VERSION "dbc-export 1 2026.26.6.5"

NS_ :

BS_:

BU_: DAS DI DIF DIR EPAS3P ESP IBST PM PMF PMR RCM VCBATT0 VCCC VCFRONT VCLEFT VCRIGHT

BO_ 914 EPAS3P_alertMatrix: 8 EPAS3P
 SG_ EPAS3P_matrixIndex M : 0|4@1+ (1,0) [0|15] "" Vector__XXX
 SG_ EPAS3P_a001_sent1Mia m0 : 4|1@1+ (1,0) [0|1] "" Vector__XXX
 SG_ EPAS3P_a002_sent1Error m0 : 5|1@1+ (1,0) [0|1] "" Vector__XXX
 SG_ EPAS3P_a003_trqSens1Supply m0 : 6|1@1+ (1,0) [0|1] "" Vector__XXX
 SG_ EPAS3P_a004_trqSens1Eeprom m0 : 7|1@1+ (1,0) [0|1] "" Vector__XXX
 SG_ EPAS3P_a005_sent2Mia m0 : 8|1@1+ (1,0) [0|1] "" Vector__XXX
 SG_ EPAS3P_a006_sent2Error m0 : 9|1@1+ (1,0) [0|1] "" Vector__XXX
 SG_ EPAS3P_a007_trqSens2Supply m0 : 10|1@1+ (1,0) [0|1] "" Vector__XXX
 SG_ EPAS3P_a008_trqSens2Eeprom m0 : 11|1@1+ (1,0) [0|1] "" Vector__XXX
 SG_ EPAS3P_a009_sentDiff m0 : 12|1@1+ (1,0) [0|1] "" Vector__XXX
 SG_ EPAS3P_a010_trqSensCalError m0 : 13|1@1+ (1,0) [0|1] "" Vector__XXX
 SG_ EPAS3P_a011_currentSensError m0 : 14|1@1+ (1,0) [0|1] "" Vector__XXX
 SG_ EPAS3P_a012_currentSensCalError m0 : 15|1@1+ (1,0) [0|1] "" Vector__XXX
 SG_ EPAS3P_a013_gateDriveError m0 : 16|1@1+ (1,0) [0|1] "" Vector__XXX
 SG_ EPAS3P_a014_gateDriveTxError m0 : 17|1@1+ (1,0) [0|1] "" Vector__XXX
 SG_ EPAS3P_a015_gateDriveEeprom m0 : 18|1@1+ (1,0) [0|1] "" Vector__XXX
 SG_ EPAS3P_a016_phaseUhighUv m0 : 19|1@1+ (1,0) [0|1] "" Vector__XXX
 SG_ EPAS3P_a017_phaseUlowUv m0 : 20|1@1+ (1,0) [0|1] "" Vector__XXX
 SG_ EPAS3P_a018_phaseVhighUv m0 : 21|1@1+ (1,0) [0|1] "" Vector__XXX
 SG_ EPAS3P_a019_phaseVlowUv m0 : 22|1@1+ (1,0) [0|1] "" Vector__XXX
 SG_ EPAS3P_a020_phaseWhighUv m0 : 23|1@1+ (1,0) [0|1] "" Vector__XXX
 SG_ EPAS3P_a021_phaseWlowUv m0 : 24|1@1+ (1,0) [0|1] "" Vector__XXX
 SG_ EPAS3P_a022_phaseUhighOv m0 : 25|1@1+ (1,0) [0|1] "" Vector__XXX
 SG_ EPAS3P_a023_phaseUlowOv m0 : 26|1@1+ (1,0) [0|1] "" Vector__XXX
 SG_ EPAS3P_a024_phaseVhighOv m0 : 27|1@1+ (1,0) [0|1] "" Vector__XXX
 SG_ EPAS3P_a025_phaseVlowOv m0 : 28|1@1+ (1,0) [0|1] "" Vector__XXX
 SG_ EPAS3P_a026_phaseWhighOv m0 : 29|1@1+ (1,0) [0|1] "" Vector__XXX
 SG_ EPAS3P_a027_phaseWlowOv m0 : 30|1@1+ (1,0) [0|1] "" Vector__XXX
 SG_ EPAS3P_a028_phaseUbootUv m0 : 31|1@1+ (1,0) [0|1] "" Vector__XXX
 SG_ EPAS3P_a029_phaseVbootUv m0 : 32|1@1+ (1,0) [0|1] "" Vector__XXX
 SG_ EPAS3P_a030_phaseWbootUv m0 : 33|1@1+ (1,0) [0|1] "" Vector__XXX
 SG_ EPAS3P_a031_abnormalShutdown m0 : 34|1@1+ (1,0) [0|1] "" Vector__XXX
 SG_ EPAS3P_a032_vRegOutputUv m0 : 35|1@1+ (1,0) [0|1] "" Vector__XXX
 SG_ EPAS3P_a033_vRegOutputOv m0 : 36|1@1+ (1,0) [0|1] "" Vector__XXX
 SG_ EPAS3P_a034_vRegError m0 : 37|1@1+ (1,0) [0|1] "" Vector__XXX
 SG_ EPAS3P_a035_vbbSupplyUv m0 : 38|1@1+ (1,0) [0|1] "" Vector__XXX
 SG_ EPAS3P_a036_vbbSupplyOv m0 : 39|1@1+ (1,0) [0|1] "" Vector__XXX
 SG_ EPAS3P_a037_motPos1ParityError m0 : 40|1@1+ (1,0) [0|1] "" Vector__XXX
 SG_ EPAS3P_a038_motPos1Uv m0 : 41|1@1+ (1,0) [0|1] "" Vector__XXX
 SG_ EPAS3P_a039_motPos1MagnetMia m0 : 42|1@1+ (1,0) [0|1] "" Vector__XXX
 SG_ EPAS3P_a040_motPos1LogicError m0 : 43|1@1+ (1,0) [0|1] "" Vector__XXX
 SG_ EPAS3P_a041_motPos1tempError m0 : 44|1@1+ (1,0) [0|1] "" Vector__XXX
 SG_ EPAS3P_a042_motPos2ParityError m0 : 45|1@1+ (1,0) [0|1] "" Vector__XXX
 SG_ EPAS3P_a043_motPos2Uv m0 : 46|1@1+ (1,0) [0|1] "" Vector__XXX
 SG_ EPAS3P_a044_motPos2MagnetMia m0 : 47|1@1+ (1,0) [0|1] "" Vector__XXX
 SG_ EPAS3P_a045_motPos2LogicError m0 : 48|1@1+ (1,0) [0|1] "" Vector__XXX
 SG_ EPAS3P_a046_motPos2tempError m0 : 49|1@1+ (1,0) [0|1] "" Vector__XXX
 SG_ EPAS3P_a047_motPosCorrError m0 : 50|1@1+ (1,0) [0|1] "" Vector__XXX
 SG_ EPAS3P_a048_motPosCalError m0 : 51|1@1+ (1,0) [0|1] "" Vector__XXX
 SG_ EPAS3P_a049_piCtrlError m0 : 52|1@1+ (1,0) [0|1] "" Vector__XXX
 SG_ EPAS3P_a050_mcuSmuError m0 : 53|1@1+ (1,0) [0|1] "" Vector__XXX
 SG_ EPAS3P_a051_mcuSupError m0 : 54|1@1+ (1,0) [0|1] "" Vector__XXX
 SG_ EPAS3P_a052_intWatchdogError m0 : 55|1@1+ (1,0) [0|1] "" Vector__XXX
 SG_ EPAS3P_a053_extWatchdogError m0 : 56|1@1+ (1,0) [0|1] "" Vector__XXX
 SG_ EPAS3P_a054_memoryProtectError m0 : 57|1@1+ (1,0) [0|1] "" Vector__XXX
 SG_ EPAS3P_a055_floatPointError m0 : 58|1@1+ (1,0) [0|1] "" Vector__XXX
 SG_ EPAS3P_a056_battUv m0 : 59|1@1+ (1,0) [0|1] "" Vector__XXX
 SG_ EPAS3P_a057_battUvReduced m0 : 60|1@1+ (1,0) [0|1] "" Vector__XXX
 SG_ EPAS3P_a058_battOv m0 : 61|1@1+ (1,0) [0|1] "" Vector__XXX
 SG_ EPAS3P_a059_battOvReduced m0 : 62|1@1+ (1,0) [0|1] "" Vector__XXX
 SG_ EPAS3P_a060_battBridgeDiff m0 : 63|1@1+ (1,0) [0|1] "" Vector__XXX
 SG_ EPAS3P_a061_bridgeUv m1 : 4|1@1+ (1,0) [0|1] "" Vector__XXX
 SG_ EPAS3P_a062_assistCorrError m1 : 5|1@1+ (1,0) [0|1] "" Vector__XXX
 SG_ EPAS3P_a063_dampCorrError m1 : 6|1@1+ (1,0) [0|1] "" Vector__XXX
 SG_ EPAS3P_a064_phaseCompCorrError m1 : 7|1@1+ (1,0) [0|1] "" Vector__XXX
 SG_ EPAS3P_a065_trqTarCorrError m1 : 8|1@1+ (1,0) [0|1] "" Vector__XXX
 SG_ EPAS3P_a066_returnCorrError m1 : 9|1@1+ (1,0) [0|1] "" Vector__XXX
 SG_ EPAS3P_a067_yawDampCorrError m1 : 10|1@1+ (1,0) [0|1] "" Vector__XXX
 SG_ EPAS3P_a068_hystCorrError m1 : 11|1@1+ (1,0) [0|1] "" Vector__XXX
 SG_ EPAS3P_a069_eacCorrError m1 : 12|1@1+ (1,0) [0|1] "" Vector__XXX
 SG_ EPAS3P_a070_hodCorrError m1 : 13|1@1+ (1,0) [0|1] "" Vector__XXX
 SG_ EPAS3P_a071_vehSpdCorrError m1 : 14|1@1+ (1,0) [0|1] "" Vector__XXX
 SG_ EPAS3P_a072_motFeedFwdError m1 : 15|1@1+ (1,0) [0|1] "" Vector__XXX
 SG_ EPAS3P_a073_motParEstError m1 : 16|1@1+ (1,0) [0|1] "" Vector__XXX
 SG_ EPAS3P_a074_overHeatProtect m1 : 17|1@1+ (1,0) [0|1] "" Vector__XXX
 SG_ EPAS3P_a075_fspPwrCut m1 : 18|1@1+ (1,0) [0|1] "" Vector__XXX
 SG_ EPAS3P_a076_tempSensOutofRange m1 : 19|1@1+ (1,0) [0|1] "" Vector__XXX
 SG_ EPAS3P_a077_highSideFetError m1 : 20|1@1+ (1,0) [0|1] "" Vector__XXX
 SG_ EPAS3P_a078_phaseDisconnectError m1 : 21|1@1+ (1,0) [0|1] "" Vector__XXX
 SG_ EPAS3P_a079_backupCurrentPlaus m1 : 22|1@1+ (1,0) [0|1] "" Vector__XXX
 SG_ EPAS3P_a080_ecuInitArbError m1 : 23|1@1+ (1,0) [0|1] "" Vector__XXX
 SG_ EPAS3P_a081_coggCompError m1 : 24|1@1+ (1,0) [0|1] "" Vector__XXX
 SG_ EPAS3P_a082_polarityCalError m1 : 25|1@1+ (1,0) [0|1] "" Vector__XXX
 SG_ EPAS3P_a083_crcMismatch m1 : 26|1@1+ (1,0) [0|1] "" Vector__XXX
 SG_ EPAS3P_a084_eacCancelled m1 : 27|1@1+ (1,0) [0|1] "" Vector__XXX
 SG_ EPAS3P_a085_canBusOff m1 : 28|1@1+ (1,0) [0|1] "" Vector__XXX
 SG_ EPAS3P_a086_dasMia m1 : 29|1@1+ (1,0) [0|1] "" Vector__XXX
 SG_ EPAS3P_a087_dasCntError m1 : 30|1@1+ (1,0) [0|1] "" Vector__XXX
 SG_ EPAS3P_a088_dasCsError m1 : 31|1@1+ (1,0) [0|1] "" Vector__XXX
 SG_ EPAS3P_a089_espWsMia m1 : 32|1@1+ (1,0) [0|1] "" Vector__XXX
 SG_ EPAS3P_a090_espWsCntError m1 : 33|1@1+ (1,0) [0|1] "" Vector__XXX
 SG_ EPAS3P_a091_espWsCsError m1 : 34|1@1+ (1,0) [0|1] "" Vector__XXX
 SG_ EPAS3P_a092_espWrMia m1 : 35|1@1+ (1,0) [0|1] "" Vector__XXX
 SG_ EPAS3P_a093_espWrCntError m1 : 36|1@1+ (1,0) [0|1] "" Vector__XXX
 SG_ EPAS3P_a094_espWrCsError m1 : 37|1@1+ (1,0) [0|1] "" Vector__XXX
 SG_ EPAS3P_a095_espWsStatus m1 : 38|1@1+ (1,0) [0|1] "" Vector__XXX
 SG_ EPAS3P_a096_rcmMia m1 : 39|1@1+ (1,0) [0|1] "" Vector__XXX
 SG_ EPAS3P_a097_rcmCntError m1 : 40|1@1+ (1,0) [0|1] "" Vector__XXX
 SG_ EPAS3P_a098_rcmCsError m1 : 41|1@1+ (1,0) [0|1] "" Vector__XXX
 SG_ EPAS3P_a099_yawRateStatus m1 : 42|1@1+ (1,0) [0|1] "" Vector__XXX
 SG_ EPAS3P_a100_diMia m1 : 43|1@1+ (1,0) [0|1] "" Vector__XXX
 SG_ EPAS3P_a101_diCntError m1 : 44|1@1+ (1,0) [0|1] "" Vector__XXX
 SG_ EPAS3P_a102_diCsError m1 : 45|1@1+ (1,0) [0|1] "" Vector__XXX
 SG_ EPAS3P_a103_vcFrontMia m1 : 46|1@1+ (1,0) [0|1] "" Vector__XXX
 SG_ EPAS3P_a104_vcFrontCntError m1 : 47|1@1+ (1,0) [0|1] "" Vector__XXX
 SG_ EPAS3P_a105_vcFrontCsError m1 : 48|1@1+ (1,0) [0|1] "" Vector__XXX
 SG_ EPAS3P_a106_vcFrontTempMia m1 : 49|1@1+ (1,0) [0|1] "" Vector__XXX
 SG_ EPAS3P_a107_uiTuneReqMia m1 : 50|1@1+ (1,0) [0|1] "" Vector__XXX
 SG_ EPAS3P_a108_uiTuneReqCntError m1 : 51|1@1+ (1,0) [0|1] "" Vector__XXX
 SG_ EPAS3P_a109_uiTuneReqCsError m1 : 52|1@1+ (1,0) [0|1] "" Vector__XXX
 SG_ EPAS3P_a110_sasMia m1 : 53|1@1+ (1,0) [0|1] "" Vector__XXX
 SG_ EPAS3P_a111_sasCntError m1 : 54|1@1+ (1,0) [0|1] "" Vector__XXX
 SG_ EPAS3P_a112_sasCsError m1 : 55|1@1+ (1,0) [0|1] "" Vector__XXX
 SG_ EPAS3P_a113_sasStatusError m1 : 56|1@1+ (1,0) [0|1] "" Vector__XXX
 SG_ EPAS3P_a114_gtwConfigMia m1 : 57|1@1+ (1,0) [0|1] "" Vector__XXX
 SG_ EPAS3P_a115_ecuStatMia m1 : 58|1@1+ (1,0) [0|1] "" Vector__XXX
 SG_ EPAS3P_a116_ecuStatCntError m1 : 59|1@1+ (1,0) [0|1] "" Vector__XXX
 SG_ EPAS3P_a117_ecuStatCrcError m1 : 60|1@1+ (1,0) [0|1] "" Vector__XXX
 SG_ EPAS3P_a118_privateBusOff m1 : 61|1@1+ (1,0) [0|1] "" Vector__XXX
 SG_ EPAS3P_a119_pvtEcuStatMia m1 : 62|1@1+ (1,0) [0|1] "" Vector__XXX
 SG_ EPAS3P_a120_pvtEcuStatCntError m1 : 63|1@1+ (1,0) [0|1] "" Vector__XXX
 SG_ EPAS3P_a121_pvtEcuStatCrcError m2 : 4|1@1+ (1,0) [0|1] "" Vector__XXX
 SG_ EPAS3P_a122_olpActive m2 : 5|1@1+ (1,0) [0|1] "" Vector__XXX
 SG_ EPAS3P_a123_combEcu2StatFail m2 : 6|1@1+ (1,0) [0|1] "" Vector__XXX
 SG_ EPAS3P_a124_tempSensStuckInRange m2 : 7|1@1+ (1,0) [0|1] "" Vector__XXX
 SG_ EPAS3P_a125_trqSensTrimOutRange m2 : 8|1@1+ (1,0) [0|1] "" Vector__XXX
 SG_ EPAS3P_a126_apsMia m2 : 9|1@1+ (1,0) [0|1] "" Vector__XXX
 SG_ EPAS3P_a127_apsCntError m2 : 10|1@1+ (1,0) [0|1] "" Vector__XXX
 SG_ EPAS3P_a128_apsCsError m2 : 11|1@1+ (1,0) [0|1] "" Vector__XXX
 SG_ EPAS3P_a129_combEcu1StatFail m2 : 12|1@1+ (1,0) [0|1] "" Vector__XXX
 SG_ EPAS3P_a130_sasOffsetNotCal m2 : 13|1@1+ (1,0) [0|1] "" Vector__XXX
 SG_ EPAS3P_a131_phaseFeedbackError m2 : 14|1@1+ (1,0) [0|1] "" Vector__XXX
 SG_ EPAS3P_a132_motFeedFwdCounter25 m2 : 15|1@1+ (1,0) [0|1] "" Vector__XXX
 SG_ EPAS3P_a133_motFeedFwdCounter50 m2 : 16|1@1+ (1,0) [0|1] "" Vector__XXX
 SG_ EPAS3P_a134_motFeedFwdCounter85 m2 : 17|1@1+ (1,0) [0|1] "" Vector__XXX
 SG_ EPAS3P_a135_piCtrlCounter25 m2 : 18|1@1+ (1,0) [0|1] "" Vector__XXX
 SG_ EPAS3P_a136_piCtrlCounter50 m2 : 19|1@1+ (1,0) [0|1] "" Vector__XXX
 SG_ EPAS3P_a137_piCtrlCounter85 m2 : 20|1@1+ (1,0) [0|1] "" Vector__XXX
 SG_ EPAS3P_a144_diSpdMia m2 : 21|1@1+ (1,0) [0|1] "" Vector__XXX
 SG_ EPAS3P_a145_diSpdCntError m2 : 22|1@1+ (1,0) [0|1] "" Vector__XXX
 SG_ EPAS3P_a146_diSpdCsError m2 : 23|1@1+ (1,0) [0|1] "" Vector__XXX
 SG_ EPAS3P_a147_backupVehSpeed m2 : 24|1@1+ (1,0) [0|1] "" Vector__XXX
 SG_ EPAS3P_a148_vMaxAssist m2 : 25|1@1+ (1,0) [0|1] "" Vector__XXX
 SG_ EPAS3P_a149_currentSensPathSwitc m2 : 26|1@1+ (1,0) [0|1] "" Vector__XXX
 SG_ EPAS3P_a150_currentSensOffsetDet m2 : 27|1@1+ (1,0) [0|1] "" Vector__XXX
 SG_ EPAS3P_a151_dcsCboot m2 : 28|1@1+ (1,0) [0|1] "" Vector__XXX
 SG_ EPAS3P_a152_dcsDiagReg m2 : 29|1@1+ (1,0) [0|1] "" Vector__XXX
 SG_ EPAS3P_a153_dcsInitOffset m2 : 30|1@1+ (1,0) [0|1] "" Vector__XXX
 SG_ EPAS3P_a154_assistTorqueDisabled m2 : 31|1@1+ (1,0) [0|1] "" Vector__XXX
 SG_ EPAS3P_a155_backupEacActive m2 : 32|1@1+ (1,0) [0|1] "" Vector__XXX
 SG_ EPAS3P_a156_angleSensorDivergenc m2 : 33|1@1+ (1,0) [0|1] "" Vector__XXX
 SG_ EPAS3P_a157_pmState2Mia m2 : 34|1@1+ (1,0) [0|1] "" Vector__XXX
 SG_ EPAS3P_a158_pmState2CntError m2 : 35|1@1+ (1,0) [0|1] "" Vector__XXX
 SG_ EPAS3P_a159_pmState2CsError m2 : 36|1@1+ (1,0) [0|1] "" Vector__XXX
 SG_ EPAS3P_a160_latentFaultTestResul m2 : 37|1@1+ (1,0) [0|1] "" Vector__XXX
 SG_ EPAS3P_a161_initTestPhaDisconnIn m2 : 38|1@1+ (1,0) [0|1] "" Vector__XXX
 SG_ EPAS3P_a162_initTestHSDFetInfo m2 : 39|1@1+ (1,0) [0|1] "" Vector__XXX
 SG_ EPAS3P_a163_initTestGateDrvrInfo m2 : 40|1@1+ (1,0) [0|1] "" Vector__XXX
 SG_ EPAS3P_a164_initTestDCSInfo m2 : 41|1@1+ (1,0) [0|1] "" Vector__XXX
 SG_ EPAS3P_a165_epbStatusMia m2 : 42|1@1+ (1,0) [0|1] "" Vector__XXX
 SG_ EPAS3P_a166_epbStatusCntError m2 : 43|1@1+ (1,0) [0|1] "" Vector__XXX
 SG_ EPAS3P_a167_epbStatusCsError m2 : 44|1@1+ (1,0) [0|1] "" Vector__XXX
 SG_ EPAS3P_a168_torsionBarTorqueQfDe m2 : 45|1@1+ (1,0) [0|1] "" Vector__XXX
 SG_ EPAS3P_a169_difMia m2 : 46|1@1+ (1,0) [0|1] "" Vector__XXX
 SG_ EPAS3P_a170_difCntError m2 : 47|1@1+ (1,0) [0|1] "" Vector__XXX
 SG_ EPAS3P_a171_difCsError m2 : 48|1@1+ (1,0) [0|1] "" Vector__XXX

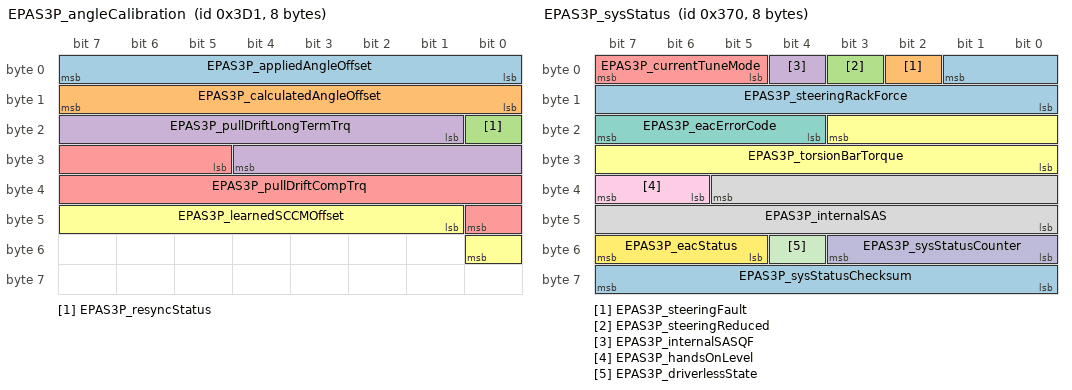
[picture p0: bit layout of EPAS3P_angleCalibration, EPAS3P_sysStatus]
BO_ 977 EPAS3P_angleCalibration: 8 EPAS3P
 SG_ EPAS3P_appliedAngleOffset : 0|8@1+ (0.1,-12.8) [-12.8|12.7] "deg" Vector__XXX
 SG_ EPAS3P_calculatedAngleOffset : 8|8@1+ (0.1,-12.8) [-12.8|12.7] "deg" Vector__XXX
 SG_ EPAS3P_resyncStatus : 16|1@1+ (1,0) [0|1] "" Vector__XXX
 SG_ EPAS3P_pullDriftLongTermTrq : 17|12@1+ (0.01,-10) [-10|10] "Nm" Vector__XXX
 SG_ EPAS3P_pullDriftCompTrq : 29|12@1+ (0.01,-10) [-10|10] "Nm" Vector__XXX
 SG_ EPAS3P_learnedSCCMOffset : 41|8@1+ (0.1,-12.8) [-12.8|12.7] "deg" Vector__XXX

BO_ 817 EPAS3P_info: 8 EPAS3P
 SG_ EPAS3P_infoIndex M : 0|8@1+ (1,0) [0|255] "" Vector__XXX
 SG_ EPAS3P_infoBuildType m10 : 8|8@1+ (1,0) [0|255] "" Vector__XXX
 SG_ EPAS3P_infoComponentID m10 : 48|16@1+ (1,0) [0|65535] "" Vector__XXX
 SG_ EPAS3P_infoPcbaID m11 : 16|8@1+ (1,0) [0|255] "" Vector__XXX
 SG_ EPAS3P_infoAssemblyID m11 : 24|8@1+ (1,0) [0|255] "" Vector__XXX
 SG_ EPAS3P_infoUsageID m11 : 32|16@1+ (1,0) [0|65535] "" Vector__XXX
 SG_ EPAS3P_infoApplicationCRC m13 : 32|32@1+ (1,0) [0|4294967295] "" Vector__XXX
 SG_ EPAS3P_infoBootUdsProtoVersion m20 : 8|8@1+ (1,0) [0|255] "" Vector__XXX
 SG_ EPAS3P_infoBootloaderCRC m20 : 32|32@1+ (1,0) [0|4294967295] "" Vector__XXX
 SG_ EPAS3P_infoSubcomponent2 m23 : 32|32@1+ (1,0) [0|4294967295] "" Vector__XXX

BO_ 880 EPAS3P_sysStatus: 8 EPAS3P
 SG_ EPAS3P_steeringRackForce : 1|10@0+ (50,-25575) [-25575|25525] "N" Vector__XXX
 SG_ EPAS3P_steeringFault : 2|1@1+ (1,0) [0|1] "" Vector__XXX
 SG_ EPAS3P_steeringReduced : 3|1@1+ (1,0) [0|1] "" Vector__XXX
 SG_ EPAS3P_internalSASQF : 4|1@1+ (1,0) [0|1] "" Vector__XXX
 SG_ EPAS3P_currentTuneMode : 5|3@1+ (1,0) [0|7] "" Vector__XXX
 SG_ EPAS3P_torsionBarTorque : 19|12@0+ (0.01,-20.5) [-20.5|20.44] "Nm" Vector__XXX
 SG_ EPAS3P_eacErrorCode : 20|4@1+ (1,0) [0|14] "" Vector__XXX
 SG_ EPAS3P_internalSAS : 37|14@0+ (0.1,-819.2) [-819.2|819] "deg" Vector__XXX
 SG_ EPAS3P_handsOnLevel : 38|2@1+ (1,0) [0|3] "" Vector__XXX
 SG_ EPAS3P_sysStatusCounter : 48|4@1+ (1,0) [0|15] "" Vector__XXX
 SG_ EPAS3P_driverlessState : 52|1@1+ (1,0) [0|1] "" Vector__XXX
 SG_ EPAS3P_eacStatus : 53|3@1+ (1,0) [0|7] "" Vector__XXX
 SG_ EPAS3P_sysStatusChecksum : 56|8@1+ (1,0) [0|255] "" Vector__XXX

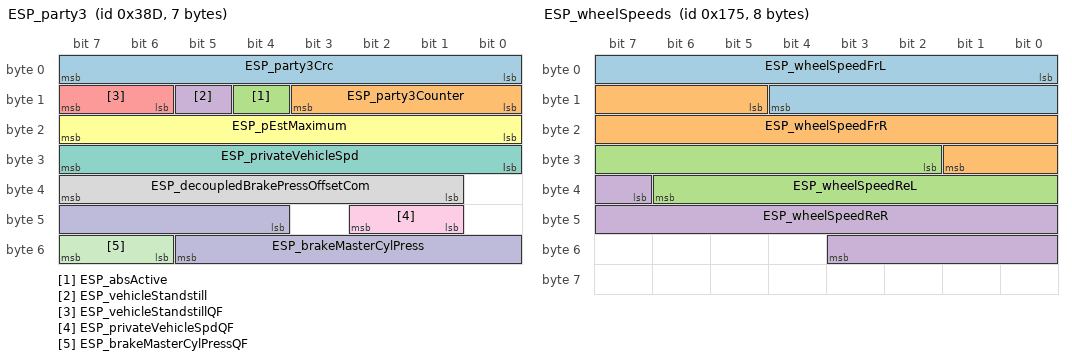
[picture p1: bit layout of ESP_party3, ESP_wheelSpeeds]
BO_ 909 ESP_party3: 7 ESP
 SG_ ESP_party3Crc : 0|8@1+ (1,0) [0|255] "" Vector__XXX
 SG_ ESP_party3Counter : 8|4@1+ (1,0) [0|15] "" Vector__XXX
 SG_ ESP_absActive : 12|1@1+ (1,0) [0|1] "" Vector__XXX
 SG_ ESP_vehicleStandstill : 13|1@1+ (1,0) [0|1] "" Vector__XXX
 SG_ ESP_vehicleStandstillQF : 14|2@1+ (1,0) [0|3] "" Vector__XXX
 SG_ ESP_pEstMaximum : 16|8@1+ (1,0) [0|255] "bar" Vector__XXX
 SG_ ESP_privateVehicleSpd : 24|8@1+ (0.4,0) [0|102] "m/s" Vector__XXX
 SG_ ESP_decoupledBrakePressOffsetCom : 33|7@1+ (0.25,-16) [-16|15.5] "bar" Vector__XXX
 SG_ ESP_privateVehicleSpdQF : 41|2@1+ (1,0) [0|3] "" Vector__XXX
 SG_ ESP_brakeMasterCylPress : 44|10@1+ (0.3,-30) [-30|276.6] "bar" Vector__XXX
 SG_ ESP_brakeMasterCylPressQF : 54|2@1+ (1,0) [0|3] "" Vector__XXX

BO_ 325 ESP_status: 8 ESP
 SG_ ESP_statusChecksum : 0|8@1+ (1,0) [0|255] "" Vector__XXX
 SG_ ESP_statusCounter : 8|4@1+ (1,0) [0|15] "" Vector__XXX
 SG_ ESP_espModeActive : 12|2@1+ (1,0) [0|3] "" Vector__XXX
 SG_ ESP_stabilityControlSts2 : 14|2@1+ (1,0) [0|3] "" Vector__XXX
 SG_ ESP_ebdFaultLamp : 16|1@1+ (1,0) [0|1] "" Vector__XXX
 SG_ ESP_absFaultLamp : 17|1@1+ (1,0) [0|1] "" Vector__XXX
 SG_ ESP_espFaultLamp : 18|1@1+ (1,0) [0|1] "" Vector__XXX
 SG_ ESP_hydraulicBoostEnabled : 19|1@1+ (1,0) [0|1] "" Vector__XXX
 SG_ ESP_espLampFlash : 20|1@1+ (1,0) [0|1] "" Vector__XXX
 SG_ ESP_brakeLamp : 21|1@1+ (1,0) [0|1] "" Vector__XXX
 SG_ ESP_absBrakeEvent2 : 22|2@1+ (1,0) [0|3] "" Vector__XXX
 SG_ ESP_longitudinalAccelQF : 24|1@1+ (1,0) [0|1] "" Vector__XXX
 SG_ ESP_lateralAccelQF : 25|1@1+ (1,0) [0|1] "" Vector__XXX
 SG_ ESP_yawRateQF : 26|1@1+ (1,0) [0|1] "" Vector__XXX
 SG_ ESP_steeringAngleQF : 27|1@1+ (1,0) [0|1] "" Vector__XXX
 SG_ ESP_brakeDiscWipingActive : 28|1@1+ (1,0) [0|1] "" Vector__XXX
 SG_ ESP_driverBrakeApply : 29|2@1+ (1,0) [0|2] "" Vector__XXX
 SG_ ESP_brakeApply : 31|1@1+ (1,0) [0|1] "" Vector__XXX
 SG_ ESP_aesPrimaryActuatorStatus : 32|2@1+ (1,0) [0|3] "" Vector__XXX
 SG_ ESP_cdpStatus : 34|2@1+ (1,0) [0|3] "" Vector__XXX
 SG_ ESP_ptcTargetState : 36|2@1+ (1,0) [0|2] "" Vector__XXX
 SG_ ESP_btcTargetState : 38|2@1+ (1,0) [0|2] "" Vector__XXX
 SG_ ESP_decoupledBrakePressEst : 40|8@1+ (1,-30) [-30|224] "bar" Vector__XXX
 SG_ ESP_ebrStandstillSkid : 48|1@1+ (1,0) [0|1] "" Vector__XXX
 SG_ ESP_ebrStatus : 49|2@1+ (1,0) [0|3] "" Vector__XXX
 SG_ ESP_brakeTorqueTarget : 51|13@1+ (3,0) [0|24573] "Nm" Vector__XXX

BO_ 373 ESP_wheelSpeeds: 8 ESP
 SG_ ESP_wheelSpeedFrL : 0|13@1+ (0.042,0) [0|343.98] "km/h" Vector__XXX
 SG_ ESP_wheelSpeedFrR : 13|13@1+ (0.042,0) [0|343.98] "km/h" Vector__XXX
 SG_ ESP_wheelSpeedReL : 26|13@1+ (0.042,0) [0|343.98] "km/h" Vector__XXX
 SG_ ESP_wheelSpeedReR : 39|13@1+ (0.042,0) [0|343.98] "km/h" Vector__XXX

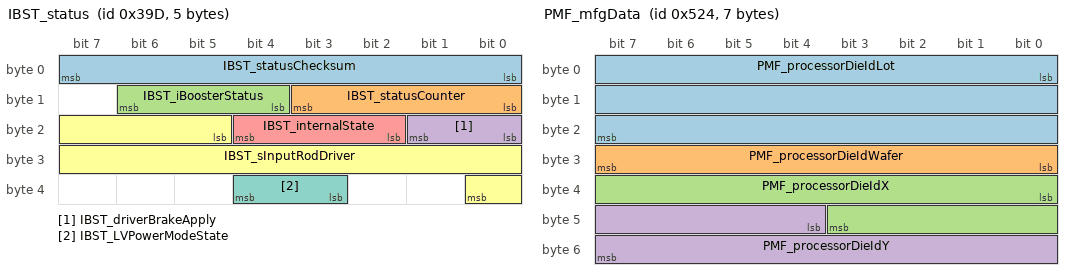
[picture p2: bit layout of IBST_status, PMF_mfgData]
BO_ 925 IBST_status: 5 IBST
 SG_ IBST_statusChecksum : 0|8@1+ (1,0) [0|255] "" Vector__XXX
 SG_ IBST_statusCounter : 8|4@1+ (1,0) [0|15] "" Vector__XXX
 SG_ IBST_iBoosterStatus : 12|3@1+ (1,0) [0|7] "" Vector__XXX
 SG_ IBST_driverBrakeApply : 16|2@1+ (1,0) [0|3] "" Vector__XXX
 SG_ IBST_internalState : 18|3@1+ (1,0) [0|7] "" Vector__XXX
 SG_ IBST_sInputRodDriver : 21|12@1+ (0.015625,-5) [-5|47] "mm" Vector__XXX
 SG_ IBST_LVPowerModeState : 35|2@1+ (1,0) [0|3] "" Vector__XXX

BO_ 1316 PMF_mfgData: 7 PMF
 SG_ PMF_processorDieIdLot : 0|24@1+ (1,0) [0|16777215] "" Vector__XXX
 SG_ PMF_processorDieIdWafer : 24|8@1+ (1,0) [0|255] "" Vector__XXX
 SG_ PMF_processorDieIdX : 32|12@1+ (1,0) [0|4095] "" Vector__XXX
 SG_ PMF_processorDieIdY : 44|12@1+ (1,0) [0|4095] "" Vector__XXX

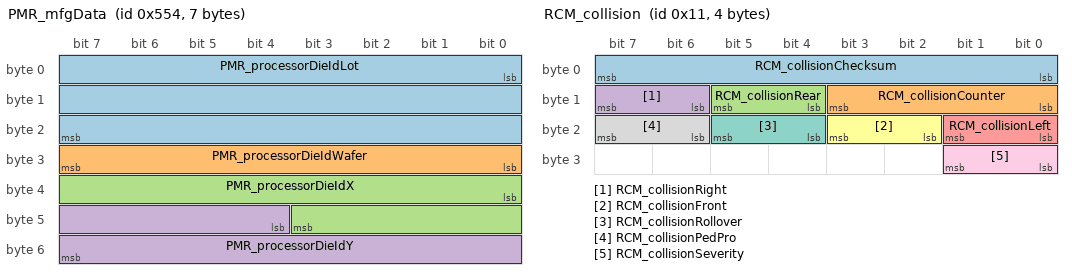
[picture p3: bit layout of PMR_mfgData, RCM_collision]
BO_ 1364 PMR_mfgData: 7 PMR
 SG_ PMR_processorDieIdLot : 0|24@1+ (1,0) [0|16777215] "" Vector__XXX
 SG_ PMR_processorDieIdWafer : 24|8@1+ (1,0) [0|255] "" Vector__XXX
 SG_ PMR_processorDieIdX : 32|12@1+ (1,0) [0|4095] "" Vector__XXX
 SG_ PMR_processorDieIdY : 44|12@1+ (1,0) [0|4095] "" Vector__XXX

BO_ 1973 PM_itpmsDisplay: 3 PM
 SG_ PM_itpmsDisplaySelector M : 0|2@1+ (1,0) [0|3] "" Vector__XXX
 SG_ PM_indirectTPMSTellTale m0 : 2|2@1+ (1,0) [0|3] "" Vector__XXX
 SG_ PM_indirectTPMSDisplayState m0 : 4|2@1+ (1,0) [0|3] "" Vector__XXX
 SG_ PM_indirectTPMSDisplayProgress m0 : 8|5@1+ (0.05,0) [0|1] "-" Vector__XXX
 SG_ PM_indirectTPMSDisplayWarningInd m0 : 13|2@1+ (1,0) [0|3] "" Vector__XXX
 SG_ PM_indirectTPMSDisplayWarni_0001 m0 : 16|2@1+ (1,0) [0|3] "" Vector__XXX
 SG_ PM_indirectTPMSDisplayWarni_0002 m0 : 18|2@1+ (1,0) [0|3] "" Vector__XXX
 SG_ PM_indirectTPMSDisplayWarni_0003 m0 : 20|2@1+ (1,0) [0|3] "" Vector__XXX
 SG_ PM_indirectTPMSRecommendedColdPr m1 : 8|8@1+ (0.025,0) [0|6.35] "bar" Vector__XXX
 SG_ PM_indirectTPMSRecommendedC_0001 m1 : 16|8@1+ (0.025,0) [0|6.35] "bar" Vector__XXX
 SG_ PM_fusedPressureEstimateFrL m2 : 2|9@1+ (0.008,0) [0|4] "bar" Vector__XXX
 SG_ PM_fusedPressureEstimateFrR m2 : 11|9@1+ (0.008,0) [0|4] "bar" Vector__XXX
 SG_ PM_fusedPressureEstimateReL m3 : 2|9@1+ (0.008,0) [0|4] "bar" Vector__XXX
 SG_ PM_fusedPressureEstimateReR m3 : 11|9@1+ (0.008,0) [0|4] "bar" Vector__XXX

BO_ 2038 PM_vdcDebug: 8 PM
 SG_ PM_vdcDebugSelector M : 0|6@1+ (1,0) [0|63] "" Vector__XXX
 SG_ PM_VDCA_TCSlipTargetMod_RA_Fwd m5 : 8|6@1- (0.1,0) [-3|3] "m/s" Vector__XXX
 SG_ PM_VDCA_TCSlipTargetMod_RA_Rwd m5 : 16|6@1- (0.1,0) [-3|3] "m/s" Vector__XXX
 SG_ PM_VSE_forceY_RA m5 : 22|9@1- (40,240) [-10000|10440] "N" Vector__XXX
 SG_ PM_VDCT_observerSlipAngle_RA m5 : 31|9@1- (0.005,0.03) [-1.25|1.305] "rad" Vector__XXX
 SG_ PM_VSE_muVehicleFxLow m5 : 40|5@1+ (0.05,0) [0|1.55] "mu" Vector__XXX
 SG_ PM_VE_fxmFres m13 : 8|8@1- (200,0) [-20000|20000] "N" Vector__XXX
 SG_ PM_VE_fxAccelMass m13 : 16|8@1- (0.16,0) [-20|20] "m/s^2" Vector__XXX
 SG_ PM_VE_vxDotGrade m13 : 24|8@1- (0.1,0.8) [-12|13.5] "m/s^2" Vector__XXX
 SG_ PM_VE_betaEst m13 : 32|8@1- (0.01,0) [-1|1] "rad" Vector__XXX
 SG_ PM_VSE_muVehicleFxHigh m13 : 40|5@1+ (0.05,0) [0|1.55] "mu" Vector__XXX
 SG_ PM_VSE_muVehicleDecLeakRate m29 : 6|5@1+ (0.05,0) [0|1.55] "mu" Vector__XXX
 SG_ PM_VSE_muVehicleLearnDown m29 : 11|5@1+ (0.05,0) [0|1.55] "mu" Vector__XXX
 SG_ PM_VSE_muVehicleDecFilter m29 : 16|5@1+ (0.05,0) [0|1.55] "mu" Vector__XXX
 SG_ PM_VSE_muVehicleLatDecLeakRate m29 : 21|5@1+ (0.05,0) [0|1.55] "mu" Vector__XXX
 SG_ PM_VSE_splitMuProbability m29 : 26|5@1+ (0.05,0) [0|1.55] "probability" Vector__XXX
 SG_ PM_VSE_splitMuTotalMz m29 : 31|9@1- (60,360) [-15000|15660] "Nm" Vector__XXX
 SG_ PM_VSE_attitudeBankAngle m29 : 40|9@1- (0.005,0.03) [-1.25|1.305] "rad" Vector__XXX
 SG_ PM_VSE_attitudeDBetaInControl m29 : 49|8@1- (0.01,0.03) [-1.25|1.3] "rad" Vector__XXX
 SG_ PM_VSE_roadWheelAngleAverage m29 : 57|7@1- (0.015,0.255) [-0.7|1.2] "rad" Vector__XXX

BO_ 17 RCM_collision: 4 RCM
 SG_ RCM_collisionChecksum : 0|8@1+ (1,0) [0|255] "" Vector__XXX
 SG_ RCM_collisionCounter : 8|4@1+ (1,0) [0|15] "" Vector__XXX
 SG_ RCM_collisionRear : 12|2@1+ (1,0) [0|2] "" Vector__XXX
 SG_ RCM_collisionRight : 14|2@1+ (1,0) [0|2] "" Vector__XXX
 SG_ RCM_collisionLeft : 16|2@1+ (1,0) [0|2] "" Vector__XXX
 SG_ RCM_collisionFront : 18|2@1+ (1,0) [0|2] "" Vector__XXX
 SG_ RCM_collisionRollover : 20|2@1+ (1,0) [0|2] "" Vector__XXX
 SG_ RCM_collisionPedPro : 22|2@1+ (1,0) [0|2] "" Vector__XXX
 SG_ RCM_collisionSeverity : 24|2@1+ (1,0) [0|3] "" Vector__XXX

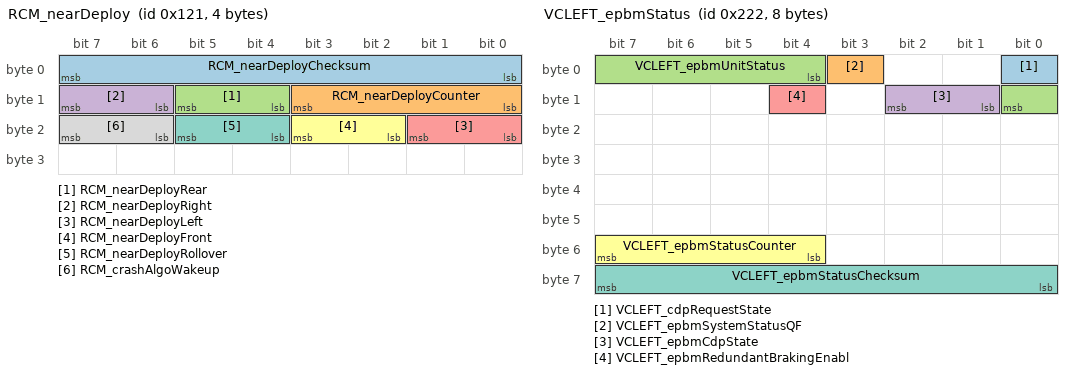
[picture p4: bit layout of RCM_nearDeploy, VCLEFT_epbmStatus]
BO_ 289 RCM_nearDeploy: 4 RCM
 SG_ RCM_nearDeployChecksum : 0|8@1+ (1,0) [0|255] "" Vector__XXX
 SG_ RCM_nearDeployCounter : 8|4@1+ (1,0) [0|15] "" Vector__XXX
 SG_ RCM_nearDeployRear : 12|2@1+ (1,0) [0|2] "" Vector__XXX
 SG_ RCM_nearDeployRight : 14|2@1+ (1,0) [0|2] "" Vector__XXX
 SG_ RCM_nearDeployLeft : 16|2@1+ (1,0) [0|2] "" Vector__XXX
 SG_ RCM_nearDeployFront : 18|2@1+ (1,0) [0|2] "" Vector__XXX
 SG_ RCM_nearDeployRollover : 20|2@1+ (1,0) [0|2] "" Vector__XXX
 SG_ RCM_crashAlgoWakeup : 22|2@1+ (1,0) [0|2] "" Vector__XXX

BO_ 1618 VCBATT0_info: 8 VCBATT0
 SG_ VCBATT0_infoIndex M : 0|8@1+ (1,0) [0|255] "" Vector__XXX
 SG_ VCBATT0_infoBuildType m10 : 8|3@1+ (1,0) [0|7] "" Vector__XXX
 SG_ VCBATT0_infoBuildConfigId m10 : 16|16@1+ (1,0) [0|65535] "" Vector__XXX
 SG_ VCBATT0_infoHardwareId m10 : 32|16@1+ (1,0) [0|65535] "" Vector__XXX
 SG_ VCBATT0_infoComponentId m10 : 48|16@1+ (1,0) [0|65535] "" Vector__XXX
 SG_ VCBATT0_infoPcbaId m11 : 8|8@1+ (1,0) [0|255] "" Vector__XXX
 SG_ VCBATT0_infoAssemblyId m11 : 16|8@1+ (1,0) [0|254] "" Vector__XXX
 SG_ VCBATT0_infoUsageId m11 : 24|16@1+ (1,0) [0|65535] "" Vector__XXX
 SG_ VCBATT0_infoSubUsageId m11 : 40|16@1+ (1,0) [0|65535] "" Vector__XXX
 SG_ VCBATT0_infoAppCrc m13 : 8|32@1+ (1,0) [0|4294967295] "" Vector__XXX
 SG_ VCBATT0_infoAppGitHash m17 : 8|56@1+ (1,0) [0|7.20575940379e+16] "" Vector__XXX
 SG_ VCBATT0_infoBootGitHash m18 : 8|56@1+ (1,0) [0|7.20575940379e+16] "" Vector__XXX
 SG_ VCBATT0_infoBootUdsProtoVersion m20 : 8|16@1+ (1,0) [0|65535] "" Vector__XXX
 SG_ VCBATT0_infoBootCrc m20 : 24|32@1+ (1,0) [0|4294967295] "" Vector__XXX

BO_ 1994 VCCC_info: 8 VCCC
 SG_ VCCC_infoIndex M : 0|8@1+ (1,0) [0|255] "" Vector__XXX
 SG_ VCCC_infoBuildType m10 : 8|8@1+ (1,0) [0|255] "" Vector__XXX
 SG_ VCCC_infoBuildConfigId m10 : 16|16@1+ (1,0) [0|65535] "" Vector__XXX
 SG_ VCCC_infoHardwareId m10 : 32|16@1+ (1,0) [0|65535] "" Vector__XXX
 SG_ VCCC_infoComponentId m10 : 48|16@1+ (1,0) [0|65535] "" Vector__XXX
 SG_ VCCC_infoPcbaId m11 : 8|8@1+ (1,0) [0|255] "" Vector__XXX
 SG_ VCCC_infoAssemblyId m11 : 16|8@1+ (1,0) [0|254] "" Vector__XXX
 SG_ VCCC_infoUsageId m11 : 24|16@1+ (1,0) [0|65535] "" Vector__XXX
 SG_ VCCC_infoSubUsageId m11 : 40|16@1+ (1,0) [0|65535] "" Vector__XXX
 SG_ VCCC_infoAppCrc m13 : 8|32@1+ (1,0) [0|4294967295] "" Vector__XXX
 SG_ VCCC_infoAppGitHash m17 : 8|56@1+ (1,0) [0|7.20575940379e+16] "" Vector__XXX
 SG_ VCCC_infoBootGitHash m18 : 8|56@1+ (1,0) [0|7.20575940379e+16] "" Vector__XXX
 SG_ VCCC_infoBootUdsProtoVersion m20 : 8|8@1+ (1,0) [0|255] "" Vector__XXX
 SG_ VCCC_infoBootCrc m20 : 24|32@1+ (1,0) [0|4294967295] "" Vector__XXX

BO_ 260 VCFRONT_partyDebug: 7 VCFRONT
 SG_ VCFRONT_vcleftHighPower : 0|1@1+ (1,0) [0|1] "" Vector__XXX
 SG_ VCFRONT_vcrightHighPower : 1|1@1+ (1,0) [0|1] "" Vector__XXX
 SG_ VCFRONT_uiHighPower : 2|1@1+ (1,0) [0|1] "" Vector__XXX
 SG_ VCFRONT_5VAStable : 3|1@1+ (1,0) [0|1] "" Vector__XXX
 SG_ VCFRONT_5VBStable : 4|1@1+ (1,0) [0|1] "" Vector__XXX
 SG_ VCFRONT_12VAStable : 5|1@1+ (1,0) [0|1] "" Vector__XXX
 SG_ VCFRONT_12VBStable : 6|1@1+ (1,0) [0|1] "" Vector__XXX
 SG_ VCFRONT_railA : 7|1@1+ (1,0) [0|1] "" Vector__XXX
 SG_ VCFRONT_railB : 8|1@1+ (1,0) [0|1] "" Vector__XXX
 SG_ VCFRONT_chargePumpStable : 9|1@1+ (1,0) [0|1] "" Vector__XXX
 SG_ VCFRONT_vehicleSM : 10|5@1+ (1,0) [0|31] "" Vector__XXX
 SG_ VCFRONT_revBattFault : 15|1@1+ (1,0) [0|1] "" Vector__XXX
 SG_ VCFRONT_battSM : 16|4@1+ (1,0) [0|15] "" Vector__XXX
 SG_ VCFRONT_U13Init : 20|1@1+ (1,0) [0|1] "" Vector__XXX
 SG_ VCFRONT_U16Init : 21|1@1+ (1,0) [0|1] "" Vector__XXX
 SG_ VCFRONT_anyVehLoadShedActiveDBG : 22|1@1+ (1,0) [0|1] "" Vector__XXX
 SG_ VCFRONT_battVoltage : 24|12@1+ (0.005443676,0) [0|22.29185322] "V" Vector__XXX
 SG_ VCFRONT_battCurrent : 40|16@1- (0.005,0) [-163.84|163.835] "A" Vector__XXX

BO_ 258 VCLEFT_doorStatus: 8 VCLEFT
 SG_ VCLEFT_doorClosureStatusFront : 0|4@1+ (1,0) [1|15] "" Vector__XXX
 SG_ VCLEFT_doorClosureStatusRear : 4|4@1+ (1,0) [1|15] "" Vector__XXX
 SG_ VCLEFT_frontLatchSwitch : 8|1@1+ (1,0) [0|1] "" Vector__XXX
 SG_ VCLEFT_rearLatchSwitch : 9|1@1+ (1,0) [0|1] "" Vector__XXX
 SG_ VCLEFT_frontHandlePulled : 10|1@1+ (1,0) [0|1] "" Vector__XXX
 SG_ VCLEFT_rearHandlePulled : 11|1@1+ (1,0) [0|1] "" Vector__XXX
 SG_ VCLEFT_frontRelActuatorSwitch : 12|1@1+ (1,0) [0|1] "" Vector__XXX
 SG_ VCLEFT_rearRelActuatorSwitch : 13|1@1+ (1,0) [0|1] "" Vector__XXX
 SG_ VCLEFT_frontLatchStatus : 14|4@1+ (1,0) [1|15] "" Vector__XXX
 SG_ VCLEFT_rearLatchStatus : 18|4@1+ (1,0) [1|15] "" Vector__XXX
 SG_ VCLEFT_lastDoorReqSourceFront : 22|3@1+ (1,0) [0|7] "" Vector__XXX
 SG_ VCLEFT_lastDoorReqSourceRear : 25|3@1+ (1,0) [0|7] "" Vector__XXX
 SG_ VCLEFT_frontIntSwitchFaulted : 28|1@1+ (1,0) [0|1] "" Vector__XXX
 SG_ VCLEFT_rearIntSwitchFaulted : 29|1@1+ (1,0) [0|1] "" Vector__XXX
 SG_ VCLEFT_frontIntSwitchPressed : 31|1@1+ (1,0) [0|1] "" Vector__XXX
 SG_ VCLEFT_rearIntSwitchPressed : 32|1@1+ (1,0) [0|1] "" Vector__XXX
 SG_ VCLEFT_mirrorTiltXPosition : 33|8@1+ (0.02,0) [0|5] "V" Vector__XXX
 SG_ VCLEFT_mirrorTiltYPosition : 41|8@1+ (0.02,0) [0|5] "V" Vector__XXX
 SG_ VCLEFT_mirrorState : 49|3@1+ (1,0) [0|7] "" Vector__XXX
 SG_ VCLEFT_mirrorFoldState : 52|3@1+ (1,0) [0|7] "" Vector__XXX
 SG_ VCLEFT_mirrorRecallState : 55|3@1+ (1,0) [0|7] "" Vector__XXX
 SG_ VCLEFT_mirrorHeatState : 58|3@1+ (1,0) [1|7] "" Vector__XXX
 SG_ VCLEFT_rearHandlePulledPersist : 61|1@1+ (1,0) [0|1] "" Vector__XXX
 SG_ VCLEFT_frontHandlePulledPersist : 62|1@1+ (1,0) [0|1] "" Vector__XXX
 SG_ VCLEFT_mirrorDipped : 63|1@1+ (1,0) [0|1] "" Vector__XXX

BO_ 546 VCLEFT_epbmStatus: 8 VCLEFT
 SG_ VCLEFT_cdpRequestState : 0|1@1+ (1,0) [0|1] "" Vector__XXX
 SG_ VCLEFT_epbmSystemStatusQF : 3|1@1+ (1,0) [0|1] "" Vector__XXX
 SG_ VCLEFT_epbmUnitStatus : 4|5@1+ (1,0) [0|31] "" Vector__XXX
 SG_ VCLEFT_epbmCdpState : 9|2@1+ (1,0) [0|3] "" Vector__XXX
 SG_ VCLEFT_epbmRedundantBrakingEnabl : 12|1@1+ (1,0) [0|1] "" Vector__XXX
 SG_ VCLEFT_epbmStatusCounter : 52|4@1+ (1,0) [0|15] "" Vector__XXX
 SG_ VCLEFT_epbmStatusChecksum : 56|8@1+ (1,0) [0|255] "" Vector__XXX

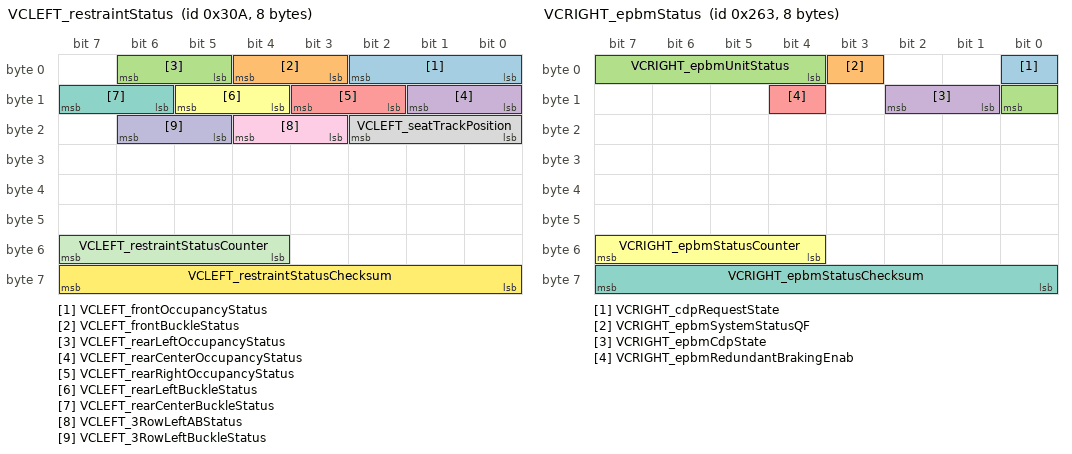
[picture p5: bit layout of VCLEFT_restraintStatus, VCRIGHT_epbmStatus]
BO_ 778 VCLEFT_restraintStatus: 8 VCLEFT
 SG_ VCLEFT_frontOccupancyStatus : 0|3@1+ (1,0) [0|6] "" Vector__XXX
 SG_ VCLEFT_frontBuckleStatus : 3|2@1+ (1,0) [0|3] "" Vector__XXX
 SG_ VCLEFT_rearLeftOccupancyStatus : 5|2@1+ (1,0) [0|3] "" Vector__XXX
 SG_ VCLEFT_rearCenterOccupancyStatus : 8|2@1+ (1,0) [0|3] "" Vector__XXX
 SG_ VCLEFT_rearRightOccupancyStatus : 10|2@1+ (1,0) [0|3] "" Vector__XXX
 SG_ VCLEFT_rearLeftBuckleStatus : 12|2@1+ (1,0) [0|3] "" Vector__XXX
 SG_ VCLEFT_rearCenterBuckleStatus : 14|2@1+ (1,0) [0|3] "" Vector__XXX
 SG_ VCLEFT_seatTrackPosition : 16|3@1+ (1,0) [0|6] "" Vector__XXX
 SG_ VCLEFT_3RowLeftABStatus : 19|2@1+ (1,0) [0|3] "" Vector__XXX
 SG_ VCLEFT_3RowLeftBuckleStatus : 21|2@1+ (1,0) [0|3] "" Vector__XXX
 SG_ VCLEFT_restraintStatusCounter : 52|4@1+ (1,0) [0|15] "" Vector__XXX
 SG_ VCLEFT_restraintStatusChecksum : 56|8@1+ (1,0) [0|255] "" Vector__XXX

BO_ 1124 VCRIGHT_AP_hvacState1Hz: 8 VCRIGHT
 SG_ VCRIGHT_AP_hvacState1HzIndex M : 0|1@1+ (1,0) [0|1] "" Vector__XXX
 SG_ VCRIGHT_AP_tempCameraModele_0001 m0 : 2|8@1+ (0.5,-40) [-40|85] "degC" Vector__XXX
 SG_ VCRIGHT_AP_tempCameraModeledWind m0 : 10|8@1+ (0.5,-40) [-40|85] "degC" Vector__XXX
 SG_ VCRIGHT_AP_cameraModeledWin_0001 m0 : 18|7@1+ (1,0) [0|100] "%" Vector__XXX
 SG_ VCRIGHT_AP_cameraModeledWindshie m0 : 25|7@1+ (1,0) [0|100] "%" Vector__XXX
 SG_ VCRIGHT_AP_maxAchievableASideTem m0 : 32|7@1+ (1,-20) [-20|70] "degC" Vector__XXX
 SG_ VCRIGHT_AP_cameraModeledPocketWa m0 : 42|10@1+ (0.04,0) [0|40] "g/kg" Vector__XXX
 SG_ VCRIGHT_AP_humidityModelInitStat m0 : 52|5@1+ (1,0) [0|31] "" Vector__XXX
 SG_ VCRIGHT_AP_humidityModelStatus m0 : 57|5@1+ (1,0) [0|31] "" Vector__XXX

BO_ 259 VCRIGHT_doorStatus: 8 VCRIGHT
 SG_ VCRIGHT_doorClosureStatusFront : 0|4@1+ (1,0) [1|15] "" Vector__XXX
 SG_ VCRIGHT_doorClosureStatusRear : 4|4@1+ (1,0) [1|15] "" Vector__XXX
 SG_ VCRIGHT_frontLatchSwitch : 8|1@1+ (1,0) [0|1] "" Vector__XXX
 SG_ VCRIGHT_rearLatchSwitch : 9|1@1+ (1,0) [0|1] "" Vector__XXX
 SG_ VCRIGHT_frontHandlePulled : 10|1@1+ (1,0) [0|1] "" Vector__XXX
 SG_ VCRIGHT_rearHandlePulled : 11|1@1+ (1,0) [0|1] "" Vector__XXX
 SG_ VCRIGHT_frontRelActuatorSwitch : 12|1@1+ (1,0) [0|1] "" Vector__XXX
 SG_ VCRIGHT_rearRelActuatorSwitch : 13|1@1+ (1,0) [0|1] "" Vector__XXX
 SG_ VCRIGHT_frontLatchStatus : 14|4@1+ (1,0) [1|15] "" Vector__XXX
 SG_ VCRIGHT_rearLatchStatus : 18|4@1+ (1,0) [1|15] "" Vector__XXX
 SG_ VCRIGHT_lastDoorReqSourceFront : 22|3@1+ (1,0) [0|7] "" Vector__XXX
 SG_ VCRIGHT_lastDoorReqSourceRear : 25|3@1+ (1,0) [0|7] "" Vector__XXX
 SG_ VCRIGHT_frontIntSwitchFaulted : 28|1@1+ (1,0) [0|1] "" Vector__XXX
 SG_ VCRIGHT_rearIntSwitchFaulted : 29|1@1+ (1,0) [0|1] "" Vector__XXX
 SG_ VCRIGHT_frontHandlePulledPersist : 30|1@1+ (1,0) [0|1] "" Vector__XXX
 SG_ VCRIGHT_frontIntSwitchPressed : 31|1@1+ (1,0) [0|1] "" Vector__XXX
 SG_ VCRIGHT_rearIntSwitchPressed : 32|1@1+ (1,0) [0|1] "" Vector__XXX
 SG_ VCRIGHT_mirrorTiltXPosition : 33|8@1+ (0.02,0) [0|5] "V" Vector__XXX
 SG_ VCRIGHT_mirrorTiltYPosition : 41|8@1+ (0.02,0) [0|5] "V" Vector__XXX
 SG_ VCRIGHT_mirrorState : 49|3@1+ (1,0) [0|7] "" Vector__XXX
 SG_ VCRIGHT_mirrorFoldState : 52|3@1+ (1,0) [0|7] "" Vector__XXX
 SG_ VCRIGHT_mirrorDipped : 55|1@1+ (1,0) [0|1] "" Vector__XXX
 SG_ VCRIGHT_trunkLatchStatus : 56|4@1+ (1,0) [1|15] "" Vector__XXX
 SG_ VCRIGHT_mirrorRecallState : 60|3@1+ (1,0) [0|7] "" Vector__XXX
 SG_ VCRIGHT_rearHandlePulledPersist : 63|1@1+ (1,0) [0|1] "" Vector__XXX

BO_ 611 VCRIGHT_epbmStatus: 8 VCRIGHT
 SG_ VCRIGHT_cdpRequestState : 0|1@1+ (1,0) [0|1] "" Vector__XXX
 SG_ VCRIGHT_epbmSystemStatusQF : 3|1@1+ (1,0) [0|1] "" Vector__XXX
 SG_ VCRIGHT_epbmUnitStatus : 4|5@1+ (1,0) [0|31] "" Vector__XXX
 SG_ VCRIGHT_epbmCdpState : 9|2@1+ (1,0) [0|3] "" Vector__XXX
 SG_ VCRIGHT_epbmRedundantBrakingEnab : 12|1@1+ (1,0) [0|1] "" Vector__XXX
 SG_ VCRIGHT_epbmStatusCounter : 52|4@1+ (1,0) [0|15] "" Vector__XXX
 SG_ VCRIGHT_epbmStatusChecksum : 56|8@1+ (1,0) [0|255] "" Vector__XXX

BO_ 794 VCRIGHT_restraintStatus: 8 VCRIGHT
 SG_ VCRIGHT_frontOccupancyStatus : 0|3@1+ (1,0) [0|6] "" Vector__XXX
 SG_ VCRIGHT_frontBuckleStatus : 3|2@1+ (1,0) [0|3] "" Vector__XXX
 SG_ VCRIGHT_rearCenterBuckleStatus : 5|2@1+ (1,0) [0|3] "" Vector__XXX
 SG_ VCRIGHT_rearRightBuckleStatus : 8|2@1+ (1,0) [0|3] "" Vector__XXX
 SG_ VCRIGHT_rearRightOccupancyStatus : 10|2@1+ (1,0) [0|3] "" Vector__XXX
 SG_ VCRIGHT_3RowLeftBuckleStatus : 12|2@1+ (1,0) [0|3] "" Vector__XXX
 SG_ VCRIGHT_3RowRightBuckleStatus : 14|2@1+ (1,0) [0|3] "" Vector__XXX
 SG_ VCRIGHT_3RowLeftOccupancyStatus : 16|2@1+ (1,0) [0|3] "" Vector__XXX
 SG_ VCRIGHT_3RowRightOccupancyStatus : 18|2@1+ (1,0) [0|3] "" Vector__XXX
 SG_ VCRIGHT_seatTrackPosition : 20|3@1+ (1,0) [0|6] "" Vector__XXX
 SG_ VCRIGHT_occupantClassification : 23|3@1+ (1,0) [0|6] "" Vector__XXX
 SG_ VCRIGHT_occupantClassificationQF : 26|1@1+ (1,0) [0|1] "" Vector__XXX
 SG_ VCRIGHT_classificationEnabled : 27|1@1+ (1,0) [0|1] "" Vector__XXX
 SG_ VCRIGHT_classificationEnabledQF : 28|1@1+ (1,0) [0|1] "" Vector__XXX
 SG_ VCRIGHT_3RowRightABStatus : 30|2@1+ (1,0) [0|3] "" Vector__XXX
 SG_ VCRIGHT_restraintStatusCounter : 52|4@1+ (1,0) [0|15] "" Vector__XXX
 SG_ VCRIGHT_restraintStatusChecksum : 56|8@1+ (1,0) [0|255] "" Vector__XXX

BO_TX_BU_ 914 : EPAS3P;
BO_TX_BU_ 977 : EPAS3P;
BO_TX_BU_ 817 : EPAS3P;
BO_TX_BU_ 880 : EPAS3P;
BO_TX_BU_ 909 : ESP;
BO_TX_BU_ 325 : ESP;
BO_TX_BU_ 373 : ESP;
BO_TX_BU_ 925 : IBST;
BO_TX_BU_ 1316 : PMF;
BO_TX_BU_ 1364 : PMR;
BO_TX_BU_ 1973 : PM;
BO_TX_BU_ 2038 : PM;
BO_TX_BU_ 17 : RCM;
BO_TX_BU_ 289 : RCM;
BO_TX_BU_ 1618 : VCBATT0;
BO_TX_BU_ 1994 : VCCC;
BO_TX_BU_ 260 : VCFRONT;
BO_TX_BU_ 258 : VCLEFT;
BO_TX_BU_ 546 : VCLEFT;
BO_TX_BU_ 778 : VCLEFT;
BO_TX_BU_ 1124 : VCRIGHT;
BO_TX_BU_ 259 : VCRIGHT;
BO_TX_BU_ 611 : VCRIGHT;
BO_TX_BU_ 794 : VCRIGHT;
CM_ BO_ 914 "Electric power steering (primary) message: alert matrix; frame length from the layout, not yet observed on a vehicle bus";
CM_ SG_ 914 EPAS3P_matrixIndex "Electric power steering (primary): matrix index";
CM_ SG_ 914 EPAS3P_a001_sent1Mia "Electric power steering (primary): a001 sent1 mia";
CM_ SG_ 914 EPAS3P_a002_sent1Error "Electric power steering (primary): a002 sent1 error";
CM_ SG_ 914 EPAS3P_a003_trqSens1Supply "Electric power steering (primary): a003 trq sens1 supply";
CM_ SG_ 914 EPAS3P_a004_trqSens1Eeprom "Electric power steering (primary): a004 trq sens1 eeprom";
CM_ SG_ 914 EPAS3P_a005_sent2Mia "Electric power steering (primary): a005 sent2 mia";
CM_ SG_ 914 EPAS3P_a006_sent2Error "Electric power steering (primary): a006 sent2 error";
CM_ SG_ 914 EPAS3P_a007_trqSens2Supply "Electric power steering (primary): a007 trq sens2 supply";
CM_ SG_ 914 EPAS3P_a008_trqSens2Eeprom "Electric power steering (primary): a008 trq sens2 eeprom";
CM_ SG_ 914 EPAS3P_a009_sentDiff "Electric power steering (primary): a009 sent diff";
CM_ SG_ 914 EPAS3P_a010_trqSensCalError "Electric power steering (primary): a010 trq sens cal error";
CM_ SG_ 914 EPAS3P_a011_currentSensError "Electric power steering (primary): a011 current sens error";
CM_ SG_ 914 EPAS3P_a012_currentSensCalError "Electric power steering (primary): a012 current sens cal error";
CM_ SG_ 914 EPAS3P_a013_gateDriveError "Electric power steering (primary): a013 gate drive error";
CM_ SG_ 914 EPAS3P_a014_gateDriveTxError "Electric power steering (primary): a014 gate drive tx error";
CM_ SG_ 914 EPAS3P_a015_gateDriveEeprom "Electric power steering (primary): a015 gate drive eeprom";
CM_ SG_ 914 EPAS3P_a016_phaseUhighUv "Electric power steering (primary): a016 phase uhigh uv";
CM_ SG_ 914 EPAS3P_a017_phaseUlowUv "Electric power steering (primary): a017 phase ulow uv";
CM_ SG_ 914 EPAS3P_a018_phaseVhighUv "Electric power steering (primary): a018 phase vhigh uv";
CM_ SG_ 914 EPAS3P_a019_phaseVlowUv "Electric power steering (primary): a019 phase vlow uv";
CM_ SG_ 914 EPAS3P_a020_phaseWhighUv "Electric power steering (primary): a020 phase whigh uv";
CM_ SG_ 914 EPAS3P_a021_phaseWlowUv "Electric power steering (primary): a021 phase wlow uv";
CM_ SG_ 914 EPAS3P_a022_phaseUhighOv "Electric power steering (primary): a022 phase uhigh ov";
CM_ SG_ 914 EPAS3P_a023_phaseUlowOv "Electric power steering (primary): a023 phase ulow ov";
CM_ SG_ 914 EPAS3P_a024_phaseVhighOv "Electric power steering (primary): a024 phase vhigh ov";
CM_ SG_ 914 EPAS3P_a025_phaseVlowOv "Electric power steering (primary): a025 phase vlow ov";
CM_ SG_ 914 EPAS3P_a026_phaseWhighOv "Electric power steering (primary): a026 phase whigh ov";
CM_ SG_ 914 EPAS3P_a027_phaseWlowOv "Electric power steering (primary): a027 phase wlow ov";
CM_ SG_ 914 EPAS3P_a028_phaseUbootUv "Electric power steering (primary): a028 phase uboot uv";
CM_ SG_ 914 EPAS3P_a029_phaseVbootUv "Electric power steering (primary): a029 phase vboot uv";
CM_ SG_ 914 EPAS3P_a030_phaseWbootUv "Electric power steering (primary): a030 phase wboot uv";
CM_ SG_ 914 EPAS3P_a031_abnormalShutdown "Electric power steering (primary): a031 abnormal shutdown";
CM_ SG_ 914 EPAS3P_a032_vRegOutputUv "Electric power steering (primary): a032 v reg output uv";
CM_ SG_ 914 EPAS3P_a033_vRegOutputOv "Electric power steering (primary): a033 v reg output ov";
CM_ SG_ 914 EPAS3P_a034_vRegError "Electric power steering (primary): a034 v reg error";
CM_ SG_ 914 EPAS3P_a035_vbbSupplyUv "Electric power steering (primary): a035 vbb supply uv";
CM_ SG_ 914 EPAS3P_a036_vbbSupplyOv "Electric power steering (primary): a036 vbb supply ov";
CM_ SG_ 914 EPAS3P_a037_motPos1ParityError "Electric power steering (primary): a037 mot pos1 parity error";
CM_ SG_ 914 EPAS3P_a038_motPos1Uv "Electric power steering (primary): a038 mot pos1 uv";
CM_ SG_ 914 EPAS3P_a039_motPos1MagnetMia "Electric power steering (primary): a039 mot pos1 magnet mia";
CM_ SG_ 914 EPAS3P_a040_motPos1LogicError "Electric power steering (primary): a040 mot pos1 logic error";
CM_ SG_ 914 EPAS3P_a041_motPos1tempError "Electric power steering (primary): a041 mot pos1temp error";
CM_ SG_ 914 EPAS3P_a042_motPos2ParityError "Electric power steering (primary): a042 mot pos2 parity error";
CM_ SG_ 914 EPAS3P_a043_motPos2Uv "Electric power steering (primary): a043 mot pos2 uv";
CM_ SG_ 914 EPAS3P_a044_motPos2MagnetMia "Electric power steering (primary): a044 mot pos2 magnet mia";
CM_ SG_ 914 EPAS3P_a045_motPos2LogicError "Electric power steering (primary): a045 mot pos2 logic error";
CM_ SG_ 914 EPAS3P_a046_motPos2tempError "Electric power steering (primary): a046 mot pos2temp error";
CM_ SG_ 914 EPAS3P_a047_motPosCorrError "Electric power steering (primary): a047 mot pos corr error";
CM_ SG_ 914 EPAS3P_a048_motPosCalError "Electric power steering (primary): a048 mot pos cal error";
CM_ SG_ 914 EPAS3P_a049_piCtrlError "Electric power steering (primary): a049 pi ctrl error";
CM_ SG_ 914 EPAS3P_a050_mcuSmuError "Electric power steering (primary): a050 mcu smu error";
CM_ SG_ 914 EPAS3P_a051_mcuSupError "Electric power steering (primary): a051 mcu sup error";
CM_ SG_ 914 EPAS3P_a052_intWatchdogError "Electric power steering (primary): a052 int watchdog error";
CM_ SG_ 914 EPAS3P_a053_extWatchdogError "Electric power steering (primary): a053 ext watchdog error";
CM_ SG_ 914 EPAS3P_a054_memoryProtectError "Electric power steering (primary): a054 memory protect error";
CM_ SG_ 914 EPAS3P_a055_floatPointError "Electric power steering (primary): a055 float point error";
CM_ SG_ 914 EPAS3P_a056_battUv "Electric power steering (primary): a056 batt uv";
CM_ SG_ 914 EPAS3P_a057_battUvReduced "Electric power steering (primary): a057 batt uv reduced";
CM_ SG_ 914 EPAS3P_a058_battOv "Electric power steering (primary): a058 batt ov";
CM_ SG_ 914 EPAS3P_a059_battOvReduced "Electric power steering (primary): a059 batt ov reduced";
CM_ SG_ 914 EPAS3P_a060_battBridgeDiff "Electric power steering (primary): a060 batt bridge diff";
CM_ SG_ 914 EPAS3P_a061_bridgeUv "Electric power steering (primary): a061 bridge uv";
CM_ SG_ 914 EPAS3P_a062_assistCorrError "Electric power steering (primary): a062 assist corr error";
CM_ SG_ 914 EPAS3P_a063_dampCorrError "Electric power steering (primary): a063 damp corr error";
CM_ SG_ 914 EPAS3P_a064_phaseCompCorrError "Electric power steering (primary): a064 phase comp corr error";
CM_ SG_ 914 EPAS3P_a065_trqTarCorrError "Electric power steering (primary): a065 trq tar corr error";
CM_ SG_ 914 EPAS3P_a066_returnCorrError "Electric power steering (primary): a066 return corr error";
CM_ SG_ 914 EPAS3P_a067_yawDampCorrError "Electric power steering (primary): a067 yaw damp corr error";
CM_ SG_ 914 EPAS3P_a068_hystCorrError "Electric power steering (primary): a068 hyst corr error";
CM_ SG_ 914 EPAS3P_a069_eacCorrError "Electric power steering (primary): a069 eac corr error";
CM_ SG_ 914 EPAS3P_a070_hodCorrError "Electric power steering (primary): a070 hod corr error";
CM_ SG_ 914 EPAS3P_a071_vehSpdCorrError "Electric power steering (primary): a071 veh spd corr error";
CM_ SG_ 914 EPAS3P_a072_motFeedFwdError "Electric power steering (primary): a072 mot feed fwd error";
CM_ SG_ 914 EPAS3P_a073_motParEstError "Electric power steering (primary): a073 mot par est error";
CM_ SG_ 914 EPAS3P_a074_overHeatProtect "Electric power steering (primary): a074 over heat protect";
CM_ SG_ 914 EPAS3P_a075_fspPwrCut "Electric power steering (primary): a075 fsp pwr cut";
CM_ SG_ 914 EPAS3P_a076_tempSensOutofRange "Electric power steering (primary): a076 temp sens outof range";
CM_ SG_ 914 EPAS3P_a077_highSideFetError "Electric power steering (primary): a077 high side fet error";
CM_ SG_ 914 EPAS3P_a078_phaseDisconnectError "Electric power steering (primary): a078 phase disconnect error";
CM_ SG_ 914 EPAS3P_a079_backupCurrentPlaus "Electric power steering (primary): a079 backup current plaus";
CM_ SG_ 914 EPAS3P_a080_ecuInitArbError "Electric power steering (primary): a080 ecu init arb error";
CM_ SG_ 914 EPAS3P_a081_coggCompError "Electric power steering (primary): a081 cogg comp error";
CM_ SG_ 914 EPAS3P_a082_polarityCalError "Electric power steering (primary): a082 polarity cal error";
CM_ SG_ 914 EPAS3P_a083_crcMismatch "Electric power steering (primary): a083 crc mismatch";
CM_ SG_ 914 EPAS3P_a084_eacCancelled "Electric power steering (primary): a084 eac cancelled";
CM_ SG_ 914 EPAS3P_a085_canBusOff "Electric power steering (primary): a085 can bus off";
CM_ SG_ 914 EPAS3P_a086_dasMia "Electric power steering (primary): a086 das mia";
CM_ SG_ 914 EPAS3P_a087_dasCntError "Electric power steering (primary): a087 das cnt error";
CM_ SG_ 914 EPAS3P_a088_dasCsError "Electric power steering (primary): a088 das cs error";
CM_ SG_ 914 EPAS3P_a089_espWsMia "Electric power steering (primary): a089 esp ws mia";
CM_ SG_ 914 EPAS3P_a090_espWsCntError "Electric power steering (primary): a090 esp ws cnt error";
CM_ SG_ 914 EPAS3P_a091_espWsCsError "Electric power steering (primary): a091 esp ws cs error";
CM_ SG_ 914 EPAS3P_a092_espWrMia "Electric power steering (primary): a092 esp wr mia";
CM_ SG_ 914 EPAS3P_a093_espWrCntError "Electric power steering (primary): a093 esp wr cnt error";
CM_ SG_ 914 EPAS3P_a094_espWrCsError "Electric power steering (primary): a094 esp wr cs error";
CM_ SG_ 914 EPAS3P_a095_espWsStatus "Electric power steering (primary): a095 esp ws status";
CM_ SG_ 914 EPAS3P_a096_rcmMia "Electric power steering (primary): a096 rcm mia";
CM_ SG_ 914 EPAS3P_a097_rcmCntError "Electric power steering (primary): a097 rcm cnt error";
CM_ SG_ 914 EPAS3P_a098_rcmCsError "Electric power steering (primary): a098 rcm cs error";
CM_ SG_ 914 EPAS3P_a099_yawRateStatus "Electric power steering (primary): a099 yaw rate status";
CM_ SG_ 914 EPAS3P_a100_diMia "Electric power steering (primary): a100 di mia";
CM_ SG_ 914 EPAS3P_a101_diCntError "Electric power steering (primary): a101 di cnt error";
CM_ SG_ 914 EPAS3P_a102_diCsError "Electric power steering (primary): a102 di cs error";
CM_ SG_ 914 EPAS3P_a103_vcFrontMia "Electric power steering (primary): a103 vc front mia";
CM_ SG_ 914 EPAS3P_a104_vcFrontCntError "Electric power steering (primary): a104 vc front cnt error";
CM_ SG_ 914 EPAS3P_a105_vcFrontCsError "Electric power steering (primary): a105 vc front cs error";
CM_ SG_ 914 EPAS3P_a106_vcFrontTempMia "Electric power steering (primary): a106 vc front temp mia";
CM_ SG_ 914 EPAS3P_a107_uiTuneReqMia "Electric power steering (primary): a107 ui tune req mia";
CM_ SG_ 914 EPAS3P_a108_uiTuneReqCntError "Electric power steering (primary): a108 ui tune req cnt error";
CM_ SG_ 914 EPAS3P_a109_uiTuneReqCsError "Electric power steering (primary): a109 ui tune req cs error";
CM_ SG_ 914 EPAS3P_a110_sasMia "Electric power steering (primary): a110 sas mia";
CM_ SG_ 914 EPAS3P_a111_sasCntError "Electric power steering (primary): a111 sas cnt error";
CM_ SG_ 914 EPAS3P_a112_sasCsError "Electric power steering (primary): a112 sas cs error";
CM_ SG_ 914 EPAS3P_a113_sasStatusError "Electric power steering (primary): a113 sas status error";
CM_ SG_ 914 EPAS3P_a114_gtwConfigMia "Electric power steering (primary): a114 gtw config mia";
CM_ SG_ 914 EPAS3P_a115_ecuStatMia "Electric power steering (primary): a115 ecu stat mia";
CM_ SG_ 914 EPAS3P_a116_ecuStatCntError "Electric power steering (primary): a116 ecu stat cnt error";
CM_ SG_ 914 EPAS3P_a117_ecuStatCrcError "Electric power steering (primary): a117 ecu stat crc error";
CM_ SG_ 914 EPAS3P_a118_privateBusOff "Electric power steering (primary): a118 private bus off";
CM_ SG_ 914 EPAS3P_a119_pvtEcuStatMia "Electric power steering (primary): a119 pvt ecu stat mia";
CM_ SG_ 914 EPAS3P_a120_pvtEcuStatCntError "Electric power steering (primary): a120 pvt ecu stat cnt error";
CM_ SG_ 914 EPAS3P_a121_pvtEcuStatCrcError "Electric power steering (primary): a121 pvt ecu stat crc error";
CM_ SG_ 914 EPAS3P_a122_olpActive "Electric power steering (primary): a122 olp active";
CM_ SG_ 914 EPAS3P_a123_combEcu2StatFail "Electric power steering (primary): a123 comb ecu2 stat fail";
CM_ SG_ 914 EPAS3P_a124_tempSensStuckInRange "Electric power steering (primary): a124 temp sens stuck in range";
CM_ SG_ 914 EPAS3P_a125_trqSensTrimOutRange "Electric power steering (primary): a125 trq sens trim out range";
CM_ SG_ 914 EPAS3P_a126_apsMia "Electric power steering (primary): a126 aps mia";
CM_ SG_ 914 EPAS3P_a127_apsCntError "Electric power steering (primary): a127 aps cnt error";
CM_ SG_ 914 EPAS3P_a128_apsCsError "Electric power steering (primary): a128 aps cs error";
CM_ SG_ 914 EPAS3P_a129_combEcu1StatFail "Electric power steering (primary): a129 comb ecu1 stat fail";
CM_ SG_ 914 EPAS3P_a130_sasOffsetNotCal "Electric power steering (primary): a130 sas offset not cal";
CM_ SG_ 914 EPAS3P_a131_phaseFeedbackError "Electric power steering (primary): a131 phase feedback error";
CM_ SG_ 914 EPAS3P_a132_motFeedFwdCounter25 "Electric power steering (primary): a132 mot feed fwd counter25";
CM_ SG_ 914 EPAS3P_a133_motFeedFwdCounter50 "Electric power steering (primary): a133 mot feed fwd counter50";
CM_ SG_ 914 EPAS3P_a134_motFeedFwdCounter85 "Electric power steering (primary): a134 mot feed fwd counter85";
CM_ SG_ 914 EPAS3P_a135_piCtrlCounter25 "Electric power steering (primary): a135 pi ctrl counter25";
CM_ SG_ 914 EPAS3P_a136_piCtrlCounter50 "Electric power steering (primary): a136 pi ctrl counter50";
CM_ SG_ 914 EPAS3P_a137_piCtrlCounter85 "Electric power steering (primary): a137 pi ctrl counter85";
CM_ SG_ 914 EPAS3P_a144_diSpdMia "Electric power steering (primary): a144 di spd mia";
CM_ SG_ 914 EPAS3P_a145_diSpdCntError "Electric power steering (primary): a145 di spd cnt error";
CM_ SG_ 914 EPAS3P_a146_diSpdCsError "Electric power steering (primary): a146 di spd cs error";
CM_ SG_ 914 EPAS3P_a147_backupVehSpeed "Electric power steering (primary): a147 backup veh speed";
CM_ SG_ 914 EPAS3P_a148_vMaxAssist "Electric power steering (primary): a148 v max assist";
CM_ SG_ 914 EPAS3P_a149_currentSensPathSwitc "Electric power steering (primary): a149 current sens path switch";
CM_ SG_ 914 EPAS3P_a150_currentSensOffsetDet "Electric power steering (primary): a150 current sens offset detect";
CM_ SG_ 914 EPAS3P_a151_dcsCboot "Electric power steering (primary): a151 dcs cboot";
CM_ SG_ 914 EPAS3P_a152_dcsDiagReg "Electric power steering (primary): a152 dcs diag reg";
CM_ SG_ 914 EPAS3P_a153_dcsInitOffset "Electric power steering (primary): a153 dcs init offset";
CM_ SG_ 914 EPAS3P_a154_assistTorqueDisabled "Electric power steering (primary): a154 assist torque disabled";
CM_ SG_ 914 EPAS3P_a155_backupEacActive "Electric power steering (primary): a155 backup eac active";
CM_ SG_ 914 EPAS3P_a156_angleSensorDivergenc "Electric power steering (primary): a156 angle sensor divergence";
CM_ SG_ 914 EPAS3P_a157_pmState2Mia "Electric power steering (primary): a157 pm state2 mia";
CM_ SG_ 914 EPAS3P_a158_pmState2CntError "Electric power steering (primary): a158 pm state2 cnt error";
CM_ SG_ 914 EPAS3P_a159_pmState2CsError "Electric power steering (primary): a159 pm state2 cs error";
CM_ SG_ 914 EPAS3P_a160_latentFaultTestResul "Electric power steering (primary): a160 latent fault test result";
CM_ SG_ 914 EPAS3P_a161_initTestPhaDisconnIn "Electric power steering (primary): a161 init test pha disconn info";
CM_ SG_ 914 EPAS3P_a162_initTestHSDFetInfo "Electric power steering (primary): a162 init test HSD fet info";
CM_ SG_ 914 EPAS3P_a163_initTestGateDrvrInfo "Electric power steering (primary): a163 init test gate drvr info";
CM_ SG_ 914 EPAS3P_a164_initTestDCSInfo "Electric power steering (primary): a164 init test DCS info";
CM_ SG_ 914 EPAS3P_a165_epbStatusMia "Electric power steering (primary): a165 epb status mia";
CM_ SG_ 914 EPAS3P_a166_epbStatusCntError "Electric power steering (primary): a166 epb status cnt error";
CM_ SG_ 914 EPAS3P_a167_epbStatusCsError "Electric power steering (primary): a167 epb status cs error";
CM_ SG_ 914 EPAS3P_a168_torsionBarTorqueQfDe "Electric power steering (primary): a168 torsion bar torque qf degraded";
CM_ SG_ 914 EPAS3P_a169_difMia "Electric power steering (primary): a169 dif mia";
CM_ SG_ 914 EPAS3P_a170_difCntError "Electric power steering (primary): a170 dif cnt error";
CM_ SG_ 914 EPAS3P_a171_difCsError "Electric power steering (primary): a171 dif cs error";
CM_ BO_ 977 "Electric power steering (primary) message: angle calibration; frame length from the layout, not yet observed on a vehicle bus";
CM_ SG_ 977 EPAS3P_appliedAngleOffset "This represents the angle delta between the absolute steering angle reference and what EPAS estimates to be straight ahead. The steering angle offset can change up to 5deg at the beginning of each drive cycle.";
CM_ SG_ 977 EPAS3P_calculatedAngleOffset "Reports the calculated steering angle offset learned between the Steering Column Control Module (SCCM) and the Electronic Power Assist Steering (EPAS) steering angle.";
CM_ SG_ 977 EPAS3P_resyncStatus "Electric power steering (primary): resync status";
CM_ SG_ 977 EPAS3P_pullDriftLongTermTrq "The learned, long term pull drift or road crown compensation torque that the rack is applying to the steering wheel.";
CM_ SG_ 977 EPAS3P_pullDriftCompTrq "The current pull drift or road crown compensation torque that the rack is applying to the steering wheel.";
CM_ SG_ 977 EPAS3P_learnedSCCMOffset "Electric power steering (primary): learned SCCM offset";
CM_ BO_ 817 "Electric power steering (primary) message: info; frame length from the layout, not yet observed on a vehicle bus";
CM_ SG_ 817 EPAS3P_infoIndex "Electric power steering (primary): info index";
CM_ SG_ 817 EPAS3P_infoBuildType "Electric power steering (primary): info build type";
CM_ SG_ 817 EPAS3P_infoComponentID "Electric power steering (primary): info component ID";
CM_ SG_ 817 EPAS3P_infoPcbaID "Electric power steering (primary): info pcba ID";
CM_ SG_ 817 EPAS3P_infoAssemblyID "Electric power steering (primary): info assembly ID";
CM_ SG_ 817 EPAS3P_infoUsageID "Electric power steering (primary): info usage ID";
CM_ SG_ 817 EPAS3P_infoApplicationCRC "Electric power steering (primary): info application CRC";
CM_ SG_ 817 EPAS3P_infoBootUdsProtoVersion "Electric power steering (primary): info boot uds proto version";
CM_ SG_ 817 EPAS3P_infoBootloaderCRC "Electric power steering (primary): info bootloader CRC";
CM_ SG_ 817 EPAS3P_infoSubcomponent2 "Electric power steering (primary): info subcomponent2";
CM_ BO_ 880 "Electric power steering (primary) message: sys status; frame length from the layout, not yet observed on a vehicle bus";
CM_ SG_ 880 EPAS3P_steeringRackForce "The real time, estimated force applied by the steering rack to the tie rods; raw 1023 = signal not available (SNA)";
CM_ SG_ 880 EPAS3P_steeringFault "Electric power steering (primary): steering fault";
CM_ SG_ 880 EPAS3P_steeringReduced "Electric power steering (primary): steering reduced";
CM_ SG_ 880 EPAS3P_internalSASQF "This signal identifies the validity of the EPAS3P_internalSAS signal.";
CM_ SG_ 880 EPAS3P_currentTuneMode "Electric power steering (primary): current tune mode";
CM_ SG_ 880 EPAS3P_torsionBarTorque "The measurement of the steering wheel torque input. If the value is positive the steering wheel torque is applied in the clockwise direction; raw 4095 = signal not available (SNA)";
CM_ SG_ 880 EPAS3P_eacErrorCode "Electric power steering (primary): eac error code; raw 15 = signal not available (SNA)";
CM_ SG_ 880 EPAS3P_internalSAS "The measurement of the steering wheel angle that is calculated by electronic power steering assist steering. Clockwise positive.";
CM_ SG_ 880 EPAS3P_handsOnLevel "Electric power steering (primary): hands on level";
CM_ SG_ 880 EPAS3P_sysStatusCounter "Electric power steering (primary): sys status counter";
CM_ SG_ 880 EPAS3P_driverlessState "Electric power steering (primary): driverless state";
CM_ SG_ 880 EPAS3P_eacStatus "Electric power steering (primary): eac status";
CM_ SG_ 880 EPAS3P_sysStatusChecksum "Electric power steering (primary): sys status checksum";
CM_ BO_ 909 "Electronic stability control message: party3; frame length from the layout, not yet observed on a vehicle bus";
CM_ SG_ 909 ESP_party3Crc "Electronic stability control: party3 crc";
CM_ SG_ 909 ESP_party3Counter "Electronic stability control: party3 counter";
CM_ SG_ 909 ESP_absActive "Electronic stability control: abs active";
CM_ SG_ 909 ESP_vehicleStandstill "Indicates that the vehicle is completely stationary.";
CM_ SG_ 909 ESP_vehicleStandstillQF "Qualifier of ESP_vehicleStandstill.";
CM_ SG_ 909 ESP_pEstMaximum "Maximum of estimated wheel braking pressure.";
CM_ SG_ 909 ESP_privateVehicleSpd "Vehicle speed as calculated by the ESP from the wheel speed sensors.";
CM_ SG_ 909 ESP_decoupledBrakePressOffsetCom "Master cylinder pressure sensor offset; raw 127 = signal not available (SNA)";
CM_ SG_ 909 ESP_privateVehicleSpdQF "ESP private vehicle speed qualifier";
CM_ SG_ 909 ESP_brakeMasterCylPress "Master cylinder pressure measured in the ESP; raw 1023 = signal not available (SNA)";
CM_ SG_ 909 ESP_brakeMasterCylPressQF "Reports the brake master cylinder pressure signal (ESP_brakeMasterCylPress) qualification status.";
CM_ BO_ 325 "Electronic stability control message: status; frame length from the layout, not yet observed on a vehicle bus";
CM_ SG_ 325 ESP_statusChecksum "Electronic stability control: status checksum";
CM_ SG_ 325 ESP_statusCounter "Electronic stability control: status counter";
CM_ SG_ 325 ESP_espModeActive "Electronic stability control: esp mode active";
CM_ SG_ 325 ESP_stabilityControlSts2 "Electronic stability control: stability control sts2";
CM_ SG_ 325 ESP_ebdFaultLamp "Electronic stability control: ebd fault lamp";
CM_ SG_ 325 ESP_absFaultLamp "ESP request to display ABS Fault Lamp.";
CM_ SG_ 325 ESP_espFaultLamp "ESP request to display ESP Fault lamp in instrument cluster.";
CM_ SG_ 325 ESP_hydraulicBoostEnabled "Electronic stability control: hydraulic boost enabled";
CM_ SG_ 325 ESP_espLampFlash "Electronic stability control: esp lamp flash";
CM_ SG_ 325 ESP_brakeLamp "Electronic stability control: brake lamp";
CM_ SG_ 325 ESP_absBrakeEvent2 "Indicates if ABS is active and on which axle.";
CM_ SG_ 325 ESP_longitudinalAccelQF "Longitudinal accel sensor quialifier from ESP";
CM_ SG_ 325 ESP_lateralAccelQF "Lateral accel sensor quialifier from ESP";
CM_ SG_ 325 ESP_yawRateQF "Electronic stability control: yaw rate QF";
CM_ SG_ 325 ESP_steeringAngleQF "Electronic stability control: steering angle QF";
CM_ SG_ 325 ESP_brakeDiscWipingActive "Indicates when brake disc wiping is active.";
CM_ SG_ 325 ESP_driverBrakeApply "Indicates when the driver applies the brake pedal; raw 3 = signal not available (SNA)";
CM_ SG_ 325 ESP_brakeApply "Electronic stability control: brake apply";
CM_ SG_ 325 ESP_aesPrimaryActuatorStatus "Electronic stability control: aes primary actuator status";
CM_ SG_ 325 ESP_cdpStatus "Indicates the state of the ESP to perform pressure builds through ESP for dynamic apply";
CM_ SG_ 325 ESP_ptcTargetState "Electronic stability control: ptc target state; raw 3 = signal not available (SNA)";
CM_ SG_ 325 ESP_btcTargetState "Electronic stability control: btc target state; raw 3 = signal not available (SNA)";
CM_ SG_ 325 ESP_decoupledBrakePressEst "Reports the master cylinder pressure estimated by the Electronic Stability Program (ESP) which includes four wheel ESP active pressure builds; raw 255 = signal not available (SNA)";
CM_ SG_ 325 ESP_ebrStandstillSkid "Electronic stability control: ebr standstill skid";
CM_ SG_ 325 ESP_ebrStatus "Electronic stability control: ebr status";
CM_ SG_ 325 ESP_brakeTorqueTarget "Electronic stability control: brake torque target";
CM_ BO_ 373 "Electronic stability control message: wheel speeds; frame length from the layout, not yet observed on a vehicle bus";
CM_ SG_ 373 ESP_wheelSpeedFrL "Electronic stability control: wheel speed fr l";
CM_ SG_ 373 ESP_wheelSpeedFrR "Electronic stability control: wheel speed fr r";
CM_ SG_ 373 ESP_wheelSpeedReL "Electronic stability control: wheel speed re l";
CM_ SG_ 373 ESP_wheelSpeedReR "Electronic stability control: wheel speed re r";
CM_ BO_ 925 "Electric brake booster message: status; frame length from the layout, not yet observed on a vehicle bus";
CM_ SG_ 925 IBST_statusChecksum "Electric brake booster: status checksum";
CM_ SG_ 925 IBST_statusCounter "Electric brake booster: status counter";
CM_ SG_ 925 IBST_iBoosterStatus "Indication of iBooster functional state";
CM_ SG_ 925 IBST_driverBrakeApply "Indicates when the driver applies the brake pedal.";
CM_ SG_ 925 IBST_internalState "Indication of iBooster internal state";
CM_ SG_ 925 IBST_sInputRodDriver "IBST estimated input rod stroke";
CM_ SG_ 925 IBST_LVPowerModeState "Electric brake booster: LV power mode state";
CM_ BO_ 1316 "PMF ECU message: mfg data; frame length from the layout, not yet observed on a vehicle bus";
CM_ SG_ 1316 PMF_processorDieIdLot "PMF ECU: processor die id lot";
CM_ SG_ 1316 PMF_processorDieIdWafer "PMF ECU: processor die id wafer";
CM_ SG_ 1316 PMF_processorDieIdX "PMF ECU: processor die id x";
CM_ SG_ 1316 PMF_processorDieIdY "PMF ECU: processor die id y";
CM_ BO_ 1364 "PMR ECU message: mfg data; frame length from the layout, not yet observed on a vehicle bus";
CM_ SG_ 1364 PMR_processorDieIdLot "PMR ECU: processor die id lot";
CM_ SG_ 1364 PMR_processorDieIdWafer "PMR ECU: processor die id wafer";
CM_ SG_ 1364 PMR_processorDieIdX "PMR ECU: processor die id x";
CM_ SG_ 1364 PMR_processorDieIdY "PMR ECU: processor die id y";
CM_ BO_ 1973 "PM ECU message: itpms display; frame length from the layout, not yet observed on a vehicle bus";
CM_ SG_ 1973 PM_itpmsDisplaySelector "PM ECU: itpms display selector";
CM_ SG_ 1973 PM_indirectTPMSTellTale "Indirect TPMS UI telltale status to indicate system availability";
CM_ SG_ 1973 PM_indirectTPMSDisplayState "Indirect TPMS UI calibration state";
CM_ SG_ 1973 PM_indirectTPMSDisplayProgress "PM ECU: indirect TPMS display progress";
CM_ SG_ 1973 PM_indirectTPMSDisplayWarningInd "Pressure loss warning indicator per wheel determined by indirect TPMS";
CM_ SG_ 1973 PM_indirectTPMSDisplayWarni_0001 "Pressure loss warning indicator per wheel determined by indirect TPMS";
CM_ SG_ 1973 PM_indirectTPMSDisplayWarni_0002 "Pressure loss warning indicator per wheel determined by indirect TPMS";
CM_ SG_ 1973 PM_indirectTPMSDisplayWarni_0003 "Pressure loss warning indicator per wheel determined by indirect TPMS";
CM_ SG_ 1973 PM_indirectTPMSRecommendedColdPr "Reports the recommended cold pressure for the front or rear tires as provided by the Indirect Tire Pressure Monitoring System (ITPMS); raw 255 = signal not available (SNA)";
CM_ SG_ 1973 PM_indirectTPMSRecommendedC_0001 "Reports the recommended cold pressure for the front or rear tires as provided by the Indirect Tire Pressure Monitoring System (ITPMS); raw 255 = signal not available (SNA)";
CM_ SG_ 1973 PM_fusedPressureEstimateFrL "Reports the estimated tire pressure at each wheel based on Indirect Tire Pressure Monitoring System (ITPMS) relative wheel speed and Global Navigation Satellite System (GNSS) absolute radius data.";
CM_ SG_ 1973 PM_fusedPressureEstimateFrR "Reports the estimated tire pressure at each wheel based on Indirect Tire Pressure Monitoring System (ITPMS) relative wheel speed and Global Navigation Satellite System (GNSS) absolute radius data.";
CM_ SG_ 1973 PM_fusedPressureEstimateReL "Reports the estimated tire pressure at each wheel based on Indirect Tire Pressure Monitoring System (ITPMS) relative wheel speed and Global Navigation Satellite System (GNSS) absolute radius data.";
CM_ SG_ 1973 PM_fusedPressureEstimateReR "Reports the estimated tire pressure at each wheel based on Indirect Tire Pressure Monitoring System (ITPMS) relative wheel speed and Global Navigation Satellite System (GNSS) absolute radius data.";
CM_ BO_ 2038 "PM ECU message: vdc debug; frame length from the layout, not yet observed on a vehicle bus";
CM_ SG_ 2038 PM_vdcDebugSelector "PM ECU: vdc debug selector";
CM_ SG_ 2038 PM_VDCA_TCSlipTargetMod_RA_Fwd "PM ECU: VDCA TC slip target mod RA fwd";
CM_ SG_ 2038 PM_VDCA_TCSlipTargetMod_RA_Rwd "PM ECU: VDCA TC slip target mod RA rwd";
CM_ SG_ 2038 PM_VSE_forceY_RA "PM ECU: VSE force y RA";
CM_ SG_ 2038 PM_VDCT_observerSlipAngle_RA "PM ECU: VDCT observer slip angle RA";
CM_ SG_ 2038 PM_VSE_muVehicleFxLow "PM ECU: VSE mu vehicle fx low";
CM_ SG_ 2038 PM_VE_fxmFres "PM ECU: VE fxm fres";
CM_ SG_ 2038 PM_VE_fxAccelMass "PM ECU: VE fx accel mass";
CM_ SG_ 2038 PM_VE_vxDotGrade "PM ECU: VE vx dot grade";
CM_ SG_ 2038 PM_VE_betaEst "PM ECU: VE beta est";
CM_ SG_ 2038 PM_VSE_muVehicleFxHigh "PM ECU: VSE mu vehicle fx high";
CM_ SG_ 2038 PM_VSE_muVehicleDecLeakRate "PM ECU: VSE mu vehicle dec leak rate";
CM_ SG_ 2038 PM_VSE_muVehicleLearnDown "PM ECU: VSE mu vehicle learn down";
CM_ SG_ 2038 PM_VSE_muVehicleDecFilter "PM ECU: VSE mu vehicle dec filter";
CM_ SG_ 2038 PM_VSE_muVehicleLatDecLeakRate "PM ECU: VSE mu vehicle lat dec leak rate";
CM_ SG_ 2038 PM_VSE_splitMuProbability "PM ECU: VSE split mu probability";
CM_ SG_ 2038 PM_VSE_splitMuTotalMz "PM ECU: VSE split mu total mz";
CM_ SG_ 2038 PM_VSE_attitudeBankAngle "PM ECU: VSE attitude bank angle";
CM_ SG_ 2038 PM_VSE_attitudeDBetaInControl "PM ECU: VSE attitude d beta in control";
CM_ SG_ 2038 PM_VSE_roadWheelAngleAverage "PM ECU: VSE road wheel angle average";
CM_ BO_ 17 "Restraint control module message: collision; frame length from the layout, not yet observed on a vehicle bus";
CM_ SG_ 17 RCM_collisionChecksum "Restraint control module: collision checksum";
CM_ SG_ 17 RCM_collisionCounter "Restraint control module: collision counter";
CM_ SG_ 17 RCM_collisionRear "Indicates that a rear collision occurred; raw 3 = signal not available (SNA)";
CM_ SG_ 17 RCM_collisionRight "Indicates that a right side collision occurred; raw 3 = signal not available (SNA)";
CM_ SG_ 17 RCM_collisionLeft "Indicates that a left side collision occurred; raw 3 = signal not available (SNA)";
CM_ SG_ 17 RCM_collisionFront "Indicates that a frontal collision occurred; raw 3 = signal not available (SNA)";
CM_ SG_ 17 RCM_collisionRollover "Indicates that a rollover has occurred; raw 3 = signal not available (SNA)";
CM_ SG_ 17 RCM_collisionPedPro "Indicates that a pedestrian impact has occurred; raw 3 = signal not available (SNA)";
CM_ SG_ 17 RCM_collisionSeverity "Collision severity";
CM_ BO_ 289 "Restraint control module message: near deploy; frame length from the layout, not yet observed on a vehicle bus";
CM_ SG_ 289 RCM_nearDeployChecksum "Restraint control module: near deploy checksum";
CM_ SG_ 289 RCM_nearDeployCounter "Restraint control module: near deploy counter";
CM_ SG_ 289 RCM_nearDeployRear "Indicates that a rear near deploy event has occurred. No airbags have been deployed; raw 3 = signal not available (SNA)";
CM_ SG_ 289 RCM_nearDeployRight "Indicates that a right side near deploy event has occurred. No airbags have been deployed; raw 3 = signal not available (SNA)";
CM_ SG_ 289 RCM_nearDeployLeft "Indicates that a left side near deploy event has occurred. No airbags have been deployed; raw 3 = signal not available (SNA)";
CM_ SG_ 289 RCM_nearDeployFront "Indicates that a frontal near deploy event has occurred. No airbags have been deployed; raw 3 = signal not available (SNA)";
CM_ SG_ 289 RCM_nearDeployRollover "Indicates that a roll over near deploy event has occurred. No airbags have been deployed; raw 3 = signal not available (SNA)";
CM_ SG_ 289 RCM_crashAlgoWakeup "Crash Algorithm Wakeup status; raw 3 = signal not available (SNA)";
CM_ BO_ 1618 "VCBATT0 ECU message: info; frame length from the layout, not yet observed on a vehicle bus";
CM_ SG_ 1618 VCBATT0_infoIndex "VCBATT0 ECU: info index";
CM_ SG_ 1618 VCBATT0_infoBuildType "VCBATT0 ECU: info build type";
CM_ SG_ 1618 VCBATT0_infoBuildConfigId "VCBATT0 ECU: info build config id";
CM_ SG_ 1618 VCBATT0_infoHardwareId "VCBATT0 ECU: info hardware id";
CM_ SG_ 1618 VCBATT0_infoComponentId "VCBATT0 ECU: info component id";
CM_ SG_ 1618 VCBATT0_infoPcbaId "VCBATT0 ECU: info pcba id";
CM_ SG_ 1618 VCBATT0_infoAssemblyId "VCBATT0 ECU: info assembly id; raw 255 = signal not available (SNA)";
CM_ SG_ 1618 VCBATT0_infoUsageId "VCBATT0 ECU: info usage id";
CM_ SG_ 1618 VCBATT0_infoSubUsageId "VCBATT0 ECU: info sub usage id";
CM_ SG_ 1618 VCBATT0_infoAppCrc "VCBATT0 ECU: info app crc";
CM_ SG_ 1618 VCBATT0_infoAppGitHash "VCBATT0 ECU: info app git hash";
CM_ SG_ 1618 VCBATT0_infoBootGitHash "VCBATT0 ECU: info boot git hash";
CM_ SG_ 1618 VCBATT0_infoBootUdsProtoVersion "VCBATT0 ECU: info boot uds proto version";
CM_ SG_ 1618 VCBATT0_infoBootCrc "VCBATT0 ECU: info boot crc";
CM_ BO_ 1994 "VCCC ECU message: info; frame length from the layout, not yet observed on a vehicle bus";
CM_ SG_ 1994 VCCC_infoIndex "VCCC ECU: info index";
CM_ SG_ 1994 VCCC_infoBuildType "VCCC ECU: info build type";
CM_ SG_ 1994 VCCC_infoBuildConfigId "VCCC ECU: info build config id";
CM_ SG_ 1994 VCCC_infoHardwareId "VCCC ECU: info hardware id";
CM_ SG_ 1994 VCCC_infoComponentId "VCCC ECU: info component id";
CM_ SG_ 1994 VCCC_infoPcbaId "VCCC ECU: info pcba id";
CM_ SG_ 1994 VCCC_infoAssemblyId "VCCC ECU: info assembly id; raw 255 = signal not available (SNA)";
CM_ SG_ 1994 VCCC_infoUsageId "VCCC ECU: info usage id";
CM_ SG_ 1994 VCCC_infoSubUsageId "VCCC ECU: info sub usage id";
CM_ SG_ 1994 VCCC_infoAppCrc "VCCC ECU: info app crc";
CM_ SG_ 1994 VCCC_infoAppGitHash "VCCC ECU: info app git hash";
CM_ SG_ 1994 VCCC_infoBootGitHash "VCCC ECU: info boot git hash";
CM_ SG_ 1994 VCCC_infoBootUdsProtoVersion "VCCC ECU: info boot uds proto version";
CM_ SG_ 1994 VCCC_infoBootCrc "VCCC ECU: info boot crc";
CM_ BO_ 260 "Front body controller message: party debug; frame length from the layout, not yet observed on a vehicle bus";
CM_ SG_ 260 VCFRONT_vcleftHighPower "Front body controller: vcleft high power";
CM_ SG_ 260 VCFRONT_vcrightHighPower "Front body controller: vcright high power";
CM_ SG_ 260 VCFRONT_uiHighPower "Front body controller: ui high power";
CM_ SG_ 260 VCFRONT_5VAStable "Front body controller: 5 VA stable";
CM_ SG_ 260 VCFRONT_5VBStable "Front body controller: 5 VB stable";
CM_ SG_ 260 VCFRONT_12VAStable "Front body controller: 12 VA stable";
CM_ SG_ 260 VCFRONT_12VBStable "Front body controller: 12 VB stable";
CM_ SG_ 260 VCFRONT_railA "Front body controller: rail a";
CM_ SG_ 260 VCFRONT_railB "Front body controller: rail b";
CM_ SG_ 260 VCFRONT_chargePumpStable "Front body controller: charge pump stable";
CM_ SG_ 260 VCFRONT_vehicleSM "Vehicle state machine state; raw 18 = signal not available (SNA)";
CM_ SG_ 260 VCFRONT_revBattFault "Front body controller: rev batt fault";
CM_ SG_ 260 VCFRONT_battSM "Front body controller: batt SM";
CM_ SG_ 260 VCFRONT_U13Init "Front body controller: U13 init";
CM_ SG_ 260 VCFRONT_U16Init "Front body controller: U16 init";
CM_ SG_ 260 VCFRONT_anyVehLoadShedActiveDBG "Front body controller: any veh load shed active DBG";
CM_ SG_ 260 VCFRONT_battVoltage "Front body controller: batt voltage";
CM_ SG_ 260 VCFRONT_battCurrent "Front body controller: batt current";
CM_ BO_ 258 "Left body controller message: door status; frame length from the layout, not yet observed on a vehicle bus";
CM_ SG_ 258 VCLEFT_doorClosureStatusFront "Status of the door from a closures perspective; raw 0 = signal not available (SNA)";
CM_ SG_ 258 VCLEFT_doorClosureStatusRear "Status of the door from a closures perspective; raw 0 = signal not available (SNA)";
CM_ SG_ 258 VCLEFT_frontLatchSwitch "State of front left door latch switch representing door open/closed. 0 is open and 1 is closed";
CM_ SG_ 258 VCLEFT_rearLatchSwitch "State of rear left door latch switch representing door open/closed. 0 is open and 1 is closed";
CM_ SG_ 258 VCLEFT_frontHandlePulled "Left body controller: front handle pulled";
CM_ SG_ 258 VCLEFT_rearHandlePulled "Left body controller: rear handle pulled";
CM_ SG_ 258 VCLEFT_frontRelActuatorSwitch "State of front left door latch switch representing latch arm/unarmed. Disarms while door handle is pulled.";
CM_ SG_ 258 VCLEFT_rearRelActuatorSwitch "State of rear left door latch switch representing latch arm/unarmed. Disarms while door handle is pulled";
CM_ SG_ 258 VCLEFT_frontLatchStatus "Status of left front door latch; raw 0 = signal not available (SNA)";
CM_ SG_ 258 VCLEFT_rearLatchStatus "Status of rear left door latch; raw 0 = signal not available (SNA)";
CM_ SG_ 258 VCLEFT_lastDoorReqSourceFront "last source of front door open request";
CM_ SG_ 258 VCLEFT_lastDoorReqSourceRear "last source of rear door open request";
CM_ SG_ 258 VCLEFT_frontIntSwitchFaulted "Indicates if the front door interior button is faulted";
CM_ SG_ 258 VCLEFT_rearIntSwitchFaulted "Indicates if the rear door interior button is faulted";
CM_ SG_ 258 VCLEFT_frontIntSwitchPressed "Left body controller: front int switch pressed";
CM_ SG_ 258 VCLEFT_rearIntSwitchPressed "Left body controller: rear int switch pressed";
CM_ SG_ 258 VCLEFT_mirrorTiltXPosition "Value representing left side view mirror tilt horizontal position";
CM_ SG_ 258 VCLEFT_mirrorTiltYPosition "Value representing left side view mirror tilt vertical position";
CM_ SG_ 258 VCLEFT_mirrorState "State of the left side view mirror.";
CM_ SG_ 258 VCLEFT_mirrorFoldState "Fold state for the left side view mirror";
CM_ SG_ 258 VCLEFT_mirrorRecallState "State of Mirror Recall.";
CM_ SG_ 258 VCLEFT_mirrorHeatState "Left body controller: mirror heat state; raw 0 = signal not available (SNA)";
CM_ SG_ 258 VCLEFT_rearHandlePulledPersist "Left body controller: rear handle pulled persist";
CM_ SG_ 258 VCLEFT_frontHandlePulledPersist "Left body controller: front handle pulled persist";
CM_ SG_ 258 VCLEFT_mirrorDipped "Reports if the side view mirrors in are in the dipped position.";
CM_ BO_ 546 "Left body controller message: epbm status; frame length from the layout, not yet observed on a vehicle bus";
CM_ SG_ 546 VCLEFT_cdpRequestState "If the Electronic Parking Brake makes a Controlled Deceleration for Parking Brake request, when cdpOkayToRequest is EPB_CDP_REQUEST_INVALID, cdpRequestState shall transition to EPB_CDP_REQUEST_INVALID, untill the Electronic Parking Brake Monitor enters unitStatus PARKED. Stability Control listens to this signal to qualify Controlled Deceleration for Parking Brake requests from the Electronic Parking Brake.";
CM_ SG_ 546 VCLEFT_epbmSystemStatusQF "Left body controller: epbm system status QF";
CM_ SG_ 546 VCLEFT_epbmUnitStatus "Electronic Parking Brake Monitors state.";
CM_ SG_ 546 VCLEFT_epbmCdpState "Left body controller: epbm cdp state";
CM_ SG_ 546 VCLEFT_epbmRedundantBrakingEnabl "Left body controller: epbm redundant braking enabled";
CM_ SG_ 546 VCLEFT_epbmStatusCounter "Left body controller: epbm status counter";
CM_ SG_ 546 VCLEFT_epbmStatusChecksum "Left body controller: epbm status checksum";
CM_ BO_ 778 "Left body controller message: restraint status; frame length from the layout, not yet observed on a vehicle bus";
CM_ SG_ 778 VCLEFT_frontOccupancyStatus "Left body controller: front occupancy status; raw 7 = signal not available (SNA)";
CM_ SG_ 778 VCLEFT_frontBuckleStatus "Status of front left seatbelt buckle";
CM_ SG_ 778 VCLEFT_rearLeftOccupancyStatus "Status of rear left seat occupancy sensor";
CM_ SG_ 778 VCLEFT_rearCenterOccupancyStatus "Status of rear center seat occupancy sensor";
CM_ SG_ 778 VCLEFT_rearRightOccupancyStatus "Status of rear right seat occupancy sensor";
CM_ SG_ 778 VCLEFT_rearLeftBuckleStatus "Status of rear left seatbelt buckle";
CM_ SG_ 778 VCLEFT_rearCenterBuckleStatus "Status of rear center seatbelt buckle";
CM_ SG_ 778 VCLEFT_seatTrackPosition "Status of seat track position sensor; raw 7 = signal not available (SNA)";
CM_ SG_ 778 VCLEFT_3RowLeftABStatus "Reports status of third row left airbag suppression; raw 2 = signal not available (SNA)";
CM_ SG_ 778 VCLEFT_3RowLeftBuckleStatus "Reports status of third row left seatbelt buckle";
CM_ SG_ 778 VCLEFT_restraintStatusCounter "Left body controller: restraint status counter";
CM_ SG_ 778 VCLEFT_restraintStatusChecksum "Left body controller: restraint status checksum";
CM_ BO_ 1124 "Right body controller message: AP hvac state1 hz; frame length from the layout, not yet observed on a vehicle bus";
CM_ SG_ 1124 VCRIGHT_AP_hvacState1HzIndex "Right body controller: AP hvac state1 hz index";
CM_ SG_ 1124 VCRIGHT_AP_tempCameraModele_0001 "Right body controller: AP temp camera modeled windshield out; raw 255 = signal not available (SNA)";
CM_ SG_ 1124 VCRIGHT_AP_tempCameraModeledWind "Right body controller: AP temp camera modeled windshield in; raw 255 = signal not available (SNA)";
CM_ SG_ 1124 VCRIGHT_AP_cameraModeledWin_0001 "Right body controller: AP camera modeled windshield out rh; raw 127 = signal not available (SNA)";
CM_ SG_ 1124 VCRIGHT_AP_cameraModeledWindshie "Right body controller: AP camera modeled windshield in rh; raw 127 = signal not available (SNA)";
CM_ SG_ 1124 VCRIGHT_AP_maxAchievableASideTem "Right body controller: AP max achievable a side temp camera pocket";
CM_ SG_ 1124 VCRIGHT_AP_cameraModeledPocketWa "Right body controller: AP camera modeled pocket water mass; raw 1023 = signal not available (SNA)";
CM_ SG_ 1124 VCRIGHT_AP_humidityModelInitStat "Right body controller: AP humidity model init status";
CM_ SG_ 1124 VCRIGHT_AP_humidityModelStatus "Right body controller: AP humidity model status";
CM_ BO_ 259 "Right body controller message: door status; frame length from the layout, not yet observed on a vehicle bus";
CM_ SG_ 259 VCRIGHT_doorClosureStatusFront "Status of the door from a closures perspective; raw 0 = signal not available (SNA)";
CM_ SG_ 259 VCRIGHT_doorClosureStatusRear "Status of the door from a closures perspective; raw 0 = signal not available (SNA)";
CM_ SG_ 259 VCRIGHT_frontLatchSwitch "State of front left door latch switch representing door open/closed. 0 is open and 1 is closed";
CM_ SG_ 259 VCRIGHT_rearLatchSwitch "State of rear right door latch switch representing door open/closed. 0 is open and 1 is closed";
CM_ SG_ 259 VCRIGHT_frontHandlePulled "Right body controller: front handle pulled";
CM_ SG_ 259 VCRIGHT_rearHandlePulled "Right body controller: rear handle pulled";
CM_ SG_ 259 VCRIGHT_frontRelActuatorSwitch "State of front left door latch switch representing latch arm/unarmed. Disarms while door handle is pulled.";
CM_ SG_ 259 VCRIGHT_rearRelActuatorSwitch "State of rear right door latch switch representing latch arm/unarmed. Disarms while door handle is pulled";
CM_ SG_ 259 VCRIGHT_frontLatchStatus "Status of right front door latch; raw 0 = signal not available (SNA)";
CM_ SG_ 259 VCRIGHT_rearLatchStatus "Status of rear right door latch; raw 0 = signal not available (SNA)";
CM_ SG_ 259 VCRIGHT_lastDoorReqSourceFront "last source of front door open request";
CM_ SG_ 259 VCRIGHT_lastDoorReqSourceRear "last source of rear door open request";
CM_ SG_ 259 VCRIGHT_frontIntSwitchFaulted "Indicates if the front door interior button is faulted";
CM_ SG_ 259 VCRIGHT_rearIntSwitchFaulted "Indicates if the rear door interior button is faulted";
CM_ SG_ 259 VCRIGHT_frontHandlePulledPersist "Right body controller: front handle pulled persist";
CM_ SG_ 259 VCRIGHT_frontIntSwitchPressed "Right body controller: front int switch pressed";
CM_ SG_ 259 VCRIGHT_rearIntSwitchPressed "Right body controller: rear int switch pressed";
CM_ SG_ 259 VCRIGHT_mirrorTiltXPosition "Value representing right side view mirror tilt horizontal position";
CM_ SG_ 259 VCRIGHT_mirrorTiltYPosition "Value representing right side view mirror tilt vertical position";
CM_ SG_ 259 VCRIGHT_mirrorState "State of the right side view mirror.";
CM_ SG_ 259 VCRIGHT_mirrorFoldState "Fold state for the right side view mirror";
CM_ SG_ 259 VCRIGHT_mirrorDipped "Reports if the side view mirrors in are in the dipped position.";
CM_ SG_ 259 VCRIGHT_trunkLatchStatus "State of the trunk latch; raw 0 = signal not available (SNA)";
CM_ SG_ 259 VCRIGHT_mirrorRecallState "State of Mirror Recall.";
CM_ SG_ 259 VCRIGHT_rearHandlePulledPersist "Right body controller: rear handle pulled persist";
CM_ BO_ 611 "Right body controller message: epbm status; frame length from the layout, not yet observed on a vehicle bus";
CM_ SG_ 611 VCRIGHT_cdpRequestState "If the Electronic Parking Brake makes a Controlled Deceleration for Parking Brake request, when cdpOkayToRequest is EPB_CDP_REQUEST_INVALID, cdpRequestState shall transition to EPB_CDP_REQUEST_INVALID, untill the Electronic Parking Brake Monitor enters unitStatus PARKED. Stability Control listens to this signal to qualify Controlled Deceleration for Parking Brake requests from the Electronic Parking Brake.";
CM_ SG_ 611 VCRIGHT_epbmSystemStatusQF "Right body controller: epbm system status QF";
CM_ SG_ 611 VCRIGHT_epbmUnitStatus "Electronic Parking Brake Monitors state.";
CM_ SG_ 611 VCRIGHT_epbmCdpState "Right body controller: epbm cdp state";
CM_ SG_ 611 VCRIGHT_epbmRedundantBrakingEnab "Right body controller: epbm redundant braking enabled";
CM_ SG_ 611 VCRIGHT_epbmStatusCounter "Right body controller: epbm status counter";
CM_ SG_ 611 VCRIGHT_epbmStatusChecksum "Right body controller: epbm status checksum";
CM_ BO_ 794 "Right body controller message: restraint status; frame length from the layout, not yet observed on a vehicle bus";
CM_ SG_ 794 VCRIGHT_frontOccupancyStatus "Right body controller: front occupancy status; raw 7 = signal not available (SNA)";
CM_ SG_ 794 VCRIGHT_frontBuckleStatus "Status of front right seatbelt buckle";
CM_ SG_ 794 VCRIGHT_rearCenterBuckleStatus "Right body controller: rear center buckle status";
CM_ SG_ 794 VCRIGHT_rearRightBuckleStatus "Right body controller: rear right buckle status";
CM_ SG_ 794 VCRIGHT_rearRightOccupancyStatus "Right body controller: rear right occupancy status";
CM_ SG_ 794 VCRIGHT_3RowLeftBuckleStatus "Status of third row left seatbelt buckle";
CM_ SG_ 794 VCRIGHT_3RowRightBuckleStatus "Right body controller: 3 row right buckle status";
CM_ SG_ 794 VCRIGHT_3RowLeftOccupancyStatus "Right body controller: 3 row left occupancy status";
CM_ SG_ 794 VCRIGHT_3RowRightOccupancyStatus "Right body controller: 3 row right occupancy status";
CM_ SG_ 794 VCRIGHT_seatTrackPosition "Right body controller: seat track position; raw 7 = signal not available (SNA)";
CM_ SG_ 794 VCRIGHT_occupantClassification "Right body controller: occupant classification; raw 7 = signal not available (SNA)";
CM_ SG_ 794 VCRIGHT_occupantClassificationQF "Right body controller: occupant classification QF";
CM_ SG_ 794 VCRIGHT_classificationEnabled "Indicates whether the RCM should consume VCRIGHT occupant classification rather than another source such as OCS1P";
CM_ SG_ 794 VCRIGHT_classificationEnabledQF "Indicates whether the VCRIGHT_classificationEnabled signal is valid";
CM_ SG_ 794 VCRIGHT_3RowRightABStatus "Reports status of third row right airbag suppression; raw 2 = signal not available (SNA)";
CM_ SG_ 794 VCRIGHT_restraintStatusCounter "Right body controller: restraint status counter";
CM_ SG_ 794 VCRIGHT_restraintStatusChecksum "Right body controller: restraint status checksum";
BA_DEF_ BO_ "GenMsgCycleTime" INT 0 3600000;
BA_DEF_ BO_ "GenMsgSendType" ENUM "Cyclic","NotUsed","NotUsed","NotUsed","NotUsed","NotUsed","NotUsed","IfActive","NoMsgSendType","NotUsed";
BA_DEF_ BO_ "VFrameFormat" ENUM "StandardCAN","ExtendedCAN","reserved","J1939PG","reserved","reserved","reserved","reserved","reserved","reserved","reserved","reserved","reserved","reserved","StandardCAN_FD","ExtendedCAN_FD";
BA_DEF_ BO_ "CANFD_BRS" ENUM "0","1";
BA_DEF_ SG_ "GenSigSNA" STRING;
BA_DEF_ SG_ "SystemSignalLongSymbol" STRING;
BA_DEF_ SG_ "Confidence" ENUM "validated","plausible","layout-only","contradicted";
BA_DEF_DEF_ "GenMsgCycleTime" 0;
BA_DEF_DEF_ "GenMsgSendType" "NoMsgSendType";
BA_DEF_DEF_ "VFrameFormat" "StandardCAN";
BA_DEF_DEF_ "CANFD_BRS" "1";
BA_DEF_DEF_ "GenSigSNA" "";
BA_DEF_DEF_ "SystemSignalLongSymbol" "";
BA_DEF_DEF_ "Confidence" "layout-only";
BA_ "GenMsgCycleTime" BO_ 914 1000;
BA_ "GenMsgSendType" BO_ 914 0;
BA_ "GenMsgCycleTime" BO_ 977 1000;
BA_ "GenMsgSendType" BO_ 977 0;
BA_ "GenMsgCycleTime" BO_ 817 1000;
BA_ "GenMsgSendType" BO_ 817 0;
BA_ "GenMsgCycleTime" BO_ 880 10;
BA_ "GenMsgSendType" BO_ 880 0;
BA_ "GenMsgCycleTime" BO_ 909 10;
BA_ "GenMsgSendType" BO_ 909 0;
BA_ "GenMsgCycleTime" BO_ 325 20;
BA_ "GenMsgSendType" BO_ 325 0;
BA_ "GenMsgCycleTime" BO_ 373 20;
BA_ "GenMsgSendType" BO_ 373 0;
BA_ "GenMsgCycleTime" BO_ 925 40;
BA_ "GenMsgSendType" BO_ 925 0;
BA_ "GenMsgCycleTime" BO_ 1316 1000;
BA_ "GenMsgSendType" BO_ 1316 0;
BA_ "GenMsgCycleTime" BO_ 1364 1000;
BA_ "GenMsgSendType" BO_ 1364 0;
BA_ "GenMsgCycleTime" BO_ 1973 1000;
BA_ "GenMsgSendType" BO_ 1973 0;
BA_ "GenMsgCycleTime" BO_ 2038 20;
BA_ "GenMsgSendType" BO_ 2038 0;
BA_ "GenMsgCycleTime" BO_ 17 10;
BA_ "GenMsgSendType" BO_ 17 0;
BA_ "GenMsgCycleTime" BO_ 289 10;
BA_ "GenMsgSendType" BO_ 289 0;
BA_ "GenMsgCycleTime" BO_ 1618 1000;
BA_ "GenMsgSendType" BO_ 1618 0;
BA_ "GenMsgCycleTime" BO_ 1994 1000;
BA_ "GenMsgSendType" BO_ 1994 0;
BA_ "GenMsgCycleTime" BO_ 260 100;
BA_ "GenMsgSendType" BO_ 260 0;
BA_ "GenMsgCycleTime" BO_ 258 100;
BA_ "GenMsgSendType" BO_ 258 0;
BA_ "GenMsgCycleTime" BO_ 546 100;
BA_ "GenMsgSendType" BO_ 546 0;
BA_ "GenMsgCycleTime" BO_ 778 50;
BA_ "GenMsgSendType" BO_ 778 0;
BA_ "GenMsgCycleTime" BO_ 1124 1000;
BA_ "GenMsgSendType" BO_ 1124 0;
BA_ "GenMsgCycleTime" BO_ 259 100;
BA_ "GenMsgSendType" BO_ 259 0;
BA_ "GenMsgCycleTime" BO_ 611 100;
BA_ "GenMsgSendType" BO_ 611 0;
BA_ "GenMsgCycleTime" BO_ 794 50;
BA_ "GenMsgSendType" BO_ 794 0;
BA_ "Confidence" SG_ 914 EPAS3P_matrixIndex 1;
BA_ "SystemSignalLongSymbol" SG_ 914 EPAS3P_a149_currentSensPathSwitc "EPAS3P_a149_currentSensPathSwitch";
BA_ "SystemSignalLongSymbol" SG_ 914 EPAS3P_a150_currentSensOffsetDet "EPAS3P_a150_currentSensOffsetDetect";
BA_ "SystemSignalLongSymbol" SG_ 914 EPAS3P_a156_angleSensorDivergenc "EPAS3P_a156_angleSensorDivergence";
BA_ "SystemSignalLongSymbol" SG_ 914 EPAS3P_a160_latentFaultTestResul "EPAS3P_a160_latentFaultTestResult";
BA_ "SystemSignalLongSymbol" SG_ 914 EPAS3P_a161_initTestPhaDisconnIn "EPAS3P_a161_initTestPhaDisconnInfo";
BA_ "SystemSignalLongSymbol" SG_ 914 EPAS3P_a168_torsionBarTorqueQfDe "EPAS3P_a168_torsionBarTorqueQfDegraded";
BA_ "Confidence" SG_ 977 EPAS3P_appliedAngleOffset 0;
BA_ "Confidence" SG_ 977 EPAS3P_calculatedAngleOffset 0;
BA_ "Confidence" SG_ 977 EPAS3P_resyncStatus 0;
BA_ "Confidence" SG_ 977 EPAS3P_pullDriftLongTermTrq 0;
BA_ "Confidence" SG_ 977 EPAS3P_pullDriftCompTrq 0;
BA_ "Confidence" SG_ 977 EPAS3P_learnedSCCMOffset 0;
BA_ "Confidence" SG_ 817 EPAS3P_infoIndex 1;
BA_ "Confidence" SG_ 817 EPAS3P_infoBuildType 0;
BA_ "Confidence" SG_ 817 EPAS3P_infoComponentID 0;
BA_ "Confidence" SG_ 817 EPAS3P_infoPcbaID 0;
BA_ "Confidence" SG_ 817 EPAS3P_infoAssemblyID 0;
BA_ "Confidence" SG_ 817 EPAS3P_infoUsageID 0;
BA_ "Confidence" SG_ 817 EPAS3P_infoApplicationCRC 0;
BA_ "Confidence" SG_ 817 EPAS3P_infoBootUdsProtoVersion 0;
BA_ "Confidence" SG_ 817 EPAS3P_infoBootloaderCRC 0;
BA_ "Confidence" SG_ 817 EPAS3P_infoSubcomponent2 0;
BA_ "Confidence" SG_ 880 EPAS3P_steeringRackForce 1;
BA_ "GenSigSNA" SG_ 880 EPAS3P_steeringRackForce "1023";
BA_ "Confidence" SG_ 880 EPAS3P_steeringFault 1;
BA_ "Confidence" SG_ 880 EPAS3P_steeringReduced 1;
BA_ "Confidence" SG_ 880 EPAS3P_internalSASQF 1;
BA_ "Confidence" SG_ 880 EPAS3P_currentTuneMode 1;
BA_ "Confidence" SG_ 880 EPAS3P_torsionBarTorque 1;
BA_ "GenSigSNA" SG_ 880 EPAS3P_torsionBarTorque "4095";
BA_ "Confidence" SG_ 880 EPAS3P_eacErrorCode 1;
BA_ "GenSigSNA" SG_ 880 EPAS3P_eacErrorCode "15";
BA_ "Confidence" SG_ 880 EPAS3P_internalSAS 1;
BA_ "Confidence" SG_ 880 EPAS3P_handsOnLevel 1;
BA_ "Confidence" SG_ 880 EPAS3P_driverlessState 1;
BA_ "Confidence" SG_ 880 EPAS3P_eacStatus 1;
BA_ "Confidence" SG_ 909 ESP_party3Crc 0;
BA_ "Confidence" SG_ 909 ESP_party3Counter 0;
BA_ "Confidence" SG_ 909 ESP_absActive 0;
BA_ "Confidence" SG_ 909 ESP_vehicleStandstill 0;
BA_ "Confidence" SG_ 909 ESP_vehicleStandstillQF 0;
BA_ "Confidence" SG_ 909 ESP_pEstMaximum 0;
BA_ "Confidence" SG_ 909 ESP_privateVehicleSpd 0;
BA_ "Confidence" SG_ 909 ESP_decoupledBrakePressOffsetCom 0;
BA_ "GenSigSNA" SG_ 909 ESP_decoupledBrakePressOffsetCom "127";
BA_ "SystemSignalLongSymbol" SG_ 909 ESP_decoupledBrakePressOffsetCom "ESP_decoupledBrakePressOffsetComp";
BA_ "Confidence" SG_ 909 ESP_privateVehicleSpdQF 0;
BA_ "Confidence" SG_ 909 ESP_brakeMasterCylPress 0;
BA_ "GenSigSNA" SG_ 909 ESP_brakeMasterCylPress "1023";
BA_ "Confidence" SG_ 909 ESP_brakeMasterCylPressQF 0;
BA_ "Confidence" SG_ 325 ESP_statusChecksum 0;
BA_ "Confidence" SG_ 325 ESP_statusCounter 0;
BA_ "Confidence" SG_ 325 ESP_espModeActive 0;
BA_ "Confidence" SG_ 325 ESP_stabilityControlSts2 0;
BA_ "Confidence" SG_ 325 ESP_ebdFaultLamp 0;
BA_ "Confidence" SG_ 325 ESP_absFaultLamp 0;
BA_ "Confidence" SG_ 325 ESP_espFaultLamp 0;
BA_ "Confidence" SG_ 325 ESP_hydraulicBoostEnabled 0;
BA_ "Confidence" SG_ 325 ESP_espLampFlash 0;
BA_ "Confidence" SG_ 325 ESP_brakeLamp 0;
BA_ "Confidence" SG_ 325 ESP_absBrakeEvent2 0;
BA_ "Confidence" SG_ 325 ESP_longitudinalAccelQF 0;
BA_ "Confidence" SG_ 325 ESP_lateralAccelQF 0;
BA_ "Confidence" SG_ 325 ESP_yawRateQF 0;
BA_ "Confidence" SG_ 325 ESP_steeringAngleQF 0;
BA_ "Confidence" SG_ 325 ESP_brakeDiscWipingActive 0;
BA_ "Confidence" SG_ 325 ESP_driverBrakeApply 0;
BA_ "GenSigSNA" SG_ 325 ESP_driverBrakeApply "3";
BA_ "Confidence" SG_ 325 ESP_brakeApply 0;
BA_ "Confidence" SG_ 325 ESP_aesPrimaryActuatorStatus 0;
BA_ "Confidence" SG_ 325 ESP_cdpStatus 0;
BA_ "Confidence" SG_ 325 ESP_ptcTargetState 0;
BA_ "GenSigSNA" SG_ 325 ESP_ptcTargetState "3";
BA_ "Confidence" SG_ 325 ESP_btcTargetState 0;
BA_ "GenSigSNA" SG_ 325 ESP_btcTargetState "3";
BA_ "Confidence" SG_ 325 ESP_decoupledBrakePressEst 0;
BA_ "GenSigSNA" SG_ 325 ESP_decoupledBrakePressEst "255";
BA_ "Confidence" SG_ 325 ESP_ebrStandstillSkid 0;
BA_ "Confidence" SG_ 325 ESP_ebrStatus 0;
BA_ "Confidence" SG_ 325 ESP_brakeTorqueTarget 0;
BA_ "Confidence" SG_ 373 ESP_wheelSpeedFrL 1;
BA_ "Confidence" SG_ 373 ESP_wheelSpeedFrR 1;
BA_ "Confidence" SG_ 373 ESP_wheelSpeedReL 1;
BA_ "Confidence" SG_ 373 ESP_wheelSpeedReR 1;
BA_ "Confidence" SG_ 925 IBST_statusChecksum 0;
BA_ "Confidence" SG_ 925 IBST_statusCounter 0;
BA_ "Confidence" SG_ 925 IBST_iBoosterStatus 0;
BA_ "Confidence" SG_ 925 IBST_driverBrakeApply 0;
BA_ "Confidence" SG_ 925 IBST_internalState 0;
BA_ "Confidence" SG_ 925 IBST_sInputRodDriver 0;
BA_ "Confidence" SG_ 925 IBST_LVPowerModeState 0;
BA_ "Confidence" SG_ 1316 PMF_processorDieIdLot 0;
BA_ "Confidence" SG_ 1316 PMF_processorDieIdWafer 0;
BA_ "Confidence" SG_ 1316 PMF_processorDieIdX 0;
BA_ "Confidence" SG_ 1316 PMF_processorDieIdY 0;
BA_ "Confidence" SG_ 1364 PMR_processorDieIdLot 0;
BA_ "Confidence" SG_ 1364 PMR_processorDieIdWafer 0;
BA_ "Confidence" SG_ 1364 PMR_processorDieIdX 0;
BA_ "Confidence" SG_ 1364 PMR_processorDieIdY 0;
BA_ "Confidence" SG_ 1973 PM_itpmsDisplaySelector 1;
BA_ "Confidence" SG_ 1973 PM_indirectTPMSTellTale 0;
BA_ "Confidence" SG_ 1973 PM_indirectTPMSDisplayState 0;
BA_ "Confidence" SG_ 1973 PM_indirectTPMSDisplayProgress 0;
BA_ "Confidence" SG_ 1973 PM_indirectTPMSDisplayWarningInd 0;
BA_ "SystemSignalLongSymbol" SG_ 1973 PM_indirectTPMSDisplayWarningInd "PM_indirectTPMSDisplayWarningIndicatorFL";
BA_ "Confidence" SG_ 1973 PM_indirectTPMSDisplayWarni_0001 0;
BA_ "SystemSignalLongSymbol" SG_ 1973 PM_indirectTPMSDisplayWarni_0001 "PM_indirectTPMSDisplayWarningIndicatorFR";
BA_ "Confidence" SG_ 1973 PM_indirectTPMSDisplayWarni_0002 0;
BA_ "SystemSignalLongSymbol" SG_ 1973 PM_indirectTPMSDisplayWarni_0002 "PM_indirectTPMSDisplayWarningIndicatorRL";
BA_ "Confidence" SG_ 1973 PM_indirectTPMSDisplayWarni_0003 0;
BA_ "SystemSignalLongSymbol" SG_ 1973 PM_indirectTPMSDisplayWarni_0003 "PM_indirectTPMSDisplayWarningIndicatorRR";
BA_ "Confidence" SG_ 1973 PM_indirectTPMSRecommendedColdPr 0;
BA_ "GenSigSNA" SG_ 1973 PM_indirectTPMSRecommendedColdPr "255";
BA_ "SystemSignalLongSymbol" SG_ 1973 PM_indirectTPMSRecommendedColdPr "PM_indirectTPMSRecommendedColdPressureFront";
BA_ "Confidence" SG_ 1973 PM_indirectTPMSRecommendedC_0001 0;
BA_ "GenSigSNA" SG_ 1973 PM_indirectTPMSRecommendedC_0001 "255";
BA_ "SystemSignalLongSymbol" SG_ 1973 PM_indirectTPMSRecommendedC_0001 "PM_indirectTPMSRecommendedColdPressureRear";
BA_ "Confidence" SG_ 1973 PM_fusedPressureEstimateFrL 0;
BA_ "Confidence" SG_ 1973 PM_fusedPressureEstimateFrR 0;
BA_ "Confidence" SG_ 1973 PM_fusedPressureEstimateReL 0;
BA_ "Confidence" SG_ 1973 PM_fusedPressureEstimateReR 0;
BA_ "Confidence" SG_ 2038 PM_vdcDebugSelector 1;
BA_ "Confidence" SG_ 2038 PM_VDCA_TCSlipTargetMod_RA_Fwd 0;
BA_ "Confidence" SG_ 2038 PM_VDCA_TCSlipTargetMod_RA_Rwd 0;
BA_ "Confidence" SG_ 2038 PM_VSE_forceY_RA 0;
BA_ "Confidence" SG_ 2038 PM_VDCT_observerSlipAngle_RA 0;
BA_ "Confidence" SG_ 2038 PM_VSE_muVehicleFxLow 0;
BA_ "Confidence" SG_ 2038 PM_VE_fxmFres 0;
BA_ "Confidence" SG_ 2038 PM_VE_fxAccelMass 0;
BA_ "Confidence" SG_ 2038 PM_VE_vxDotGrade 0;
BA_ "Confidence" SG_ 2038 PM_VE_betaEst 0;
BA_ "Confidence" SG_ 2038 PM_VSE_muVehicleFxHigh 0;
BA_ "Confidence" SG_ 2038 PM_VSE_muVehicleDecLeakRate 0;
BA_ "Confidence" SG_ 2038 PM_VSE_muVehicleLearnDown 0;
BA_ "Confidence" SG_ 2038 PM_VSE_muVehicleDecFilter 0;
BA_ "Confidence" SG_ 2038 PM_VSE_muVehicleLatDecLeakRate 0;
BA_ "Confidence" SG_ 2038 PM_VSE_splitMuProbability 0;
BA_ "Confidence" SG_ 2038 PM_VSE_splitMuTotalMz 0;
BA_ "Confidence" SG_ 2038 PM_VSE_attitudeBankAngle 0;
BA_ "Confidence" SG_ 2038 PM_VSE_attitudeDBetaInControl 0;
BA_ "Confidence" SG_ 2038 PM_VSE_roadWheelAngleAverage 0;
BA_ "Confidence" SG_ 17 RCM_collisionChecksum 0;
BA_ "Confidence" SG_ 17 RCM_collisionCounter 0;
BA_ "Confidence" SG_ 17 RCM_collisionRear 0;
BA_ "GenSigSNA" SG_ 17 RCM_collisionRear "3";
BA_ "Confidence" SG_ 17 RCM_collisionRight 0;
BA_ "GenSigSNA" SG_ 17 RCM_collisionRight "3";
BA_ "Confidence" SG_ 17 RCM_collisionLeft 0;
BA_ "GenSigSNA" SG_ 17 RCM_collisionLeft "3";
BA_ "Confidence" SG_ 17 RCM_collisionFront 0;
BA_ "GenSigSNA" SG_ 17 RCM_collisionFront "3";
BA_ "Confidence" SG_ 17 RCM_collisionRollover 0;
BA_ "GenSigSNA" SG_ 17 RCM_collisionRollover "3";
BA_ "Confidence" SG_ 17 RCM_collisionPedPro 0;
BA_ "GenSigSNA" SG_ 17 RCM_collisionPedPro "3";
BA_ "Confidence" SG_ 17 RCM_collisionSeverity 0;
BA_ "Confidence" SG_ 289 RCM_nearDeployChecksum 0;
BA_ "Confidence" SG_ 289 RCM_nearDeployCounter 0;
BA_ "Confidence" SG_ 289 RCM_nearDeployRear 0;
BA_ "GenSigSNA" SG_ 289 RCM_nearDeployRear "3";
BA_ "Confidence" SG_ 289 RCM_nearDeployRight 0;
BA_ "GenSigSNA" SG_ 289 RCM_nearDeployRight "3";
BA_ "Confidence" SG_ 289 RCM_nearDeployLeft 0;
BA_ "GenSigSNA" SG_ 289 RCM_nearDeployLeft "3";
BA_ "Confidence" SG_ 289 RCM_nearDeployFront 0;
BA_ "GenSigSNA" SG_ 289 RCM_nearDeployFront "3";
BA_ "Confidence" SG_ 289 RCM_nearDeployRollover 0;
BA_ "GenSigSNA" SG_ 289 RCM_nearDeployRollover "3";
BA_ "Confidence" SG_ 289 RCM_crashAlgoWakeup 0;
BA_ "GenSigSNA" SG_ 289 RCM_crashAlgoWakeup "3";
BA_ "Confidence" SG_ 1618 VCBATT0_infoIndex 1;
BA_ "Confidence" SG_ 1618 VCBATT0_infoBuildType 0;
BA_ "Confidence" SG_ 1618 VCBATT0_infoBuildConfigId 0;
BA_ "Confidence" SG_ 1618 VCBATT0_infoHardwareId 0;
BA_ "Confidence" SG_ 1618 VCBATT0_infoComponentId 0;
BA_ "Confidence" SG_ 1618 VCBATT0_infoPcbaId 0;
BA_ "Confidence" SG_ 1618 VCBATT0_infoAssemblyId 0;
BA_ "GenSigSNA" SG_ 1618 VCBATT0_infoAssemblyId "255";
BA_ "Confidence" SG_ 1618 VCBATT0_infoUsageId 0;
BA_ "Confidence" SG_ 1618 VCBATT0_infoSubUsageId 0;
BA_ "Confidence" SG_ 1618 VCBATT0_infoAppCrc 0;
BA_ "Confidence" SG_ 1618 VCBATT0_infoAppGitHash 0;
BA_ "Confidence" SG_ 1618 VCBATT0_infoBootGitHash 0;
BA_ "Confidence" SG_ 1618 VCBATT0_infoBootUdsProtoVersion 0;
BA_ "Confidence" SG_ 1618 VCBATT0_infoBootCrc 0;
BA_ "Confidence" SG_ 1994 VCCC_infoIndex 1;
BA_ "Confidence" SG_ 1994 VCCC_infoBuildType 0;
BA_ "Confidence" SG_ 1994 VCCC_infoBuildConfigId 0;
BA_ "Confidence" SG_ 1994 VCCC_infoHardwareId 0;
BA_ "Confidence" SG_ 1994 VCCC_infoComponentId 0;
BA_ "Confidence" SG_ 1994 VCCC_infoPcbaId 0;
BA_ "Confidence" SG_ 1994 VCCC_infoAssemblyId 0;
BA_ "GenSigSNA" SG_ 1994 VCCC_infoAssemblyId "255";
BA_ "Confidence" SG_ 1994 VCCC_infoUsageId 0;
BA_ "Confidence" SG_ 1994 VCCC_infoSubUsageId 0;
BA_ "Confidence" SG_ 1994 VCCC_infoAppCrc 0;
BA_ "Confidence" SG_ 1994 VCCC_infoAppGitHash 0;
BA_ "Confidence" SG_ 1994 VCCC_infoBootGitHash 0;
BA_ "Confidence" SG_ 1994 VCCC_infoBootUdsProtoVersion 0;
BA_ "Confidence" SG_ 1994 VCCC_infoBootCrc 0;
BA_ "Confidence" SG_ 260 VCFRONT_vcleftHighPower 0;
BA_ "Confidence" SG_ 260 VCFRONT_vcrightHighPower 0;
BA_ "Confidence" SG_ 260 VCFRONT_uiHighPower 0;
BA_ "Confidence" SG_ 260 VCFRONT_5VAStable 0;
BA_ "Confidence" SG_ 260 VCFRONT_5VBStable 0;
BA_ "Confidence" SG_ 260 VCFRONT_12VAStable 0;
BA_ "Confidence" SG_ 260 VCFRONT_12VBStable 0;
BA_ "Confidence" SG_ 260 VCFRONT_railA 0;
BA_ "Confidence" SG_ 260 VCFRONT_railB 0;
BA_ "Confidence" SG_ 260 VCFRONT_chargePumpStable 0;
BA_ "Confidence" SG_ 260 VCFRONT_vehicleSM 0;
BA_ "GenSigSNA" SG_ 260 VCFRONT_vehicleSM "18";
BA_ "Confidence" SG_ 260 VCFRONT_revBattFault 0;
BA_ "Confidence" SG_ 260 VCFRONT_battSM 0;
BA_ "Confidence" SG_ 260 VCFRONT_U13Init 0;
BA_ "Confidence" SG_ 260 VCFRONT_U16Init 0;
BA_ "Confidence" SG_ 260 VCFRONT_anyVehLoadShedActiveDBG 0;
BA_ "Confidence" SG_ 260 VCFRONT_battVoltage 0;
BA_ "Confidence" SG_ 260 VCFRONT_battCurrent 0;
BA_ "Confidence" SG_ 258 VCLEFT_doorClosureStatusFront 0;
BA_ "GenSigSNA" SG_ 258 VCLEFT_doorClosureStatusFront "0";
BA_ "Confidence" SG_ 258 VCLEFT_doorClosureStatusRear 0;
BA_ "GenSigSNA" SG_ 258 VCLEFT_doorClosureStatusRear "0";
BA_ "Confidence" SG_ 258 VCLEFT_frontLatchSwitch 0;
BA_ "Confidence" SG_ 258 VCLEFT_rearLatchSwitch 0;
BA_ "Confidence" SG_ 258 VCLEFT_frontHandlePulled 0;
BA_ "Confidence" SG_ 258 VCLEFT_rearHandlePulled 0;
BA_ "Confidence" SG_ 258 VCLEFT_frontRelActuatorSwitch 0;
BA_ "Confidence" SG_ 258 VCLEFT_rearRelActuatorSwitch 0;
BA_ "Confidence" SG_ 258 VCLEFT_frontLatchStatus 0;
BA_ "GenSigSNA" SG_ 258 VCLEFT_frontLatchStatus "0";
BA_ "Confidence" SG_ 258 VCLEFT_rearLatchStatus 0;
BA_ "GenSigSNA" SG_ 258 VCLEFT_rearLatchStatus "0";
BA_ "Confidence" SG_ 258 VCLEFT_lastDoorReqSourceFront 0;
BA_ "Confidence" SG_ 258 VCLEFT_lastDoorReqSourceRear 0;
BA_ "Confidence" SG_ 258 VCLEFT_frontIntSwitchFaulted 0;
BA_ "Confidence" SG_ 258 VCLEFT_rearIntSwitchFaulted 0;
BA_ "Confidence" SG_ 258 VCLEFT_frontIntSwitchPressed 0;
BA_ "Confidence" SG_ 258 VCLEFT_rearIntSwitchPressed 0;
BA_ "Confidence" SG_ 258 VCLEFT_mirrorTiltXPosition 0;
BA_ "Confidence" SG_ 258 VCLEFT_mirrorTiltYPosition 0;
BA_ "Confidence" SG_ 258 VCLEFT_mirrorState 0;
BA_ "Confidence" SG_ 258 VCLEFT_mirrorFoldState 0;
BA_ "Confidence" SG_ 258 VCLEFT_mirrorRecallState 0;
BA_ "Confidence" SG_ 258 VCLEFT_mirrorHeatState 0;
BA_ "GenSigSNA" SG_ 258 VCLEFT_mirrorHeatState "0";
BA_ "Confidence" SG_ 258 VCLEFT_rearHandlePulledPersist 0;
BA_ "Confidence" SG_ 258 VCLEFT_frontHandlePulledPersist 0;
BA_ "Confidence" SG_ 258 VCLEFT_mirrorDipped 0;
BA_ "Confidence" SG_ 546 VCLEFT_cdpRequestState 0;
BA_ "Confidence" SG_ 546 VCLEFT_epbmSystemStatusQF 0;
BA_ "Confidence" SG_ 546 VCLEFT_epbmUnitStatus 0;
BA_ "Confidence" SG_ 546 VCLEFT_epbmCdpState 0;
BA_ "Confidence" SG_ 546 VCLEFT_epbmRedundantBrakingEnabl 0;
BA_ "SystemSignalLongSymbol" SG_ 546 VCLEFT_epbmRedundantBrakingEnabl "VCLEFT_epbmRedundantBrakingEnabled";
BA_ "Confidence" SG_ 546 VCLEFT_epbmStatusCounter 0;
BA_ "Confidence" SG_ 546 VCLEFT_epbmStatusChecksum 0;
BA_ "Confidence" SG_ 778 VCLEFT_frontOccupancyStatus 0;
BA_ "GenSigSNA" SG_ 778 VCLEFT_frontOccupancyStatus "7";
BA_ "Confidence" SG_ 778 VCLEFT_frontBuckleStatus 0;
BA_ "Confidence" SG_ 778 VCLEFT_rearLeftOccupancyStatus 0;
BA_ "Confidence" SG_ 778 VCLEFT_rearCenterOccupancyStatus 0;
BA_ "Confidence" SG_ 778 VCLEFT_rearRightOccupancyStatus 0;
BA_ "Confidence" SG_ 778 VCLEFT_rearLeftBuckleStatus 0;
BA_ "Confidence" SG_ 778 VCLEFT_rearCenterBuckleStatus 0;
BA_ "Confidence" SG_ 778 VCLEFT_seatTrackPosition 0;
BA_ "GenSigSNA" SG_ 778 VCLEFT_seatTrackPosition "7";
BA_ "Confidence" SG_ 778 VCLEFT_3RowLeftABStatus 0;
BA_ "GenSigSNA" SG_ 778 VCLEFT_3RowLeftABStatus "2";
BA_ "Confidence" SG_ 778 VCLEFT_3RowLeftBuckleStatus 0;
BA_ "Confidence" SG_ 778 VCLEFT_restraintStatusCounter 0;
BA_ "Confidence" SG_ 778 VCLEFT_restraintStatusChecksum 0;
BA_ "Confidence" SG_ 1124 VCRIGHT_AP_hvacState1HzIndex 1;
BA_ "Confidence" SG_ 1124 VCRIGHT_AP_tempCameraModele_0001 0;
BA_ "GenSigSNA" SG_ 1124 VCRIGHT_AP_tempCameraModele_0001 "255";
BA_ "SystemSignalLongSymbol" SG_ 1124 VCRIGHT_AP_tempCameraModele_0001 "VCRIGHT_AP_tempCameraModeledWindshieldOut";
BA_ "Confidence" SG_ 1124 VCRIGHT_AP_tempCameraModeledWind 0;
BA_ "GenSigSNA" SG_ 1124 VCRIGHT_AP_tempCameraModeledWind "255";
BA_ "SystemSignalLongSymbol" SG_ 1124 VCRIGHT_AP_tempCameraModeledWind "VCRIGHT_AP_tempCameraModeledWindshieldIn";
BA_ "Confidence" SG_ 1124 VCRIGHT_AP_cameraModeledWin_0001 0;
BA_ "GenSigSNA" SG_ 1124 VCRIGHT_AP_cameraModeledWin_0001 "127";
BA_ "SystemSignalLongSymbol" SG_ 1124 VCRIGHT_AP_cameraModeledWin_0001 "VCRIGHT_AP_cameraModeledWindshieldOutRh";
BA_ "Confidence" SG_ 1124 VCRIGHT_AP_cameraModeledWindshie 0;
BA_ "GenSigSNA" SG_ 1124 VCRIGHT_AP_cameraModeledWindshie "127";
BA_ "SystemSignalLongSymbol" SG_ 1124 VCRIGHT_AP_cameraModeledWindshie "VCRIGHT_AP_cameraModeledWindshieldInRh";
BA_ "Confidence" SG_ 1124 VCRIGHT_AP_maxAchievableASideTem 0;
BA_ "SystemSignalLongSymbol" SG_ 1124 VCRIGHT_AP_maxAchievableASideTem "VCRIGHT_AP_maxAchievableASideTempCameraPocket";
BA_ "Confidence" SG_ 1124 VCRIGHT_AP_cameraModeledPocketWa 0;
BA_ "GenSigSNA" SG_ 1124 VCRIGHT_AP_cameraModeledPocketWa "1023";
BA_ "SystemSignalLongSymbol" SG_ 1124 VCRIGHT_AP_cameraModeledPocketWa "VCRIGHT_AP_cameraModeledPocketWaterMass";
BA_ "Confidence" SG_ 1124 VCRIGHT_AP_humidityModelInitStat 0;
BA_ "SystemSignalLongSymbol" SG_ 1124 VCRIGHT_AP_humidityModelInitStat "VCRIGHT_AP_humidityModelInitStatus";
BA_ "Confidence" SG_ 1124 VCRIGHT_AP_humidityModelStatus 0;
BA_ "Confidence" SG_ 259 VCRIGHT_doorClosureStatusFront 0;
BA_ "GenSigSNA" SG_ 259 VCRIGHT_doorClosureStatusFront "0";
BA_ "Confidence" SG_ 259 VCRIGHT_doorClosureStatusRear 0;
BA_ "GenSigSNA" SG_ 259 VCRIGHT_doorClosureStatusRear "0";
BA_ "Confidence" SG_ 259 VCRIGHT_frontLatchSwitch 0;
BA_ "Confidence" SG_ 259 VCRIGHT_rearLatchSwitch 0;
BA_ "Confidence" SG_ 259 VCRIGHT_frontHandlePulled 0;
BA_ "Confidence" SG_ 259 VCRIGHT_rearHandlePulled 0;
BA_ "Confidence" SG_ 259 VCRIGHT_frontRelActuatorSwitch 0;
BA_ "Confidence" SG_ 259 VCRIGHT_rearRelActuatorSwitch 0;
BA_ "Confidence" SG_ 259 VCRIGHT_frontLatchStatus 0;
BA_ "GenSigSNA" SG_ 259 VCRIGHT_frontLatchStatus "0";
BA_ "Confidence" SG_ 259 VCRIGHT_rearLatchStatus 0;
BA_ "GenSigSNA" SG_ 259 VCRIGHT_rearLatchStatus "0";
BA_ "Confidence" SG_ 259 VCRIGHT_lastDoorReqSourceFront 0;
BA_ "Confidence" SG_ 259 VCRIGHT_lastDoorReqSourceRear 0;
BA_ "Confidence" SG_ 259 VCRIGHT_frontIntSwitchFaulted 0;
BA_ "Confidence" SG_ 259 VCRIGHT_rearIntSwitchFaulted 0;
BA_ "Confidence" SG_ 259 VCRIGHT_frontHandlePulledPersist 0;
BA_ "Confidence" SG_ 259 VCRIGHT_frontIntSwitchPressed 0;
BA_ "Confidence" SG_ 259 VCRIGHT_rearIntSwitchPressed 0;
BA_ "Confidence" SG_ 259 VCRIGHT_mirrorTiltXPosition 0;
BA_ "Confidence" SG_ 259 VCRIGHT_mirrorTiltYPosition 0;
BA_ "Confidence" SG_ 259 VCRIGHT_mirrorState 0;
BA_ "Confidence" SG_ 259 VCRIGHT_mirrorFoldState 0;
BA_ "Confidence" SG_ 259 VCRIGHT_mirrorDipped 0;
BA_ "Confidence" SG_ 259 VCRIGHT_trunkLatchStatus 0;
BA_ "GenSigSNA" SG_ 259 VCRIGHT_trunkLatchStatus "0";
BA_ "Confidence" SG_ 259 VCRIGHT_mirrorRecallState 0;
BA_ "Confidence" SG_ 259 VCRIGHT_rearHandlePulledPersist 0;
BA_ "Confidence" SG_ 611 VCRIGHT_cdpRequestState 0;
BA_ "Confidence" SG_ 611 VCRIGHT_epbmSystemStatusQF 0;
BA_ "Confidence" SG_ 611 VCRIGHT_epbmUnitStatus 0;
BA_ "Confidence" SG_ 611 VCRIGHT_epbmCdpState 0;
BA_ "Confidence" SG_ 611 VCRIGHT_epbmRedundantBrakingEnab 0;
BA_ "SystemSignalLongSymbol" SG_ 611 VCRIGHT_epbmRedundantBrakingEnab "VCRIGHT_epbmRedundantBrakingEnabled";
BA_ "Confidence" SG_ 611 VCRIGHT_epbmStatusCounter 0;
BA_ "Confidence" SG_ 611 VCRIGHT_epbmStatusChecksum 0;
BA_ "Confidence" SG_ 794 VCRIGHT_frontOccupancyStatus 0;
BA_ "GenSigSNA" SG_ 794 VCRIGHT_frontOccupancyStatus "7";
BA_ "Confidence" SG_ 794 VCRIGHT_frontBuckleStatus 0;
BA_ "Confidence" SG_ 794 VCRIGHT_rearCenterBuckleStatus 0;
BA_ "Confidence" SG_ 794 VCRIGHT_rearRightBuckleStatus 0;
BA_ "Confidence" SG_ 794 VCRIGHT_rearRightOccupancyStatus 0;
BA_ "Confidence" SG_ 794 VCRIGHT_3RowLeftBuckleStatus 0;
BA_ "Confidence" SG_ 794 VCRIGHT_3RowRightBuckleStatus 0;
BA_ "Confidence" SG_ 794 VCRIGHT_3RowLeftOccupancyStatus 0;
BA_ "Confidence" SG_ 794 VCRIGHT_3RowRightOccupancyStatus 0;
BA_ "Confidence" SG_ 794 VCRIGHT_seatTrackPosition 0;
BA_ "GenSigSNA" SG_ 794 VCRIGHT_seatTrackPosition "7";
BA_ "Confidence" SG_ 794 VCRIGHT_occupantClassification 0;
BA_ "GenSigSNA" SG_ 794 VCRIGHT_occupantClassification "7";
BA_ "Confidence" SG_ 794 VCRIGHT_occupantClassificationQF 0;
BA_ "Confidence" SG_ 794 VCRIGHT_classificationEnabled 0;
BA_ "Confidence" SG_ 794 VCRIGHT_classificationEnabledQF 0;
BA_ "Confidence" SG_ 794 VCRIGHT_3RowRightABStatus 0;
BA_ "GenSigSNA" SG_ 794 VCRIGHT_3RowRightABStatus "2";
BA_ "Confidence" SG_ 794 VCRIGHT_restraintStatusCounter 0;
BA_ "Confidence" SG_ 794 VCRIGHT_restraintStatusChecksum 0;
VAL_ 914 EPAS3P_matrixIndex 2 "AlertMatrix2" 1 "AlertMatrix1" 0 "AlertMatrix0" ;
VAL_ 977 EPAS3P_resyncStatus 1 "RESYNC_COMPLETE" 0 "RESYNC_PENDING" ;
VAL_ 817 EPAS3P_infoIndex 255 "END" 31 "SUBCOMPONENT_GITHASH" 30 "PACKAGE_SN_8_14" 29 "PACKAGE_SN_1_7" 27 "PACKAGE_PN_15_20" 26 "PACKAGE_PN_8_14" 25 "PACKAGE_PN_1_7" 23 "SUBCOMPONENT2" 22 "VARIANTCRC" 20 "UDS_PROTOCOL_BOOTCRC" 19 "VERSION_DEPRECATED" 18 "BOOTLOADER_GITHASH" 17 "APP_GITHASH" 16 "SUBCOMPONENT" 15 "BOOTLOADER_CRC" 14 "BOOTLOADER_SVN" 13 "APP_CRC" 11 "PCBAID_ASSYID_USAGEID" 10 "BUILD_HWID_COMPONENTID" 9 "DEPRECATED_9" 8 "DEPRECATED_8" 7 "DEPRECATED_7" 6 "DEPRECATED_6" 5 "DEPRECATED_5" 4 "DEPRECATED_4" 3 "DEPRECATED_3" 2 "DEPRECATED_2" 1 "DEPRECATED_1" 0 "DEPRECATED_0" ;
VAL_ 817 EPAS3P_infoBuildType 4 "INFO_MFG_BUILD" 3 "INFO_TRACEABLE_CI_BUILD" 2 "INFO_LOCAL_BUILD" 1 "INFO_PLATFORM_BUILD" 0 "INFO_UNKNOWN_BUILD" ;
VAL_ 880 EPAS3P_steeringRackForce 1023 "SNA" 1022 "NOT_IN_SPEC" ;
VAL_ 880 EPAS3P_steeringFault 1 "FAULT" 0 "NO_FAULT" ;
VAL_ 880 EPAS3P_steeringReduced 1 "REDUCED_ASSIST" 0 "NORMAL_ASSIST" ;
VAL_ 880 EPAS3P_internalSASQF 1 "IN_SPEC" 0 "UNDEFINABLE_ACCURACY" ;
VAL_ 880 EPAS3P_currentTuneMode 5 "STEERING_TUNE_RWD_SPORT" 4 "STEERING_TUNE_RWD_STANDARD" 3 "STEERING_TUNE_RWD_COMFORT" 2 "STEERING_TUNE_DM_SPORT" 1 "STEERING_TUNE_DM_STANDARD" 0 "STEERING_TUNE_DM_COMFORT" ;
VAL_ 880 EPAS3P_torsionBarTorque 4095 "SNA" 4094 "UNDEFINABLE_DATA" ;
VAL_ 880 EPAS3P_eacErrorCode 15 "SNA" 14 "EAC_EXTERNAL_MONITOR_INHIBIT" 13 "EAC_ERROR_PINION_VEL_DIFF" 12 "EAC_ERROR_LOW_ASSIST" 11 "EAC_ERROR_HIGH_TORSION_SAFETY" 10 "EAC_ERROR_HIGH_MMOT_SAFETY" 9 "EAC_ERROR_HIGH_ANGLE_RATE_SAFETY" 8 "EAC_ERROR_HIGH_ANGLE_SAFETY" 7 "EAC_ERROR_HIGH_ANGLE_RATE_REQ" 6 "EAC_ERROR_HIGH_ANGLE_REQ" 5 "EAR_ERROR_MAX_STEER_DELTA" 4 "EAC_ERROR_TMP_FAULT" 3 "EAC_ERROR_HANDS_ON" 2 "EAC_ERROR_MAX_SPEED" 1 "EAC_ERROR_MIN_SPEED" 0 "EAC_ERROR_IDLE" ;
VAL_ 880 EPAS3P_handsOnLevel 3 "LEVEL_3" 2 "LEVEL_2" 1 "LEVEL_1" 0 "LEVEL_0" ;
VAL_ 880 EPAS3P_driverlessState 1 "EAC_DRIVERLESS_ACTIVE" 0 "EAC_DRIVERLESS_INACTIVE" ;
VAL_ 880 EPAS3P_eacStatus 7 "EAC_ELK_ACTIVE" 6 "EAC_ELK_AVAILABLE" 5 "EAC_LKA_ACTIVE" 4 "EAC_LKA_ELK_AVAILABLE" 3 "EAC_FAULT" 2 "EAC_ACTIVE" 1 "EAC_AVAILABLE" 0 "EAC_INHIBITED" ;
VAL_ 909 ESP_absActive 1 "ABS_ACTIVE" 0 "ABS_NOT_ACTIVE" ;
VAL_ 909 ESP_vehicleStandstill 1 "STANDSTILL" 0 "NOT_STANDSTILL" ;
VAL_ 909 ESP_vehicleStandstillQF 2 "STANDSTILL_FAULTED" 1 "STANDSTILL_NORMAL" 0 "STANDSTILL_NOT_INIT" ;
VAL_ 909 ESP_decoupledBrakePressOffsetCom 127 "SNA" ;
VAL_ 909 ESP_privateVehicleSpdQF 2 "Faulty" 1 "Normal" 0 "NotInit_orOff" ;
VAL_ 909 ESP_brakeMasterCylPress 1023 "SNA" ;
VAL_ 909 ESP_brakeMasterCylPressQF 3 "PRESSURE_FAULTED2" 2 "PRESSURE_FAULTED" 1 "PRESSURE_NORMAL" 0 "PRESSURE_NOT_INITIALIZED" ;
VAL_ 325 ESP_espModeActive 3 "ESP_MODE_03" 2 "ESP_MODE_02" 1 "ESP_MODE_01" 0 "ESP_MODE_00_NORMAL" ;
VAL_ 325 ESP_stabilityControlSts2 3 "FAULTED" 2 "ENGAGED" 1 "ON" 0 "INIT" ;
VAL_ 325 ESP_ebdFaultLamp 1 "EBD_FAULT_LAMP_ON" 0 "EBD_FAULT_LAMP_OFF" ;
VAL_ 325 ESP_absFaultLamp 1 "ABS_FAULT_LAMP_ON" 0 "ABS_FAULT_LAMP_OFF" ;
VAL_ 325 ESP_espFaultLamp 1 "ESP_FAULT_LAMP_ON" 0 "ESP_FAULT_LAMP_OFF" ;
VAL_ 325 ESP_espLampFlash 1 "ESP_LAMP_FLASH" 0 "ESP_LAMP_OFF" ;
VAL_ 325 ESP_brakeLamp 1 "LAMP_ON" 0 "LAMP_OFF" ;
VAL_ 325 ESP_absBrakeEvent2 3 "ABS_EVENT_ACTIVE_REAR" 2 "ABS_EVENT_ACTIVE_FRONT" 1 "ABS_EVENT_ACTIVE_FRONT_REAR" 0 "ABS_EVENT_NOT_ACTIVE" ;
VAL_ 325 ESP_longitudinalAccelQF 1 "IN_SPEC" 0 "UNDEFINABLE_ACCURACY" ;
VAL_ 325 ESP_lateralAccelQF 1 "IN_SPEC" 0 "UNDEFINABLE_ACCURACY" ;
VAL_ 325 ESP_yawRateQF 1 "IN_SPEC" 0 "UNDEFINABLE_ACCURACY" ;
VAL_ 325 ESP_steeringAngleQF 1 "IN_SPEC" 0 "UNDEFINABLE_ACCURACY" ;
VAL_ 325 ESP_brakeDiscWipingActive 1 "BDW_ACTIVE" 0 "BDW_INACTIVE" ;
VAL_ 325 ESP_driverBrakeApply 3 "Faulty_SNA" 2 "Driver_applying_brakes" 1 "Not_Applied" 0 "NotInit_orOff" ;
VAL_ 325 ESP_brakeApply 1 "BLS_ACTIVE" 0 "BLS_INACTIVE" ;
VAL_ 325 ESP_aesPrimaryActuatorStatus 3 "AES_FAILURE" 2 "AES_ACTIVE" 1 "AES_AVAILABLE" 0 "AES_NOT_SUPPORTED_OR_NOT_INIT" ;
VAL_ 325 ESP_cdpStatus 3 "CDP_COMMAND_INVALID" 2 "ACTUATING_EPB_CDP" 1 "CDP_IS_AVAILABLE" 0 "CDP_IS_NOT_AVAILABLE" ;
VAL_ 325 ESP_ptcTargetState 3 "SNA" 2 "ON" 1 "BACKUP" 0 "FAULT" ;
VAL_ 325 ESP_btcTargetState 3 "SNA" 2 "ON" 1 "BACKUP" 0 "OFF" ;
VAL_ 325 ESP_decoupledBrakePressEst 255 "SNA" ;
VAL_ 325 ESP_ebrStandstillSkid 1 "STANDSTILL_SKID_DETECTED" 0 "NO_STANDSTILL_SKID" ;
VAL_ 325 ESP_ebrStatus 3 "EBR_COMMAND_INVALID" 2 "ACTUATING_DI_EBR" 1 "EBR_IS_AVAILABLE" 0 "EBR_IS_NOT_AVAILABLE" ;
VAL_ 373 ESP_wheelSpeedFrL 8191 "SNA" ;
VAL_ 373 ESP_wheelSpeedFrR 8191 "SNA" ;
VAL_ 373 ESP_wheelSpeedReL 8191 "SNA" ;
VAL_ 373 ESP_wheelSpeedReR 8191 "SNA" ;
VAL_ 925 IBST_iBoosterStatus 6 "IBOOSTER_ACTUATION" 5 "IBOOSTER_READY" 4 "IBOOSTER_ACTIVE_GOOD_CHECK" 3 "IBOOSTER_DIAGNOSTIC" 2 "IBOOSTER_FAILURE" 1 "IBOOSTER_INIT" 0 "IBOOSTER_OFF" ;
VAL_ 925 IBST_driverBrakeApply 3 "FAULT" 2 "DRIVER_APPLYING_BRAKES" 1 "BRAKES_NOT_APPLIED" 0 "NOT_INIT_OR_OFF" ;
VAL_ 925 IBST_internalState 6 "POST_DRIVE_CHECK" 5 "TRANSITION_TO_IDLE" 4 "DIAGNOSTIC" 3 "EXTERNAL_BRAKE_REQUEST" 2 "LOCAL_BRAKE_REQUEST" 1 "PRE_DRIVE_CHECK" 0 "NO_MODE_ACTIVE" ;
VAL_ 925 IBST_LVPowerModeState 3 "PEAK_POWER_REDUCTION_RESERVED" 2 "PEAK_POWER_REDUCTION_ACTIVE_MAX600W_NOMINAL350W" 1 "PEAK_POWER_REDUCTION_AVAILABLE" 0 "PEAK_POWER_REDUCTION_NOT_SUPPORTED" ;
VAL_ 1973 PM_itpmsDisplaySelector 3 "Mux3" 2 "Mux2" 1 "Mux1" 0 "Mux0" ;
VAL_ 1973 PM_indirectTPMSTellTale 2 "TPMS_TELLTALE_FLASHING" 1 "TPMS_TELLTALE_SOLID" 0 "TPMS_TELLTALE_OFF" ;
VAL_ 1973 PM_indirectTPMSDisplayState 3 "FAULTED" 2 "CALIBRATED" 1 "CALIBRATING" 0 "UNAVAILABLE" ;
VAL_ 1973 PM_indirectTPMSDisplayWarningInd 2 "HARD" 1 "SOFT" 0 "NONE" ;
VAL_ 1973 PM_indirectTPMSDisplayWarni_0001 2 "HARD" 1 "SOFT" 0 "NONE" ;
VAL_ 1973 PM_indirectTPMSDisplayWarni_0002 2 "HARD" 1 "SOFT" 0 "NONE" ;
VAL_ 1973 PM_indirectTPMSDisplayWarni_0003 2 "HARD" 1 "SOFT" 0 "NONE" ;
VAL_ 1973 PM_indirectTPMSRecommendedColdPr 255 "SNA" 254 "OVER_RANGE" ;
VAL_ 1973 PM_indirectTPMSRecommendedC_0001 255 "SNA" 254 "OVER_RANGE" ;
VAL_ 2038 PM_vdcDebugSelector 32 "Mux32" 31 "Mux31" 30 "Mux30" 29 "Mux29" 28 "Mux28" 27 "Mux27" 26 "Mux26" 25 "Mux25" 24 "Mux24" 23 "Mux23" 22 "Mux22" 21 "Mux21" 20 "Mux20" 19 "Mux19" 18 "Mux18" 17 "Mux17" 16 "Mux16" 15 "Mux15" 14 "Mux14" 13 "Mux13" 12 "Mux12" 11 "Mux11" 10 "Mux10" 9 "Mux9" 8 "Mux8" 7 "Mux7" 6 "Mux6" 5 "Mux5" 4 "Mux4" 3 "Mux3" 2 "Mux2" 1 "Mux1" 0 "Mux0" ;
VAL_ 17 RCM_collisionRear 3 "RCM_COLLISION_EVENT_SNA" 1 "RCM_COLLISION_EVENT_ACTIVE" 0 "RCM_COLLISION_EVENT_INACTIVE" ;
VAL_ 17 RCM_collisionRight 3 "RCM_COLLISION_EVENT_SNA" 1 "RCM_COLLISION_EVENT_ACTIVE" 0 "RCM_COLLISION_EVENT_INACTIVE" ;
VAL_ 17 RCM_collisionLeft 3 "RCM_COLLISION_EVENT_SNA" 1 "RCM_COLLISION_EVENT_ACTIVE" 0 "RCM_COLLISION_EVENT_INACTIVE" ;
VAL_ 17 RCM_collisionFront 3 "RCM_COLLISION_EVENT_SNA" 1 "RCM_COLLISION_EVENT_ACTIVE" 0 "RCM_COLLISION_EVENT_INACTIVE" ;
VAL_ 17 RCM_collisionRollover 3 "RCM_COLLISION_EVENT_SNA" 1 "RCM_COLLISION_EVENT_ACTIVE" 0 "RCM_COLLISION_EVENT_INACTIVE" ;
VAL_ 17 RCM_collisionPedPro 3 "RCM_COLLISION_EVENT_SNA" 1 "RCM_COLLISION_EVENT_ACTIVE" 0 "RCM_COLLISION_EVENT_INACTIVE" ;
VAL_ 17 RCM_collisionSeverity 3 "RCM_COLLISION_SEVERITY_PEDPRO_EVENT" 2 "RCM_COLLISION_SEVERITY_SECOND_STAGE" 1 "RCM_COLLISION_SEVERITY_FIRST_STAGE" 0 "RCM_COLLISION_SEVERITY_PRETENSIONER" ;
VAL_ 289 RCM_nearDeployRear 3 "RCM_NEAR_DEPLOY_EVENT_SNA" 1 "RCM_NEAR_DEPLOY_EVENT_ACTIVE" 0 "RCM_NEAR_DEPLOY_EVENT_INACTIVE" ;
VAL_ 289 RCM_nearDeployRight 3 "RCM_NEAR_DEPLOY_EVENT_SNA" 1 "RCM_NEAR_DEPLOY_EVENT_ACTIVE" 0 "RCM_NEAR_DEPLOY_EVENT_INACTIVE" ;
VAL_ 289 RCM_nearDeployLeft 3 "RCM_NEAR_DEPLOY_EVENT_SNA" 1 "RCM_NEAR_DEPLOY_EVENT_ACTIVE" 0 "RCM_NEAR_DEPLOY_EVENT_INACTIVE" ;
VAL_ 289 RCM_nearDeployFront 3 "RCM_NEAR_DEPLOY_EVENT_SNA" 1 "RCM_NEAR_DEPLOY_EVENT_ACTIVE" 0 "RCM_NEAR_DEPLOY_EVENT_INACTIVE" ;
VAL_ 289 RCM_nearDeployRollover 3 "RCM_NEAR_DEPLOY_EVENT_SNA" 1 "RCM_NEAR_DEPLOY_EVENT_ACTIVE" 0 "RCM_NEAR_DEPLOY_EVENT_INACTIVE" ;
VAL_ 289 RCM_crashAlgoWakeup 3 "RCM_CRASH_ALGO_WAKEUP_EVENT_SNA" 1 "RCM_CRASH_ALGO_WAKEUP_EVENT_ACTIVE" 0 "RCM_CRASH_ALGO_WAKEUP_EVENT_INACTIVE" ;
VAL_ 1618 VCBATT0_infoIndex 255 "END" 41 "SUBCOMPONENT14" 40 "SUBCOMPONENT13" 39 "SUBCOMPONENT12" 38 "SUBCOMPONENT11" 37 "SUBCOMPONENT10" 36 "SUBCOMPONENT9" 35 "SUBCOMPONENT8" 34 "SUBCOMPONENT7" 33 "SUBCOMPONENT6" 32 "SUBCOMPONENT5" 31 "SUBCOMPONENT4" 24 "SUBCOMPONENT3" 23 "SUBCOMPONENT2" 20 "UDS_PROTOCOL_BOOTCRC" 19 "VERSION_DEPRECATED" 18 "BOOTLOADER_GITHASH" 17 "APP_GITHASH" 16 "SUBCOMPONENT1" 15 "BOOTLOADER_CRC" 14 "BOOTLOADER_SVN" 13 "APP_CRC" 11 "PCBAID_ASSYID_USAGEID" 10 "BUILD_HWID_COMPONENTID" 9 "DEPRECATED_9" 8 "DEPRECATED_8" 7 "DEPRECATED_7" 6 "DEPRECATED_6" 5 "DEPRECATED_5" 4 "DEPRECATED_4" 3 "DEPRECATED_3" 2 "DEPRECATED_2" 1 "DEPRECATED_1" 0 "DEPRECATED_0" ;
VAL_ 1618 VCBATT0_infoBuildType 4 "INFO_MFG_BUILD" 3 "INFO_TRACEABLE_CI_BUILD" 2 "INFO_LOCAL_BUILD" 1 "INFO_PLATFORM_BUILD" 0 "INFO_UNKNOWN_BUILD" ;
VAL_ 1618 VCBATT0_infoAssemblyId 255 "ASSEMBLY_SNA" 1 "ASSEMBLY1" ;
VAL_ 1994 VCCC_infoIndex 255 "END" 41 "SUBCOMPONENT14" 40 "SUBCOMPONENT13" 39 "SUBCOMPONENT12" 38 "SUBCOMPONENT11" 37 "SUBCOMPONENT10" 36 "SUBCOMPONENT9" 35 "SUBCOMPONENT8" 34 "SUBCOMPONENT7" 33 "SUBCOMPONENT6" 32 "SUBCOMPONENT5" 31 "SUBCOMPONENT4" 24 "SUBCOMPONENT3" 23 "SUBCOMPONENT2" 20 "UDS_PROTOCOL_BOOTCRC" 19 "VERSION_DEPRECATED" 18 "BOOTLOADER_GITHASH" 17 "APP_GITHASH" 16 "SUBCOMPONENT1" 15 "BOOTLOADER_CRC" 14 "BOOTLOADER_SVN" 13 "APP_CRC" 11 "PCBAID_ASSYID_USAGEID" 10 "BUILD_HWID_COMPONENTID" 9 "DEPRECATED_9" 8 "DEPRECATED_8" 7 "DEPRECATED_7" 6 "DEPRECATED_6" 5 "DEPRECATED_5" 4 "DEPRECATED_4" 3 "DEPRECATED_3" 2 "DEPRECATED_2" 1 "DEPRECATED_1" 0 "DEPRECATED_0" ;
VAL_ 1994 VCCC_infoBuildType 4 "INFO_MFG_BUILD" 3 "INFO_TRACEABLE_CI_BUILD" 2 "INFO_LOCAL_BUILD" 1 "INFO_PLATFORM_BUILD" 0 "INFO_UNKNOWN_BUILD" ;
VAL_ 1994 VCCC_infoAssemblyId 255 "ASSEMBLY_SNA" 1 "ASSEMBLY1" ;
VAL_ 260 VCFRONT_vehicleSM 18 "VEHICLE_STATUS_SNA" 17 "VEHICLE_STATUS_RESET" 16 "VEHICLE_STATUS_TURN_ON_RAILS" 15 "VEHICLE_STATUS_OTA" 14 "VEHICLE_STATUS_CRASH" 13 "VEHICLE_STATUS_DRIVE" 12 "VEHICLE_STATUS_CONDITIONING" 11 "VEHICLE_STATUS_ACCESSORY_PLUS" 10 "VEHICLE_STATUS_ACCESSORY" 9 "VEHICLE_STATUS_HV_UP_STANDBY" 8 "VEHICLE_STATUS_LV_AWAKE" 7 "VEHICLE_STATUS_LV_SHUTDOWN" 6 "VEHICLE_STATUS_SLEEP_STANDBY" 5 "VEHICLE_STATUS_SLEEP_SHUTDOWN" 4 "VEHICLE_STATUS_SYSTEM_CHECKS" 3 "VEHICLE_STATUS_BATTERY_POST_WAKE" 2 "VEHICLE_STATUS_SILENT_WAKE" 1 "VEHICLE_STATUS_LOW_POWER_STANDBY" 0 "VEHICLE_STATUS_INIT" ;
VAL_ 260 VCFRONT_battSM 10 "BATTERY_SM_STATE_EXTERNAL_LV_BUS_CONTROL" 9 "BATTERY_SM_STATE_RECOVERY" 8 "BATTERY_SM_STATE_FAULT" 7 "BATTERY_SM_STATE_SHORTED_CELL_TEST" 6 "BATTERY_SM_STATE_DISCONNECTED_BATTERY_TEST" 5 "BATTERY_SM_STATE_OTA_STANDBY" 4 "BATTERY_SM_STATE_RESISTANCE_ESTIMATION" 3 "BATTERY_SM_STATE_STANDBY" 2 "BATTERY_SM_STATE_DISCHARGE" 1 "BATTERY_SM_STATE_CHARGE" 0 "BATTERY_SM_STATE_INIT" ;
VAL_ 258 VCLEFT_doorClosureStatusFront 8 "CLOSURE_STATUS_FAULT" 2 "CLOSURE_STATUS_CLOSED" 1 "CLOSURE_STATUS_OPEN" 0 "CLOSURE_STATUS_SNA" ;
VAL_ 258 VCLEFT_doorClosureStatusRear 8 "CLOSURE_STATUS_FAULT" 2 "CLOSURE_STATUS_CLOSED" 1 "CLOSURE_STATUS_OPEN" 0 "CLOSURE_STATUS_SNA" ;
VAL_ 258 VCLEFT_frontLatchStatus 8 "LATCH_FAULT" 7 "LATCH_DEFAULT" 6 "LATCH_TIMEOUT" 5 "LATCH_AJAR" 4 "LATCH_OPENING" 3 "LATCH_CLOSING" 2 "LATCH_CLOSED" 1 "LATCH_OPENED" 0 "LATCH_SNA" ;
VAL_ 258 VCLEFT_rearLatchStatus 8 "LATCH_FAULT" 7 "LATCH_DEFAULT" 6 "LATCH_TIMEOUT" 5 "LATCH_AJAR" 4 "LATCH_OPENING" 3 "LATCH_CLOSING" 2 "LATCH_CLOSED" 1 "LATCH_OPENED" 0 "LATCH_SNA" ;
VAL_ 258 VCLEFT_lastDoorReqSourceFront 4 "DOOR_REQUEST_SOURCE_ECU" 3 "DOOR_REQUEST_SOURCE_VCSEC" 2 "DOOR_REQUEST_SOURCE_EXTERIOR_HANDLE" 1 "DOOR_REQUEST_SOURCE_INTERIOR_BUTTON" 0 "DOOR_REQUEST_SOURCE_UNKNOWN" ;
VAL_ 258 VCLEFT_lastDoorReqSourceRear 4 "DOOR_REQUEST_SOURCE_ECU" 3 "DOOR_REQUEST_SOURCE_VCSEC" 2 "DOOR_REQUEST_SOURCE_EXTERIOR_HANDLE" 1 "DOOR_REQUEST_SOURCE_INTERIOR_BUTTON" 0 "DOOR_REQUEST_SOURCE_UNKNOWN" ;
VAL_ 258 VCLEFT_mirrorState 5 "MIRROR_STATE_CALIBRATION" 4 "MIRROR_STATE_RECALL" 3 "MIRROR_STATE_FOLD_UNFOLD" 2 "MIRROR_STATE_TILT_Y" 1 "MIRROR_STATE_TILT_X" 0 "MIRROR_STATE_IDLE" ;
VAL_ 258 VCLEFT_mirrorFoldState 4 "MIRROR_FOLD_STATE_UNFOLDING" 3 "MIRROR_FOLD_STATE_FOLDING" 2 "MIRROR_FOLD_STATE_UNFOLDED" 1 "MIRROR_FOLD_STATE_FOLDED" 0 "MIRROR_FOLD_STATE_UNKNOWN" ;
VAL_ 258 VCLEFT_mirrorRecallState 5 "MIRROR_RECALL_STATE_RECALLING_STOPPED" 4 "MIRROR_RECALL_STATE_RECALLING_FAILED" 3 "MIRROR_RECALL_STATE_RECALLING_COMPLETE" 2 "MIRROR_RECALL_STATE_RECALLING_AXIS_2" 1 "MIRROR_RECALL_STATE_RECALLING_AXIS_1" 0 "MIRROR_RECALL_STATE_INIT" ;
VAL_ 258 VCLEFT_mirrorHeatState 4 "HEATER_STATE_FAULT" 3 "HEATER_STATE_OFF_UNAVAILABLE" 2 "HEATER_STATE_OFF" 1 "HEATER_STATE_ON" 0 "HEATER_STATE_SNA" ;
VAL_ 546 VCLEFT_cdpRequestState 1 "EPB_CDP_REQUEST_VALID" 0 "EPB_CDP_REQUEST_INVALID" ;
VAL_ 546 VCLEFT_epbmSystemStatusQF 1 "EPBM_SYSTEM_STATUS_INVALID" 0 "EPBM_SYSTEM_STATUS_VALID" ;
VAL_ 546 VCLEFT_epbmUnitStatus 23 "EPB_STATUS_COUNT" 22 "EPB_STATUS_AUTONOMY_OPEN" 21 "EPB_STATUS_FREE_ROLL_MODE" 20 "EPB_STATUS_DYNAMIC_PARKING" 19 "EPB_STATUS_EXTERNAL_PARKING" 18 "EPB_STATUS_RELEASING_FOR_EXTERNAL_PARK" 17 "EPB_STATUS_EXTERNAL_DYNAMIC" 16 "EPB_STATUS_SUMMON_PARKING" 15 "EPB_STATUS_SUMMON_RELEASING" 14 "EPB_STATUS_SUMMON" 13 "EPB_STATUS_WINCHMODE_PENDING" 12 "EPB_STATUS_PARK_PENDING" 11 "EPB_STATUS_SERVICE_RELEASING" 10 "EPB_STATUS_RELEASING" 9 "EPB_STATUS_DYNAMIC_APPLYING" 8 "EPB_STATUS_PARKING" 7 "EPB_STATUS_WINCHMODE_RELEASING" 6 "EPB_STATUS_WINCHMODE" 5 "EPB_STATUS_SERVICE" 4 "EPB_STATUS_START" 3 "EPB_STATUS_PARK" 2 "EPB_STATUS_DYNAMIC" 1 "EPB_STATUS_OPEN" 0 "EPB_STATUS_UNKNOWN" ;
VAL_ 546 VCLEFT_epbmCdpState 2 "EPB_CDP_STATE_FAULT" 1 "EPB_CDP_STATE_VALID" 0 "EPB_CDP_STATE_UNKNOWN" ;
VAL_ 778 VCLEFT_frontOccupancyStatus 7 "SEAT_OCCUPANCY_SNA" 3 "SEAT_NOT_CONFIGURED" 2 "SEAT_OCCUPANCY_FAULTED" 1 "SEAT_OCCUPIED" 0 "SEAT_UNOCCUPIED" ;
VAL_ 778 VCLEFT_frontBuckleStatus 3 "SEAT_BELT_BUCKLE_NOT_CONFIGURED" 2 "SEAT_BELT_BUCKLE_STATUS_FAULTED" 1 "SEAT_BELT_BUCKLE_STATUS_LATCHED" 0 "SEAT_BELT_BUCKLE_STATUS_UNLATCHED" ;
VAL_ 778 VCLEFT_rearLeftOccupancyStatus 3 "SEAT_NOT_CONFIGURED" 2 "SEAT_OCCUPANCY_FAULTED" 1 "SEAT_OCCUPIED" 0 "SEAT_UNOCCUPIED" ;
VAL_ 778 VCLEFT_rearCenterOccupancyStatus 3 "SEAT_NOT_CONFIGURED" 2 "SEAT_OCCUPANCY_FAULTED" 1 "SEAT_OCCUPIED" 0 "SEAT_UNOCCUPIED" ;
VAL_ 778 VCLEFT_rearRightOccupancyStatus 3 "SEAT_NOT_CONFIGURED" 2 "SEAT_OCCUPANCY_FAULTED" 1 "SEAT_OCCUPIED" 0 "SEAT_UNOCCUPIED" ;
VAL_ 778 VCLEFT_rearLeftBuckleStatus 3 "SEAT_BELT_BUCKLE_NOT_CONFIGURED" 2 "SEAT_BELT_BUCKLE_STATUS_FAULTED" 1 "SEAT_BELT_BUCKLE_STATUS_LATCHED" 0 "SEAT_BELT_BUCKLE_STATUS_UNLATCHED" ;
VAL_ 778 VCLEFT_rearCenterBuckleStatus 3 "SEAT_BELT_BUCKLE_NOT_CONFIGURED" 2 "SEAT_BELT_BUCKLE_STATUS_FAULTED" 1 "SEAT_BELT_BUCKLE_STATUS_LATCHED" 0 "SEAT_BELT_BUCKLE_STATUS_UNLATCHED" ;
VAL_ 778 VCLEFT_seatTrackPosition 7 "SEAT_TRACK_POSITION_SNA" 3 "SEAT_TRACK_POSITION_FAULTED" 2 "SEAT_TRACK_POSITION_NOT_CONFIGURED" 1 "SEAT_TRACK_POSITION_REARWARD" 0 "SEAT_TRACK_POSITION_FORWARD" ;
VAL_ 778 VCLEFT_3RowLeftABStatus 2 "AIRBAG_STATE_SNA" 1 "AIRBAG_SUPPRESS" 0 "AIRBAG_ALLOW" ;
VAL_ 778 VCLEFT_3RowLeftBuckleStatus 3 "SEAT_BELT_BUCKLE_NOT_CONFIGURED" 2 "SEAT_BELT_BUCKLE_STATUS_FAULTED" 1 "SEAT_BELT_BUCKLE_STATUS_LATCHED" 0 "SEAT_BELT_BUCKLE_STATUS_UNLATCHED" ;
VAL_ 1124 VCRIGHT_AP_hvacState1HzIndex 1 "END" 0 "0" ;
VAL_ 1124 VCRIGHT_AP_tempCameraModele_0001 255 "SNA" ;
VAL_ 1124 VCRIGHT_AP_tempCameraModeledWind 255 "SNA" ;
VAL_ 1124 VCRIGHT_AP_cameraModeledWin_0001 127 "SNA" ;
VAL_ 1124 VCRIGHT_AP_cameraModeledWindshie 127 "SNA" ;
VAL_ 1124 VCRIGHT_AP_cameraModeledPocketWa 1023 "SNA" ;
VAL_ 1124 VCRIGHT_AP_humidityModelInitStat 21 "INIT_STATUS_LIMP_FORWARD_CALC_AMBIENT_PROBE_AND_THS" 20 "INIT_STATUS_LIMP_FORWARD_CALC_WEATHER_PROBE_AND_THS" 19 "INIT_STATUS_LIMP_FORWARD_CALC_PROBE_AND_THS" 18 "INIT_STATUS_LIMP_FORWARD_CALC_AMBIENT_AND_THS" 17 "INIT_STATUS_LIMP_FORWARD_CALC_WEATHER_AND_THS" 16 "INIT_STATUS_LIMP_FORWARD_CALC_THS_ONLY" 15 "INIT_STATUS_LIMP_FORWARD_CALC_AMBIENT_AND_PROBE" 14 "INIT_STATUS_LIMP_FORWARD_CALC_WEATHER_AND_PROBE" 13 "INIT_STATUS_LIMP_FORWARD_CALC_PROBE_ONLY" 12 "INIT_STATUS_LIMP_FORWARD_CALC_AMBIENT_ONLY" 11 "INIT_STATUS_LIMP_FORWARD_CALC_WEATHER_ONLY" 10 "INIT_STATUS_LIMP_FROM_SENSORS_PROBE_ONLY" 9 "INIT_STATUS_FROM_FORWARD_CALC" 8 "INIT_STATUS_FROM_SENSORS" 7 "INIT_STATUS_FAULTED_MULTI_CYCLE_SENSOR_INVALID" 6 "INIT_STATUS_FAULTED_ALL_INVALID" 5 "INIT_STATUS_FAULTED_FORWARD_CALC_WEATHER_AND_AMBIENT_INVALID" 4 "INIT_STATUS_FAULTED_FROM_SENSORS_THS_INVALID" 3 "INIT_STATUS_WAITING_FOR_SENSORS_API" 2 "INIT_STATUS_WAITING_FOR_CABIN_MODEL_INIT" 1 "INIT_STATUS_WAITING_FOR_GTW" 0 "INIT_STATUS_UNKNOWN" ;
VAL_ 1124 VCRIGHT_AP_humidityModelStatus 19 "STATUS_RUNNING_FAULTED_WEATHER_AND_AMBIENT_INVALID" 18 "STATUS_RUNNING_LIMP_THS_DIRECTLY_NO_PROBE_LIMIT" 17 "STATUS_RUNNING_LIMP_THS_DIRECTLY_WITH_PROBE_LIMIT" 16 "STATUS_RUNNING_LIMP_THS_ONLY_SUBSTITUTED" 15 "STATUS_RUNNING_LIMP_AMBIENT_AND_PROBE_SUBSTITUTED_NO_THS_FEEDBACK" 14 "STATUS_RUNNING_LIMP_WEATHER_AND_PROBE_SUBSTITUTED_NO_THS_FEEDBACK" 13 "STATUS_RUNNING_LIMP_AMBIENT_AND_PROBE_SUBSTITUTED_WITH_THS_FEEDBACK" 12 "STATUS_RUNNING_LIMP_WEATHER_AND_PROBE_SUBSTITUTED_WITH_THS_FEEDBACK" 11 "STATUS_RUNNING_LIMP_EVAP_SUBSTITUTED_NO_THS_FEEDBACK" 10 "STATUS_RUNNING_LIMP_PROBE_SUBSTITUTED_NO_THS_FEEDBACK" 9 "STATUS_RUNNING_LIMP_AMBIENT_SUBSTITUTED_NO_THS_FEEDBACK" 8 "STATUS_RUNNING_LIMP_WEATHER_SUBSTITUTED_NO_THS_FEEDBACK" 7 "STATUS_RUNNING_LIMP_EVAP_SUBSTITUTED_WITH_THS_FEEDBACK" 6 "STATUS_RUNNING_LIMP_PROBE_SUBSTITUTED_WITH_THS_FEEDBACK" 5 "STATUS_RUNNING_LIMP_AMBIENT_SUBSTITUTED_WITH_THS_FEEDBACK" 4 "STATUS_RUNNING_LIMP_WEATHER_SUBSTITUTED_WITH_THS_FEEDBACK" 3 "STATUS_RUNNING_RECOVERED_CATCHUP" 2 "STATUS_RUNNING_PAUSED_AWAITING_RECOVERY" 1 "STATUS_RUNNING_NOMINAL" 0 "STATUS_UNKNOWN" ;
VAL_ 259 VCRIGHT_doorClosureStatusFront 8 "CLOSURE_STATUS_FAULT" 2 "CLOSURE_STATUS_CLOSED" 1 "CLOSURE_STATUS_OPEN" 0 "CLOSURE_STATUS_SNA" ;
VAL_ 259 VCRIGHT_doorClosureStatusRear 8 "CLOSURE_STATUS_FAULT" 2 "CLOSURE_STATUS_CLOSED" 1 "CLOSURE_STATUS_OPEN" 0 "CLOSURE_STATUS_SNA" ;
VAL_ 259 VCRIGHT_frontLatchStatus 8 "LATCH_FAULT" 7 "LATCH_DEFAULT" 6 "LATCH_TIMEOUT" 5 "LATCH_AJAR" 4 "LATCH_OPENING" 3 "LATCH_CLOSING" 2 "LATCH_CLOSED" 1 "LATCH_OPENED" 0 "LATCH_SNA" ;
VAL_ 259 VCRIGHT_rearLatchStatus 8 "LATCH_FAULT" 7 "LATCH_DEFAULT" 6 "LATCH_TIMEOUT" 5 "LATCH_AJAR" 4 "LATCH_OPENING" 3 "LATCH_CLOSING" 2 "LATCH_CLOSED" 1 "LATCH_OPENED" 0 "LATCH_SNA" ;
VAL_ 259 VCRIGHT_lastDoorReqSourceFront 4 "DOOR_REQUEST_SOURCE_ECU" 3 "DOOR_REQUEST_SOURCE_VCSEC" 2 "DOOR_REQUEST_SOURCE_EXTERIOR_HANDLE" 1 "DOOR_REQUEST_SOURCE_INTERIOR_BUTTON" 0 "DOOR_REQUEST_SOURCE_UNKNOWN" ;
VAL_ 259 VCRIGHT_lastDoorReqSourceRear 4 "DOOR_REQUEST_SOURCE_ECU" 3 "DOOR_REQUEST_SOURCE_VCSEC" 2 "DOOR_REQUEST_SOURCE_EXTERIOR_HANDLE" 1 "DOOR_REQUEST_SOURCE_INTERIOR_BUTTON" 0 "DOOR_REQUEST_SOURCE_UNKNOWN" ;
VAL_ 259 VCRIGHT_mirrorState 5 "MIRROR_STATE_CALIBRATION" 4 "MIRROR_STATE_RECALL" 3 "MIRROR_STATE_FOLD_UNFOLD" 2 "MIRROR_STATE_TILT_Y" 1 "MIRROR_STATE_TILT_X" 0 "MIRROR_STATE_IDLE" ;
VAL_ 259 VCRIGHT_mirrorFoldState 4 "MIRROR_FOLD_STATE_UNFOLDING" 3 "MIRROR_FOLD_STATE_FOLDING" 2 "MIRROR_FOLD_STATE_UNFOLDED" 1 "MIRROR_FOLD_STATE_FOLDED" 0 "MIRROR_FOLD_STATE_UNKNOWN" ;
VAL_ 259 VCRIGHT_trunkLatchStatus 8 "LATCH_FAULT" 7 "LATCH_DEFAULT" 6 "LATCH_TIMEOUT" 5 "LATCH_AJAR" 4 "LATCH_OPENING" 3 "LATCH_CLOSING" 2 "LATCH_CLOSED" 1 "LATCH_OPENED" 0 "LATCH_SNA" ;
VAL_ 259 VCRIGHT_mirrorRecallState 5 "MIRROR_RECALL_STATE_RECALLING_STOPPED" 4 "MIRROR_RECALL_STATE_RECALLING_FAILED" 3 "MIRROR_RECALL_STATE_RECALLING_COMPLETE" 2 "MIRROR_RECALL_STATE_RECALLING_AXIS_2" 1 "MIRROR_RECALL_STATE_RECALLING_AXIS_1" 0 "MIRROR_RECALL_STATE_INIT" ;
VAL_ 611 VCRIGHT_cdpRequestState 1 "EPB_CDP_REQUEST_VALID" 0 "EPB_CDP_REQUEST_INVALID" ;
VAL_ 611 VCRIGHT_epbmSystemStatusQF 1 "EPBM_SYSTEM_STATUS_INVALID" 0 "EPBM_SYSTEM_STATUS_VALID" ;
VAL_ 611 VCRIGHT_epbmUnitStatus 23 "EPB_STATUS_COUNT" 22 "EPB_STATUS_AUTONOMY_OPEN" 21 "EPB_STATUS_FREE_ROLL_MODE" 20 "EPB_STATUS_DYNAMIC_PARKING" 19 "EPB_STATUS_EXTERNAL_PARKING" 18 "EPB_STATUS_RELEASING_FOR_EXTERNAL_PARK" 17 "EPB_STATUS_EXTERNAL_DYNAMIC" 16 "EPB_STATUS_SUMMON_PARKING" 15 "EPB_STATUS_SUMMON_RELEASING" 14 "EPB_STATUS_SUMMON" 13 "EPB_STATUS_WINCHMODE_PENDING" 12 "EPB_STATUS_PARK_PENDING" 11 "EPB_STATUS_SERVICE_RELEASING" 10 "EPB_STATUS_RELEASING" 9 "EPB_STATUS_DYNAMIC_APPLYING" 8 "EPB_STATUS_PARKING" 7 "EPB_STATUS_WINCHMODE_RELEASING" 6 "EPB_STATUS_WINCHMODE" 5 "EPB_STATUS_SERVICE" 4 "EPB_STATUS_START" 3 "EPB_STATUS_PARK" 2 "EPB_STATUS_DYNAMIC" 1 "EPB_STATUS_OPEN" 0 "EPB_STATUS_UNKNOWN" ;
VAL_ 611 VCRIGHT_epbmCdpState 2 "EPB_CDP_STATE_FAULT" 1 "EPB_CDP_STATE_VALID" 0 "EPB_CDP_STATE_UNKNOWN" ;
VAL_ 794 VCRIGHT_frontOccupancyStatus 7 "SEAT_OCCUPANCY_SNA" 3 "SEAT_NOT_CONFIGURED" 2 "SEAT_OCCUPANCY_FAULTED" 1 "SEAT_OCCUPIED" 0 "SEAT_UNOCCUPIED" ;
VAL_ 794 VCRIGHT_frontBuckleStatus 3 "SEAT_BELT_BUCKLE_NOT_CONFIGURED" 2 "SEAT_BELT_BUCKLE_STATUS_FAULTED" 1 "SEAT_BELT_BUCKLE_STATUS_LATCHED" 0 "SEAT_BELT_BUCKLE_STATUS_UNLATCHED" ;
VAL_ 794 VCRIGHT_rearCenterBuckleStatus 3 "SEAT_BELT_BUCKLE_NOT_CONFIGURED" 2 "SEAT_BELT_BUCKLE_STATUS_FAULTED" 1 "SEAT_BELT_BUCKLE_STATUS_LATCHED" 0 "SEAT_BELT_BUCKLE_STATUS_UNLATCHED" ;
VAL_ 794 VCRIGHT_rearRightBuckleStatus 3 "SEAT_BELT_BUCKLE_NOT_CONFIGURED" 2 "SEAT_BELT_BUCKLE_STATUS_FAULTED" 1 "SEAT_BELT_BUCKLE_STATUS_LATCHED" 0 "SEAT_BELT_BUCKLE_STATUS_UNLATCHED" ;
VAL_ 794 VCRIGHT_rearRightOccupancyStatus 3 "SEAT_NOT_CONFIGURED" 2 "SEAT_OCCUPANCY_FAULTED" 1 "SEAT_OCCUPIED" 0 "SEAT_UNOCCUPIED" ;
VAL_ 794 VCRIGHT_3RowLeftBuckleStatus 3 "SEAT_BELT_BUCKLE_NOT_CONFIGURED" 2 "SEAT_BELT_BUCKLE_STATUS_FAULTED" 1 "SEAT_BELT_BUCKLE_STATUS_LATCHED" 0 "SEAT_BELT_BUCKLE_STATUS_UNLATCHED" ;
VAL_ 794 VCRIGHT_3RowRightBuckleStatus 3 "SEAT_BELT_BUCKLE_NOT_CONFIGURED" 2 "SEAT_BELT_BUCKLE_STATUS_FAULTED" 1 "SEAT_BELT_BUCKLE_STATUS_LATCHED" 0 "SEAT_BELT_BUCKLE_STATUS_UNLATCHED" ;
VAL_ 794 VCRIGHT_3RowLeftOccupancyStatus 3 "SEAT_NOT_CONFIGURED" 2 "SEAT_OCCUPANCY_FAULTED" 1 "SEAT_OCCUPIED" 0 "SEAT_UNOCCUPIED" ;
VAL_ 794 VCRIGHT_3RowRightOccupancyStatus 3 "SEAT_NOT_CONFIGURED" 2 "SEAT_OCCUPANCY_FAULTED" 1 "SEAT_OCCUPIED" 0 "SEAT_UNOCCUPIED" ;
VAL_ 794 VCRIGHT_seatTrackPosition 7 "SEAT_TRACK_POSITION_SNA" 3 "SEAT_TRACK_POSITION_FAULTED" 2 "SEAT_TRACK_POSITION_NOT_CONFIGURED" 1 "SEAT_TRACK_POSITION_REARWARD" 0 "SEAT_TRACK_POSITION_FORWARD" ;
VAL_ 794 VCRIGHT_occupantClassification 7 "SEAT_OCCUPANT_CLASSIFICATON_SNA" 6 "SEAT_OCCUPANT_CLASSIFICATON_OUT_OF_POSITION" 5 "SEAT_OCCUPANT_CLASSIFICATON_NOT_CONFIGURED" 4 "SEAT_OCCUPANT_CLASSIFICATON_INIT" 3 "SEAT_OCCUPANT_CLASSIFICATON_LARGE" 2 "SEAT_OCCUPANT_CLASSIFICATON_SMALL" 1 "SEAT_OCCUPANT_CLASSIFICATON_INHIBIT" 0 "SEAT_OCCUPANT_CLASSIFICATON_EMPTY" ;
VAL_ 794 VCRIGHT_occupantClassificationQF 1 "SEAT_OCCUPANT_CLASSIFICATON_NOT_FAULTED" 0 "SEAT_OCCUPANT_CLASSIFICATON_FAULTED" ;
VAL_ 794 VCRIGHT_classificationEnabled 1 "VCRIGHT_CLASSIFICATION_SOURCE" 0 "OCS1P_CLASSIFICATION_SOURCE" ;
VAL_ 794 VCRIGHT_classificationEnabledQF 1 "CLASSIFICATION_ENABLED_NOT_FAULTED" 0 "CLASSIFICATION_ENABLED_FAULTED" ;
VAL_ 794 VCRIGHT_3RowRightABStatus 2 "AIRBAG_STATE_SNA" 1 "AIRBAG_SUPPRESS" 0 "AIRBAG_ALLOW" ;
